VERSION "Version"

NS_ :

BS_:

BU_: Tester CCU INU ADC RRR RLR CCURT1 CCURT2 ZCUF ZCUL ZCUR ZCUT EMS IDM DCDC DCDCI IPS NIDU DCU2 OBC OPC LPC CPC EMCM GCU DCU IPU BMS EOP EVCC DCDC2 EDL SRS ECS EPS EPB RBM IBCS ICM IID IDC AMP WHUD ARHUD IMR FIMR CD IFC FAPA PAS PCS SCMF SCMR SCMRL SCMRR MFS DRM FCP RCP LBMSAD AVAS DLPFL FBLCM FLISD FLLCM FRLCM RLLCMA RLLCMB RRLCMA RRLCMB RLISD DLPML DLPMR TRM PSDL PSDR FLDCM FRDCM HVSPRL HVSPRR RFR SBM WCM ETC TBOX2 TBOX RLBMS EBU FLPDM RLPDM FRPDM RRPDM FLOAR FROAR RLOAR RROAR EOSL EOSR EOST PRBU RT1_C0 OTAWL RT2_C3 IDUR PHUDD RAS CBM PLGM TMC LPC2 SAS RCICP SCMRM SCMT SLMRL SLMRR IDU RRISD DSASBM LBMS RT1_C1

BO_ 825 CCU_5: 64 CCU
 SG_ WW_FwpFaultSt : 34|1@0+ (1,0) [0|1] ""  ICM,IDC,ADC,IFC,SCMF
 SG_ WW_RwpFaultSt : 33|1@0+ (1,0) [0|1] ""  ICM,IDC,ADC,IFC,SCMF
 SG_ WW_FwshFaultSt : 32|1@0+ (1,0) [0|1] ""  ICM,IDC,ADC,IFC,SCMF
 SG_ WW_RwshFaultSt : 47|1@0+ (1,0) [0|1] ""  ICM,IDC,ADC,IFC,SCMF
 SG_ WW_FwpAutoModeSt : 46|1@0+ (1,0) [0|1] ""  ICM,IDC,ADC,IFC,SCMF
 SG_ WW_RainFallLevel : 391|4@0+ (1,0) [0|15] ""  CCURT1,RT1_C0,RT1_C1,ZCUF,ZCUL,ZCUR,ZCUT,ICM,IDC,ADC,IFC,SCMF
 SG_ RLS_LightOnReq : 387|1@0+ (1,0) [0|1] ""  ZCUL,ZCUR,IDC,ADC,IFC,SCMF,FLISD,FLLCM,FRLCM,RLLCMA,RLLCMB,RRLCMA,RRLCMB
 SG_ RLS_LampOnReqValid : 386|1@0+ (1,0) [0|1] ""  IDC,ADC,IFC,SCMF
 SG_ RLS_WiperSpd : 385|4@0+ (1,0) [0|15] ""  IDC,ADC,IFC,SCMF
 SG_ RLS_AMBBrightness : 298|14@0+ (6,0) [0|98286] "Lux"  IDC,WHUD,ARHUD,ADC,IFC,SCMF
 SG_ RLS_FWBrightness : 413|14@0+ (6,0) [0|98286] ""  IDC,WHUD,ARHUD,ADC,IFC,SCMF
 SG_ RLS_RainfallLevel : 439|4@0+ (1,0) [0|15] ""  ICM,IDC,ADC,IFC,SCMF
 SG_ RLS_RSErr : 400|1@0+ (1,0) [0|1] ""  ICM,IDC,ADC,IFC,SCMF
 SG_ RLS_LSErr : 401|1@0+ (1,0) [0|1] ""  ZCUR,ICM,IDC,ADC,IFC,SCMF
 SG_ PM_AUTHPstState : 469|1@0+ (1,0) [0|1] ""  CCURT1,RT1_C0,ADC,IFC,SCMF
 SG_ CCU_FuncReq_SentryMod : 146|1@0+ (1,0) [0|1] ""  IDC,ADC,SCMF
 SG_ RLS_WindShieldHum : 119|8@0+ (0.5,-0.5) [0|100] "%"  ADC,SCMF
 SG_ RLS_WindShieldTem : 127|8@0+ (0.5,-40) [-40|86.5] "℃"  ADC,SCMF
 SG_ RLS_DewPoint : 135|8@0+ (0.5,-40) [-40|86.5] "℃"  ADC,SCMF
 SG_ CCU_ModeSuppressSts : 369|2@0+ (1,0) [0|2] ""  IDC,ADC,SCMF
 SG_ RLS_HUTErr : 426|1@0+ (1,0) [0|1] ""  ADC,SCMF
 SG_ SR_SunroofCurrentPst : 511|8@0+ (0.5,0) [0|255] "%"  ZCUT,IDC,IMR,FIMR,ADC,SCMF

BO_ 291 CCU_6: 64 CCU
 SG_ CCU_6_CRC : 7|16@0+ (1,0) [0|65535] ""  ZCUF,ZCUL,ADC,IFC,FAPA,PLGM
 SG_ CCU_6_Counter : 23|8@0+ (1,0) [0|255] ""  ZCUF,ZCUL,ADC,IFC,FAPA,PLGM
 SG_ ATWS_ATWSAlarmReq : 31|2@0+ (1,0) [0|3] ""  CCURT1,RT1_C0,ICM,IDC,ADC,IFC,FAPA
 SG_ ATWS_ATWSSt : 26|3@0+ (1,0) [0|7] ""  CCURT1,RT1_C0,RT1_C1,OTAWL,ZCUR,ICM,IDC,ADC,IFC,FAPA,RRR,RLR,PLGM
 SG_ WW_FrontWasherCmd : 39|2@0+ (1,0) [0|3] ""  CCURT1,ZCUF,ZCUL,ADC,IFC,FAPA
 SG_ WW_FrtWiperAutoAvl : 56|1@0+ (1,0) [0|1] ""  ADC,IFC,FAPA
 SG_ WW_FrontWiperCmd_Speed : 85|2@0+ (1,0) [0|3] ""  CCURT1,ZCUF,ZCUL,ADC,IFC,FAPA
 SG_ WW_RearWiperCtrlSt : 107|3@0+ (1,0) [0|7] ""  CCURT1,ZCUF,ZCUL,ZCUR,ZCUT,ICM,IDC,ADC,IFC,FAPA
 SG_ WW_FrontWiperCtrlSt : 111|3@0+ (1,0) [0|7] ""  CCURT1,ZCUF,ZCUL,ZCUR,ZCUT,EMS,ICM,IDC,ADC,IFC,FAPA
 SG_ WW_FrontWiperCtrlSrc : 115|3@0+ (1,0) [0|7] ""  CCURT1,ZCUF,ZCUL,ZCUR,ZCUT,ICM,IDC,ADC,FAPA
 SG_ WW_RearWiperCtrlSrc : 112|3@0+ (1,0) [0|7] ""  CCURT1,ZCUF,ZCUL,ZCUR,ZCUT,ICM,IDC,ADC,IFC,FAPA
 SG_ WW_RearCamWasherVKResp : 125|2@0+ (1,0) [0|3] ""  ICM,IDC,ADC,IFC,FAPA
 SG_ WW_RearCamWasherVRResp : 123|2@0+ (1,0) [0|3] ""  ICM,IDC,ADC,IFC,FAPA

BO_ 865 CCU_7: 64 CCU
 SG_ EL_ReverseLightCtrlCmd : 30|1@0+ (1,0) [0|1] ""  CCURT1,ZCUR,ZCUT,ADC,IFC,FAPA,TRM
 SG_ EL_SideBrkLightCtrlCmd : 29|1@0+ (1,0) [0|1] ""  CCURT1,RT1_C1,ZCUF,ZCUL,ZCUR,ZCUT,IDC,ADC,IFC,FAPA,PCS,RLLCMA,RLLCMB,RRLCMA,RRLCMB,TRM
 SG_ EL_LeftLowBeamCtrlCmd : 36|1@0+ (1,0) [0|1] ""  CCURT1,ZCUF,ZCUL,ADC,IFC,FAPA
 SG_ EL_RightLowBeamCtrlCmd : 35|1@0+ (1,0) [0|1] ""  CCURT1,ZCUF,ZCUL,ADC,IFC,FAPA
 SG_ EL_PositionLightCtrlSource : 34|3@0+ (1,0) [0|7] ""  CCURT1,ZCUF,ZCUL,ZCUR,ZCUT,ICM,IDC,RCICP,ADC,IFC,FAPA,MFS,FCP,TRM
 SG_ EL_LeftHighBeamCtrlCmd : 55|1@0+ (1,0) [0|1] ""  CCURT1,ZCUF,ZCUL,ADC,IFC,FAPA
 SG_ EL_RightHighBeamCtrlCmd : 54|1@0+ (1,0) [0|1] ""  CCURT1,ZCUF,ZCUL,ADC,IFC,FAPA
 SG_ EL_LowBeamCtrlSource : 53|3@0+ (1,0) [0|7] ""  CCURT1,ZCUF,ZCUL,ZCUR,ZCUT,ADC,IFC,FAPA
 SG_ EL_RearFogLightCtrlSource : 50|3@0+ (1,0) [0|7] ""  CCURT1,ZCUR,ZCUT,ADC,IFC,FAPA,TRM
 SG_ EL_HighBeamCtrlSource : 61|3@0+ (1,0) [0|7] ""  CCURT1,ZCUF,ZCUL,ADC,IFC,FAPA
 SG_ EL_FrontFogLightCtrlSource : 71|3@0+ (1,0) [0|7] ""  CCURT1,ZCUF,ZCUL,ZCUR,ZCUT,ADC,IFC,FAPA
 SG_ EL_LicencePlateLightCtrlSource : 84|3@0+ (1,0) [0|7] ""  CCURT1,ZCUR,ZCUT,ADC,IFC,FAPA
 SG_ EL_FlasherCtrlSource : 95|4@0+ (1,0) [0|15] ""  CCURT1,RT1_C0,ZCUF,ZCUL,ZCUR,ZCUT,SRS,ADC,IFC,FAPA,DLPML,DLPMR,TRM
 SG_ EL_FADASLightCtrlCmd : 130|1@0+ (1,0) [0|1] ""  ZCUF,ZCUL,ZCUR,ZCUT,ADC,FAPA
 SG_ EL_RADASLightCtrlCmd : 131|1@0+ (1,0) [0|1] ""  ZCUF,ZCUL,ZCUR,ZCUT,ADC,FAPA
 SG_ EL_IHBColourSt : 155|2@0+ (1,0) [0|3] ""  IID,IDC,PHUDD,ADC,IFC,FAPA
 SG_ EL_AutoHighBeamCtrlSt : 128|1@0+ (1,0) [0|1] ""  CCURT1,ADC,IFC,FAPA
 SG_ EL_ADBEnable : 252|1@0+ (1,0) [0|1] ""  IDC,ADC,IFC,FAPA
 SG_ EL_ADC_2_VERFailFlag : 175|1@0+ (1,0) [0|1] ""  ADC,IFC,FAPA
 SG_ EL_ADC_4_New_VERFailFlag : 174|1@0+ (1,0) [0|1] ""  ADC,IFC,FAPA
 SG_ EL_ADC_8_VERFailFlag : 173|1@0+ (1,0) [0|1] ""  ADC,IFC,FAPA
 SG_ EL_HeadLightLevelingSWSt : 467|4@0+ (1,0) [0|15] ""  CCURT1,ICM,IDC,ADC,IFC,FAPA
 SG_ EL_LeftTurnLightStForDisp : 478|1@0+ (1,0) [0|1] ""  CCURT1,IID,IDC,PHUDD,ADC,IFC,FAPA,RRR,RLR,PCS,DLPML,DLPMR
 SG_ EL_RightTurnLightStForDisp : 477|1@0+ (1,0) [0|1] ""  CCURT1,IID,IDC,PHUDD,ADC,IFC,FAPA,RRR,RLR,PCS,DLPML,DLPMR
 SG_ EL_PositionLightStForDisp : 476|1@0+ (1,0) [0|1] ""  CCURT1,RT1_C1,ZCUL,ZCUR,ZCUT,IID,IDC,PHUDD,WHUD,ARHUD,ADC,IFC,FAPA,PCS,MFS,FCP
 SG_ EL_FrontFogLightStForDisp : 475|1@0+ (1,0) [0|1] ""  CCURT1,IDC,ADC,IFC,FAPA,PCS
 SG_ EL_RearFogLightStForDisp : 474|1@0+ (1,0) [0|1] ""  CCURT1,ZCUR,IDC,ADC,IFC,FAPA,PCS,RCP
 SG_ EL_LowBeamStForDisp : 473|1@0+ (1,0) [0|1] ""  CCURT1,RT1_C1,IDC,ADC,IFC,FAPA,PCS,DLPML,DLPMR
 SG_ EL_HighBeamStForDisp : 472|1@0+ (1,0) [0|1] ""  CCURT1,RT1_C1,IID,IDC,PHUDD,ADC,IFC,FAPA,PCS
 SG_ EL_HeadLightSWSt : 510|2@0+ (1,0) [0|3] ""  ZCUR,IDC,ADC,FAPA

BO_ 293 CCU_8: 64 CCU
 SG_ TPMS_FrontLeftTireBlowout : 193|2@0+ (1,0) [0|3] ""  CCURT1,RT1_C0,RT1_C1,IDC,ADC,IFC,FAPA
 SG_ TPMS_FrontRightTireBlowout : 195|2@0+ (1,0) [0|3] ""  CCURT1,RT1_C0,RT1_C1,IDC,ADC,IFC,FAPA
 SG_ TPMS_RearRightTireBlowout : 197|2@0+ (1,0) [0|3] ""  CCURT1,RT1_C0,RT1_C1,IDC,ADC,IFC,FAPA
 SG_ TPMS_RearLeftTireBlowout : 199|2@0+ (1,0) [0|3] ""  CCURT1,RT1_C0,RT1_C1,IDC,ADC,IFC,FAPA
 SG_ TPMS_FrontLeftTirePressure : 207|8@0+ (1.373,0) [0|350.115] "kpa"  CCURT1,RT1_C0,RT1_C1,ICM,IDC,ADC,FAPA
 SG_ TPMS_FrontRightTirePressure : 215|8@0+ (1.373,0) [0|350.115] "kpa"  CCURT1,RT1_C0,RT1_C1,ICM,IDC,ADC,FAPA
 SG_ TPMS_RearRightTirePressure : 223|8@0+ (1.373,0) [0|350.115] "kpa"  CCURT1,RT1_C0,RT1_C1,ICM,IDC,ADC,FAPA
 SG_ TPMS_RearLeftTirePressure : 231|8@0+ (1.373,0) [0|350.115] "kpa"  CCURT1,RT1_C0,RT1_C1,ICM,IDC,ADC,FAPA
 SG_ TPMS_TireWarningLamp : 295|1@0+ (1,0) [0|1] ""  CCURT1,RT1_C0,RT1_C1,SRS,ICM,IID,IDC,PHUDD,ADC,IFC,FAPA
 SG_ TPMS_SystemWarningLamp : 310|1@0+ (1,0) [0|1] ""  CCURT1,RT1_C0,RT1_C1,SRS,ICM,IID,IDC,PHUDD,ADC,IFC,FAPA

BO_ 294 CCU_9: 64 CCU
 SG_ LCK_DriverDoorAjarSt : 31|1@0+ (1,0) [0|1] ""  CCURT1,RT1_C0,RT1_C1,OTAWL,ZCUF,ZCUL,ZCUR,ZCUT,ECS,IBCS,ICM,IDC,IMR,FIMR,ADC,IFC,FAPA,PCS
 SG_ LCK_PassengerDoorAjarSt : 30|1@0+ (1,0) [0|1] ""  CCURT1,RT1_C0,OTAWL,ZCUL,ZCUR,ECS,ICM,IDC,IMR,FIMR,ADC,IFC,FAPA,PCS
 SG_ LCK_DriverDoorLockSt : 29|1@0+ (1,0) [0|1] ""  CCURT1,RT1_C0,OTAWL,ZCUL,ZCUR,ZCUT,ECS,ICM,IDC,IMR,FIMR,ADC,IFC,FAPA
 SG_ LCK_PassengerDoorLockSt : 28|1@0+ (1,0) [0|1] ""  CCURT1,RT1_C0,OTAWL,ZCUL,ZCUR,ZCUT,ECS,ICM,IDC,IMR,FIMR,ADC,IFC,FAPA
 SG_ LCK_VehicleDoorAjarSt : 27|2@0+ (1,0) [0|3] ""  CCURT1,RT1_C1,OTAWL,ZCUL,ZCUR,ZCUT,IDC,ADC,IFC,FAPA
 SG_ LCK_VehicleDoorLockSt : 25|2@0+ (1,0) [0|3] ""  CCURT1,RT1_C0,RT1_C1,OTAWL,ZCUF,ZCUL,ZCUR,ZCUT,ICM,IDC,IMR,FIMR,ADC,IFC,FAPA,PRBU
 SG_ LCK_VehicleChildSaftyLockSt : 39|1@0+ (1,0) [0|1] ""  CCURT1,ZCUL,ICM,IDC,ADC,IFC,FAPA
 SG_ LCK_VehicleChildSaftyLockedIndicate : 38|1@0+ (1,0) [0|1] ""  CCURT1,ZCUL,ICM,IDC,ADC,IFC,FAPA
 SG_ CCU_9_FreshnessValue : 455|16@0+ (1,0) [0|255] ""  CCURT1,OTAWL,ZCUF,ZCUL,ZCUR,ZCUT,IDC,ADC,IFC,FAPA
 SG_ CCU_9_MAC_Check : 471|48@0+ (1,0) [0|255] ""  CCURT1,OTAWL,ZCUF,ZCUL,ZCUR,ZCUT,IDC,ADC,IFC,FAPA

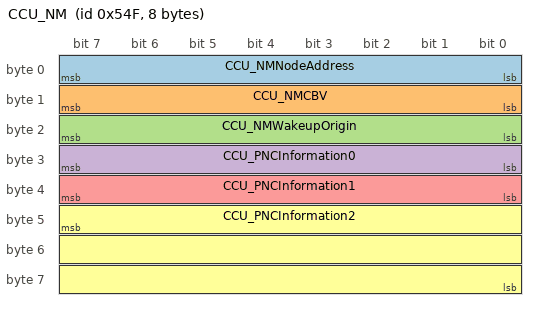
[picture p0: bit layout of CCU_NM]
BO_ 1359 CCU_NM: 8 CCU
 SG_ CCU_NMNodeAddress : 7|8@0+ (1,0) [0|255] ""  CCURT1,TMC,ZCUF,ZCUL,ZCUR,ZCUT,EMS,IPS,NIDU,BMS,EVCC,ECS,CBM,RBM,IBCS,ICM,IID,IDC,PHUDD,AMP,CD,ADC,FAPA,SCMR,SCMRL,SCMRR,SCMRM,SCMT,MFS,SLMRL,SLMRR,IDU,LBMSAD,PLGM,PSDL,PSDR,FLDCM,FRDCM,LBMS,TBOX,RLBMS,EBU,FLPDM,RLPDM,FRPDM,RRPDM
 SG_ CCU_NMCBV : 15|8@0+ (1,0) [0|0] ""  CCURT1,TMC,ZCUF,ZCUL,ZCUR,ZCUT,EMS,IPS,NIDU,BMS,EVCC,ECS,CBM,RBM,IBCS,ICM,IID,IDC,PHUDD,AMP,CD,ADC,FAPA,SCMR,SCMRL,SCMRR,SCMRM,SCMT,MFS,SLMRL,SLMRR,IDU,LBMSAD,PLGM,PSDL,PSDR,FLDCM,FRDCM,LBMS,TBOX,RLBMS,EBU,FLPDM,RLPDM,FRPDM,RRPDM
 SG_ CCU_NMWakeupOrigin : 23|8@0+ (1,0) [0|255] ""  CCURT1,TMC,ZCUF,ZCUL,ZCUR,ZCUT,EMS,IPS,NIDU,BMS,EVCC,ECS,CBM,RBM,IBCS,ICM,IID,IDC,PHUDD,AMP,CD,ADC,FAPA,SCMR,SCMRL,SCMRR,SCMRM,SCMT,MFS,SLMRL,SLMRR,IDU,LBMSAD,PLGM,PSDL,PSDR,FLDCM,FRDCM,LBMS,TBOX,RLBMS,EBU
 SG_ CCU_PNCInformation0 : 31|8@0+ (1,0) [0|255] ""  CCURT1,TMC,ZCUF,ZCUL,ZCUR,ZCUT,EMS,IPS,NIDU,BMS,EVCC,ECS,CBM,RBM,IBCS,ICM,IID,IDC,PHUDD,AMP,CD,ADC,FAPA,SCMR,SCMRL,SCMRR,SCMRM,SCMT,MFS,SLMRL,SLMRR,IDU,LBMSAD,PLGM,PSDL,PSDR,FLDCM,FRDCM,LBMS,TBOX,RLBMS,EBU,FLPDM,RLPDM,FRPDM,RRPDM
 SG_ CCU_PNCInformation1 : 39|8@0+ (1,0) [0|255] ""  CCURT1,TMC,ZCUF,ZCUL,ZCUR,ZCUT,EMS,IPS,NIDU,BMS,EVCC,ECS,CBM,RBM,IBCS,ICM,IID,IDC,PHUDD,AMP,CD,ADC,FAPA,SCMR,SCMRL,SCMRR,SCMRM,SCMT,MFS,SLMRL,SLMRR,IDU,LBMSAD,PLGM,PSDL,PSDR,FLDCM,FRDCM,LBMS,TBOX,RLBMS,EBU,FLPDM,RLPDM,FRPDM,RRPDM
 SG_ CCU_PNCInformation2 : 47|24@0+ (1,0) [0|0] ""  CCURT1,TMC,ZCUF,ZCUL,ZCUR,ZCUT,EMS,IPS,NIDU,BMS,EVCC,ECS,CBM,RBM,IBCS,ICM,IID,IDC,PHUDD,AMP,CD,ADC,FAPA,SCMR,SCMRL,SCMRR,SCMRM,SCMT,MFS,SLMRL,SLMRR,IDU,LBMSAD,PLGM,PSDL,PSDR,FLDCM,FRDCM,LBMS,TBOX,RLBMS,EBU,FLPDM,RLPDM,FRPDM,RRPDM

BO_ 615 CCU_BCS_1_C: 64 CCU
 SG_ BCS_1_CRC : 7|16@0+ (1,0) [0|65535] ""  ZCUF,ZCUL,ZCUR,ZCUT,ICM,IID,IDC,INU,ADC,IFC,FAPA,RRR,RLR
 SG_ BCS_1_Counter : 23|8@0+ (1,0) [0|255] ""  ZCUF,ZCUL,ZCUR,ZCUT,ICM,IID,IDC,INU,ADC,IFC,FAPA,RRR,RLR
 SG_ BCS_FLWheelSpd : 31|13@0+ (0.05625,0) [0|240] "km/h"  ZCUF,ZCUL,ZCUR,ZCUT,EMS,IDC,INU,ADC,IFC,FAPA,RRR,RLR,PCS,TBOX
 SG_ BCS_FLWheelSpdVD : 34|1@0+ (1,0) [0|1] ""  ZCUF,ZCUL,ZCUR,ZCUT,EMS,INU,ADC,IFC,FAPA,RRR,RLR,PCS,TBOX
 SG_ BCS_FLWheelRotatedDirection : 33|1@0+ (1,0) [0|1] ""  IDC,INU,ADC,IFC,FAPA,RRR,RLR,PCS
 SG_ BCS_FLWheelRotatedDirectionVD : 32|1@0+ (1,0) [0|1] ""  INU,ADC,IFC,FAPA,RRR,RLR,PCS
 SG_ BCS_FRWheelSpd : 47|13@0+ (0.05625,0) [0|240] "km/h"  ZCUF,ZCUL,ZCUR,ZCUT,EMS,IDC,INU,ADC,IFC,FAPA,RRR,RLR,PCS,TBOX
 SG_ BCS_FRWheelSpdVD : 50|1@0+ (1,0) [0|1] ""  ZCUF,ZCUL,ZCUR,ZCUT,EMS,INU,ADC,IFC,FAPA,RRR,RLR,PCS,TBOX
 SG_ BCS_FRWheelRotatedDirection : 49|1@0+ (1,0) [0|1] ""  IDC,INU,ADC,IFC,FAPA,RRR,RLR,PCS
 SG_ BCS_FRWheelRotatedDirectionVD : 48|1@0+ (1,0) [0|1] ""  INU,ADC,IFC,FAPA,RRR,RLR,PCS
 SG_ BCS_RLWheelSpd : 63|13@0+ (0.05625,0) [0|240] "km/h"  ZCUF,ZCUL,ZCUR,ZCUT,EMS,IDC,INU,ADC,IFC,FAPA,RRR,RLR,PCS,TBOX
 SG_ BCS_RLWheelSpdVD : 66|1@0+ (1,0) [0|1] ""  ZCUF,ZCUL,ZCUR,ZCUT,EMS,INU,ADC,IFC,FAPA,RRR,RLR,PCS,TBOX
 SG_ BCS_RLWheelRotatedDirection : 65|1@0+ (1,0) [0|1] ""  IDC,INU,ADC,IFC,FAPA,RRR,RLR,PCS
 SG_ BCS_RLWheelRotatedDirectionVD : 64|1@0+ (1,0) [0|1] ""  INU,ADC,IFC,FAPA,RRR,RLR,PCS
 SG_ BCS_RRWheelSpd : 79|13@0+ (0.05625,0) [0|240] "km/h"  ZCUF,ZCUL,ZCUR,ZCUT,EMS,IDC,INU,ADC,IFC,FAPA,RRR,RLR,PCS,TBOX
 SG_ BCS_RRWheelSpdVD : 82|1@0+ (1,0) [0|1] ""  ZCUF,ZCUL,ZCUR,ZCUT,EMS,INU,ADC,IFC,FAPA,RRR,RLR,PCS,TBOX
 SG_ BCS_RRWheelRotatedDirection : 81|1@0+ (1,0) [0|1] ""  IDC,INU,ADC,IFC,FAPA,RRR,RLR,PCS
 SG_ BCS_RRWheelRotatedDirectionVD : 80|1@0+ (1,0) [0|1] ""  INU,ADC,IFC,FAPA,RRR,RLR,PCS
 SG_ BCS_HHCCtrlSt : 95|1@0+ (1,0) [0|1] ""  EMS,ADC,IFC,FAPA
 SG_ BCS_HDCCtrlSt : 93|2@0+ (1,0) [0|3] ""  ICM,IDC,ADC,IFC,FAPA
 SG_ BCS_HDCErrSt : 91|1@0+ (1,0) [0|1] ""  ICM,IID,IDC,PHUDD,ADC,IFC,FAPA
 SG_ BCS_FLWheelSpdEdgesSum : 103|12@0+ (1,0) [0|4095] ""  ZCUF,ZCUL,ZCUR,ZCUT,ICM,IID,IDC,PHUDD,ADC,IFC,FAPA,RRR,RLR,PCS
 SG_ BCS_FRWheelSpdEdgesSum : 107|12@0+ (1,0) [0|4095] ""  ZCUF,ZCUL,ZCUR,ZCUT,IID,IDC,PHUDD,ADC,IFC,FAPA,RRR,RLR,PCS
 SG_ BCS_RLWheelSpdEdgesSum : 127|12@0+ (1,0) [0|4095] ""  ZCUF,ZCUL,ZCUR,ZCUT,ICM,IID,IDC,PHUDD,ADC,IFC,FAPA,RRR,RLR,PCS
 SG_ BCS_RRWheelSpdEdgesSum : 131|12@0+ (1,0) [0|4095] ""  ZCUF,ZCUL,ZCUR,ZCUT,IID,IDC,PHUDD,ADC,IFC,FAPA,RRR,RLR,PCS
 SG_ BCS_FLWheelSpdEdgesSumVD : 151|1@0+ (1,0) [0|1] ""  ZCUF,ZCUL,ZCUR,ZCUT,ICM,IID,IDC,PHUDD,ADC,IFC,FAPA,RRR,RLR,PCS
 SG_ BCS_FRWheelSpdEdgesSumVD : 150|1@0+ (1,0) [0|1] ""  ZCUF,ZCUL,ZCUR,ZCUT,ADC,IFC,FAPA,RRR,RLR,PCS
 SG_ BCS_RLWheelSpdEdgesSumVD : 149|1@0+ (1,0) [0|1] ""  ZCUF,ZCUL,ZCUR,ZCUT,ICM,IID,IDC,PHUDD,ADC,IFC,FAPA,RRR,RLR,PCS
 SG_ BCS_RRWheelSpdEdgesSumVD : 148|1@0+ (1,0) [0|1] ""  ZCUF,ZCUL,ZCUR,ZCUT,ADC,IFC,FAPA,RRR,RLR,PCS
 SG_ BCS_FLWheelRotatedDirectionAPA : 147|2@0+ (1,0) [0|3] ""  ADC,IFC,FAPA,PAS
 SG_ BCS_FRWheelRotatedDirectionAPA : 145|2@0+ (1,0) [0|3] ""  ADC,IFC,FAPA,PAS
 SG_ BCS_RLWheelRotatedDirectionAPA : 159|2@0+ (1,0) [0|3] ""  ADC,IFC,FAPA,PAS
 SG_ BCS_RRWheelRotatedDirectionAPA : 157|2@0+ (1,0) [0|3] ""  ADC,IFC,FAPA,PAS
 SG_ BCS_ParkingReqToEPB : 155|2@0+ (1,0) [0|3] ""  ZCUF,ZCUL,ZCUR,ZCUT,ADC,FAPA
 SG_ BCS_VDCOff : 153|1@0+ (1,0) [0|1] ""  ICM,IID,IDC,PHUDD,ADC,IFC,FAPA
 SG_ BCS_AVHSt : 152|1@0+ (1,0) [0|1] ""  ZCUF,ZCUL,ZCUR,ZCUT,ICM,IID,IDC,PHUDD,ADC,IFC,FAPA,FLISD,FLLCM,FRLCM,RLISD,RRISD
 SG_ BCS_AVHAvailable : 166|1@0+ (1,0) [0|1] ""  ZCUF,ZCUL,ZCUR,ZCUT,ICM,IDC,ADC,IFC,FAPA
 SG_ BCS_TCSOff : 165|1@0+ (1,0) [0|1] ""  ICM,IID,IDC,PHUDD,ADC,IFC,FAPA,RRR,RLR
 SG_ BCS_BrakeOverHeat : 160|1@0+ (1,0) [0|1] ""  ADC,IFC,FAPA
 SG_ BCS_ABAactive : 175|1@0+ (1,0) [0|1] ""  ADC,IFC,FAPA
 SG_ BCS_ABAavailable : 174|1@0+ (1,0) [0|1] ""  ADC,IFC,FAPA
 SG_ BCS_ABPActive : 173|1@0+ (1,0) [0|1] ""  ADC,IFC,FAPA
 SG_ BCS_ABPAvailable : 172|1@0+ (1,0) [0|1] ""  ADC,IFC,FAPA
 SG_ BCS_AEBActive : 171|1@0+ (1,0) [0|1] ""  ADC,IFC,FAPA,RRR,RLR
 SG_ BCS_AEBAvailable : 170|1@0+ (1,0) [0|1] ""  ADC,IFC,FAPA,RRR,RLR
 SG_ BCS_AWBActive : 169|1@0+ (1,0) [0|1] ""  ADC,IFC,FAPA
 SG_ BCS_AWBAvailable : 168|1@0+ (1,0) [0|1] ""  ADC,IFC,FAPA
 SG_ BCS_VehicleStandStillSt : 180|2@0+ (1,0) [0|3] ""  ADC,IFC,FAPA,RRR,RLR
 SG_ BCS_AEBBAActive : 178|1@0+ (1,0) [0|1] ""  ADC,IFC,FAPA
 SG_ IPB_InputRodStroke : 363|10@0+ (0.05,-5) [-5|46.15] "mm"  ICM,IDC,AMP,ADC,IFC,FAPA
 SG_ IPB_InputRodStrokeSt : 379|1@0+ (1,0) [0|1] ""  ICM,IDC,AMP,ADC,IFC,FAPA
 SG_ BCS_RAEBActive : 378|1@0+ (1,0) [0|1] ""  ADC,FAPA
 SG_ BCS_RAEBAvailable : 377|1@0+ (1,0) [0|1] ""  ADC,FAPA
 SG_ IPB_PlungerPressureSt : 376|1@0+ (1,0) [0|1] ""  ZCUF,ZCUL,ZCUR,ZCUT,EMS,ADC,IFC,FAPA,RRR,RLR
 SG_ IPB_PlungerPressure : 391|12@0+ (0.3,-5) [-5|301.9] "bar"  ZCUF,ZCUL,ZCUR,ZCUT,EMS,ADC,IFC,FAPA,RRR,RLR
 SG_ BCS_2ParkDrvBrkOverrideFlg : 201|2@0+ (1,0) [0|3] ""  ADC,IFC,FAPA
 SG_ BCS_BrkTqCtrlAvlDrivingRdn : 405|3@0+ (1,0) [0|7] ""  ADC
 SG_ BCS_BrkTqCtrlActvRdn : 407|2@0+ (1,0) [0|3] ""  ADC
 SG_ BCS_L3CommunicationVld : 392|1@0+ (1,0) [0|1] ""  ADC
 SG_ BCS_LFIActiveSt : 402|1@0+ (1,0) [0|1] ""  ADC,IFC

BO_ 352 CCU_BCS_2_C: 64 CCU
 SG_ BCS_2_CRC : 7|16@0+ (1,0) [0|65535] ""  ZCUF,ZCUL,ZCUR,ZCUT,IPS,NIDU,DCU2,IDUR,OBC,DCU,IPU,ICM,IDC,INU,ADC,IFC,FAPA,RRR,RLR,DRM,IDU,FLISD,RLLCMA,RLLCMB,RRLCMA,RRLCMB,PLGM,TRM,PSDL,PSDR,EBU,FLPDM,RLPDM,FRPDM,RRPDM
 SG_ BCS_2_Counter : 23|8@0+ (1,0) [0|255] ""  ZCUF,ZCUL,ZCUR,ZCUT,IPS,NIDU,DCU2,IDUR,OBC,DCU,IPU,ICM,IDC,INU,ADC,IFC,FAPA,RRR,RLR,DRM,IDU,FLISD,FLLCM,FRLCM,RLLCMA,RLLCMB,RRLCMA,RRLCMB,PLGM,TRM,EBU,FLPDM,RLPDM,FRPDM,RRPDM
 SG_ BCS_VehSpd : 31|13@0+ (0.05625,0) [0|240] "km/h"  TMC,ZCUF,ZCUL,ZCUR,ZCUT,EMS,DCDC,DCDCI,IPS,NIDU,DCU2,IDUR,OBC,OPC,LPC,LPC2,CPC,EMCM,GCU,DCU,IPU,BMS,EVCC,DCDC2,EDL,ICM,IID,IDC,PHUDD,AMP,IMR,FIMR,INU,ADC,IFC,FAPA,RRR,RLR,PAS,PCS,SCMR,SCMRL,SCMRR,SCMRM,SCMT,MFS,DRM,IDU,FCP,RCP,LBMSAD,AVAS,DLPFL,FBLCM,FLISD,FLLCM,FRLCM,RLLCMA,RLLCMB,RRLCMA,RRLCMB,RLISD,RRISD,DLPML,DSASBM,DLPMR,PLGM,TRM,PSDL,PSDR,HVSPRL,HVSPRR,LBMS,TBOX2,TBOX,FLPDM,RLPDM,FRPDM,RRPDM,FLOAR,FROAR,RLOAR,RROAR,PRBU
 SG_ BCS_VehSpdVD : 34|1@0+ (1,0) [0|1] ""  TMC,ZCUF,ZCUL,ZCUR,ZCUT,EMS,DCDC,DCDCI,IPS,NIDU,DCU2,IDUR,OBC,OPC,LPC,LPC2,CPC,GCU,DCU,IPU,BMS,EVCC,DCDC2,ICM,IID,IDC,PHUDD,AMP,IMR,FIMR,INU,ADC,IFC,FAPA,RRR,RLR,PAS,SCMR,SCMRL,SCMRR,SCMRM,SCMT,MFS,DRM,IDU,FCP,RCP,LBMSAD,AVAS,DLPFL,FBLCM,FLISD,FLLCM,FRLCM,RLLCMA,RLLCMB,RRLCMA,RRLCMB,RLISD,RRISD,DLPML,DSASBM,DLPMR,PLGM,TRM,PSDL,PSDR,HVSPRL,HVSPRR,LBMS,TBOX,FLPDM,RLPDM,FRPDM,RRPDM,FLOAR,FROAR,RLOAR,RROAR,PRBU
 SG_ BCS_EBDActiveSt : 32|1@0+ (1,0) [0|1] ""  ZCUF,ZCUL,NIDU,DCU2,ADC,IFC,FAPA,RRR,RLR
 SG_ BCS_EBDFaultSt : 47|1@0+ (1,0) [0|1] ""  ZCUF,ZCUL,NIDU,DCU2,ICM,IID,IDC,PHUDD,ADC,IFC,FAPA
 SG_ BCS_ABSActiveSt : 46|1@0+ (1,0) [0|1] ""  ZCUF,ZCUL,NIDU,DCU2,IDUR,ADC,IFC,FAPA,RRR,RLR
 SG_ BCS_ABSFaultSt : 45|1@0+ (1,0) [0|1] ""  ZCUF,ZCUL,NIDU,DCU2,IDUR,ICM,IID,IDC,PHUDD,ADC,IFC,FAPA,TBOX
 SG_ BCS_TCSActiveSt : 44|1@0+ (1,0) [0|1] ""  ZCUF,ZCUL,ZCUR,ZCUT,NIDU,DCU2,IDUR,ICM,IID,IDC,PHUDD,ADC,IFC,FAPA,RRR,RLR
 SG_ BCS_TCSFaultSt : 43|1@0+ (1,0) [0|1] ""  ZCUF,ZCUL,ZCUR,ZCUT,NIDU,DCU2,IDUR,ICM,IID,IDC,PHUDD,ADC,IFC,FAPA,RRR,RLR
 SG_ BCS_VDCActiveSt : 42|1@0+ (1,0) [0|1] ""  ZCUF,ZCUL,NIDU,DCU2,IDUR,ICM,IID,IDC,PHUDD,ADC,IFC,FAPA,RRR,RLR,PCS
 SG_ BCS_VDCFaultSt : 41|1@0+ (1,0) [0|1] ""  ZCUF,ZCUL,NIDU,DCU2,IDUR,ICM,IID,IDC,PHUDD,ADC,IFC,FAPA,RRR,RLR
 SG_ BCS_PreAndRealVDCActiveSt : 67|1@0+ (1,0) [0|1] ""  ZCUF,ZCUL,ADC,IFC,FAPA
 SG_ BCS_RegenModulationAvailable : 64|1@0+ (1,0) [0|1] ""  ZCUF,ZCUL,NIDU,DCU2,IDUR,ADC,IFC,FAPA
 SG_ BCS_RegenModuleActive : 79|1@0+ (1,0) [0|1] ""  ZCUF,ZCUL,NIDU,DCU2,IDUR,ADC,IFC,FAPA
 SG_ BCS_RealTCSActiveSt : 95|1@0+ (1,0) [0|1] ""  IDC,ADC,IFC,FAPA
 SG_ BCS_TargetRecpTorqRq : 93|14@0+ (1,-6000) [-6000|6000] "Nm"  ZCUF,ZCUL,ADC,IFC,FAPA
 SG_ BCS_TargetRecpTorqRqSt : 111|2@0+ (1,0) [0|3] ""  ZCUF,ZCUL,ADC,IFC,FAPA
 SG_ BCS_CrbsActive : 105|1@0+ (1,0) [0|1] ""  ZCUF,ZCUL,ADC,IFC,FAPA
 SG_ IPB_BrakePedalStsVld : 224|1@0+ (1,0) [0|1] ""  ADC,IFC,FAPA
 SG_ IPB_BrakePedalSt : 227|2@0+ (1,0) [0|3] ""  ZCUF,ZCUL,ZCUR,ZCUT,ICM,IDC,ADC,IFC,FAPA,TBOX
 SG_ BCS_EngTorqDecFastRANm : 55|16@0+ (1,-30000) [-30000|30000] "Nm"  ADC,IFC,FAPA
 SG_ BCS_EngTorqIncRANm : 77|14@0+ (1,-6000) [-6000|10380] "Nm"  ADC,IFC,FAPA
 SG_ BCS_ESP2Park_DrvBrkOverrideFlg : 234|1@0+ (1,0) [0|1] ""  ADC,FAPA
 SG_ BCS_TargetRecpTorqRqFA : 197|14@0+ (1,-6000) [-6000|6000] "Nm"  ADC,IFC,FAPA
 SG_ BCS_TargetRecpTorqRqFASt : 215|2@0+ (1,0) [0|3] ""  ADC,IFC,FAPA
 SG_ BCS_TargetRecpTorqRqRA : 213|14@0+ (1,-6000) [-6000|6000] "Nm"  ADC,IFC,FAPA
 SG_ BCS_TargetRecpTorqRqRASt : 231|2@0+ (1,0) [0|3] ""  ADC,IFC,FAPA
 SG_ BCS_EngTorqDecActiveStRA : 233|1@0+ (1,0) [0|1] ""  NIDU,DCU2,IDUR,ADC,IFC,FAPA
 SG_ BCS_PrimBrkCDAAvailableSt : 274|3@0+ (1,0) [0|7] ""  ADC,IFC,FAPA
 SG_ BCS_PrimBrkCommuniSt : 287|1@0+ (1,0) [0|1] ""  ADC,IFC,FAPA
 SG_ BCS_PrimBrkActiveSt : 286|2@0+ (1,0) [0|3] ""  ZCUF,ZCUL,ZCUR,ZCUT,ADC,IFC,FAPA
 SG_ BCS_2ParkCddApActiveVehHld : 280|1@0+ (1,0) [0|1] ""  ADC,IFC,FAPA
 SG_ BCS_2ParkAPCStatus : 311|3@0+ (1,0) [0|7] ""  ZCUF,ZCUL,ZCUR,ZCUT,ADC,IFC,FAPA
 SG_ BCS_2ParkAPAavailability : 308|3@0+ (1,0) [0|7] ""  ADC,FAPA
 SG_ BCS_2ParkRPAAVPavailability : 305|2@0+ (1,0) [0|3] ""  ZCUF,ZCUL,ZCUR,ZCUT,ADC,FAPA
 SG_ BCS_2ParkAPCFailureSts : 319|3@0+ (1,0) [0|7] ""  ADC,FAPA
 SG_ BCS_APCMain2BackupReq : 316|1@0+ (1,0) [0|1] ""  ADC,FAPA
 SG_ BCS_PrimBrkCtrlUsedChannel : 315|2@0+ (1,0) [0|3] ""  ADC,IFC,FAPA
 SG_ BCS_PrimBrkCDAActiveSt : 313|1@0+ (1,0) [0|1] ""  ZCUF,ZCUL,ZCUR,ZCUT,ADC,IFC,FAPA
 SG_ BCS_PrimBrkDecCtrlActiveSt : 312|1@0+ (1,0) [0|1] ""  ZCUF,ZCUL,ZCUR,ZCUT,ADC,IFC,FAPA
 SG_ BCS_PrimBrkCDDAvailableSt : 330|2@0+ (1,0) [0|3] ""  ADC,IFC,FAPA
 SG_ BCS_EngTorqDecActiveStFA : 375|1@0+ (1,0) [0|1] ""  ADC,IFC,FAPA
 SG_ BCS_EngTorqIncActiveStFA : 383|1@0+ (1,0) [0|1] ""  ADC,IFC,FAPA
 SG_ IBCS_ADCNetErrorFb : 156|3@0+ (1,0) [0|7] ""  ADC,IFC,FAPA
 SG_ IBCS_NetModeResp : 158|2@0+ (1,0) [0|3] ""  ADC,FAPA
 SG_ BCS_EngTorqDecFastFA : 399|16@0+ (1,-30000) [-30000|30000] "Nm"  ADC,IFC,FAPA
 SG_ BCS_EngTorqIncFA : 415|16@0+ (1,-30000) [-30000|30000] "Nm"  ADC,IFC,FAPA

CM_ SG_ 825 WW_FwpFaultSt "Front Wiper Fault state";
CM_ SG_ 825 WW_RwpFaultSt "Rear Wiper Fault state";
CM_ SG_ 825 WW_FwshFaultSt "Front Washer Fault state";
CM_ SG_ 825 WW_RwshFaultSt "Rear Washer Fault state";
CM_ SG_ 825 WW_FwpAutoModeSt "Front Wiper Auto Mode state";
CM_ SG_ 825 WW_RainFallLevel "Rain Fall Level";
CM_ SG_ 825 RLS_LightOnReq "Switch on/off low beam request";
CM_ SG_ 825 RLS_LampOnReqValid "Lamp On Request signal valid";
CM_ SG_ 825 RLS_WiperSpd "Wiper speed mode";
CM_ SG_ 825 RLS_AMBBrightness "Ambient Light Brightness";
CM_ SG_ 825 RLS_FWBrightness "Forward Light Brightness";
CM_ SG_ 825 RLS_RainfallLevel "Rain level";
CM_ SG_ 825 RLS_RSErr "Error status rain sensor";
CM_ SG_ 825 RLS_LSErr "Error status light sensor";
CM_ SG_ 825 PM_AUTHPstState "位置授权开关状态";
CM_ SG_ 825 CCU_FuncReq_SentryMod "Sentry Mode Wake SOC of MDC";
CM_ SG_ 825 RLS_WindShieldHum "Data windshield humidity";
CM_ SG_ 825 RLS_WindShieldTem "Temperature of the windscreen in ℃";
CM_ SG_ 825 RLS_DewPoint "Dew Temperature of the windscreen in ℃";
CM_ SG_ 825 CCU_ModeSuppressSts "Sentry Mode Suppress Status";
CM_ SG_ 825 RLS_HUTErr "HT sensor status";
CM_ SG_ 825 SR_SunroofCurrentPst "Sunroof current Position";
CM_ SG_ 291 CCU_6_CRC "E2E Profile 5 CRC";
CM_ SG_ 291 CCU_6_Counter "E2E Profile 5 Counter";
CM_ SG_ 291 ATWS_ATWSAlarmReq "ATWS Alarm Request";
CM_ SG_ 291 ATWS_ATWSSt "ATWS status";
CM_ SG_ 291 WW_FrontWasherCmd "Front Washer driver command";
CM_ SG_ 291 WW_FrtWiperAutoAvl "Front wiper auto control available";
CM_ SG_ 291 WW_FrontWiperCmd_Speed "front wiper speed command";
CM_ SG_ 291 WW_RearWiperCtrlSt "Rear wiper control status";
CM_ SG_ 291 WW_FrontWiperCtrlSt "Front wiper control status";
CM_ SG_ 291 WW_FrontWiperCtrlSrc "Front wiper control source";
CM_ SG_ 291 WW_RearWiperCtrlSrc "Rear wiper control source";
CM_ SG_ 291 WW_RearCamWasherVKResp "Rear Camera Washer Request";
CM_ SG_ 291 WW_RearCamWasherVRResp "Rear Camera Washer Request";
CM_ SG_ 865 EL_ReverseLightCtrlCmd "Reverse light control command";
CM_ SG_ 865 EL_SideBrkLightCtrlCmd "Side brake light control command";
CM_ SG_ 865 EL_LeftLowBeamCtrlCmd "Left low beam control command";
CM_ SG_ 865 EL_RightLowBeamCtrlCmd "Right low beam control command";
CM_ SG_ 865 EL_PositionLightCtrlSource "Position light control source";
CM_ SG_ 865 EL_LeftHighBeamCtrlCmd "Left high beam control command";
CM_ SG_ 865 EL_RightHighBeamCtrlCmd "Right high beam control command";
CM_ SG_ 865 EL_LowBeamCtrlSource "Low beam control source";
CM_ SG_ 865 EL_RearFogLightCtrlSource "Rear fog light control source";
CM_ SG_ 865 EL_HighBeamCtrlSource "High beam control source";
CM_ SG_ 865 EL_FrontFogLightCtrlSource "Front fog lgiht control source";
CM_ SG_ 865 EL_LicencePlateLightCtrlSource "Licence plate light control source";
CM_ SG_ 865 EL_FlasherCtrlSource "Flasher control source";
CM_ SG_ 865 EL_FADASLightCtrlCmd "Front ADAS light control command";
CM_ SG_ 865 EL_RADASLightCtrlCmd "Rear ADAS light control command";
CM_ SG_ 865 EL_IHBColourSt "Intelligent high beam colour status";
CM_ SG_ 865 EL_ADBEnable "ADB enable";
CM_ SG_ 865 EL_ADC_2_VERFailFlag "ADC_2 Message Verification Fail Flag";
CM_ SG_ 865 EL_ADC_4_New_VERFailFlag "ADC_4_X Message Verification Fail Flag";
CM_ SG_ 865 EL_ADC_8_VERFailFlag "ADC_8 Message Verification Fail Flag";
CM_ SG_ 865 EL_HeadLightLevelingSWSt "Head light leveling manul adjust switch status";
CM_ SG_ 865 EL_LeftTurnLightStForDisp "Left turn light status";
CM_ SG_ 865 EL_RightTurnLightStForDisp "Right turn light status";
CM_ SG_ 865 EL_PositionLightStForDisp "Position light status";
CM_ SG_ 865 EL_FrontFogLightStForDisp "Front fog light status";
CM_ SG_ 865 EL_RearFogLightStForDisp "Rear fog light status";
CM_ SG_ 865 EL_LowBeamStForDisp "Low beam status";
CM_ SG_ 865 EL_HighBeamStForDisp "High beam status";
CM_ SG_ 865 EL_HeadLightSWSt "Headlight switch status";
CM_ SG_ 293 TPMS_FrontLeftTireBlowout "Front Left Tire Blow Out State";
CM_ SG_ 293 TPMS_FrontRightTireBlowout "Front Right Tire Blow Out State";
CM_ SG_ 293 TPMS_RearRightTireBlowout "Rear Right Tire Blow Out State";
CM_ SG_ 293 TPMS_RearLeftTireBlowout "Rear Left Tire Blow Out State";
CM_ SG_ 293 TPMS_FrontLeftTirePressure "FrontLeftTirePresssure";
CM_ SG_ 293 TPMS_FrontRightTirePressure "FrontRightTirePresssure";
CM_ SG_ 293 TPMS_RearRightTirePressure "RearRightTirePresssure";
CM_ SG_ 293 TPMS_RearLeftTirePressure "RearLeftTirePresssure";
CM_ SG_ 293 TPMS_TireWarningLamp "TireWarningLamp";
CM_ SG_ 293 TPMS_SystemWarningLamp "SystemWarningLamp";
CM_ SG_ 294 LCK_DriverDoorAjarSt "DriverDoorAjarST ";
CM_ SG_ 294 LCK_PassengerDoorAjarSt "PassengerDoorAjarST";
CM_ SG_ 294 LCK_DriverDoorLockSt "DriverDoorLockSt";
CM_ SG_ 294 LCK_PassengerDoorLockSt "PassengerDoorLockSt";
CM_ SG_ 294 LCK_VehicleDoorAjarSt "VehicleDoorAjarSt";
CM_ SG_ 294 LCK_VehicleDoorLockSt "VehicleDoorLockSt";
CM_ SG_ 294 LCK_VehicleChildSaftyLockSt "VehicleChildSaftyLockSt";
CM_ SG_ 294 LCK_VehicleChildSaftyLockedIndicate "VehicleChildSaftyLockedIndicate";
CM_ SG_ 294 CCU_9_FreshnessValue "Freshness value in SecOC security message";
CM_ SG_ 294 CCU_9_MAC_Check "MAC value in SecOC security message";
CM_ SG_ 1359 CCU_NMNodeAddress "CCU node address";
CM_ SG_ 1359 CCU_NMCBV "CCU Network management control bit vector";
CM_ SG_ 1359 CCU_NMWakeupOrigin "Origin of the wake up";
CM_ SG_ 1359 CCU_PNCInformation0 "PNC Information";
CM_ SG_ 1359 CCU_PNCInformation1 "PNC Information";
CM_ SG_ 1359 CCU_PNCInformation2 "PNC Information";
CM_ SG_ 615 BCS_1_CRC "E2E Profile 5 CRC";
CM_ SG_ 615 BCS_1_Counter "E2E Profile 5 Counter";
CM_ SG_ 615 BCS_FLWheelSpd "Current wheel speed information of front left wheel";
CM_ SG_ 615 BCS_FLWheelSpdVD "Quality/fault information to current wheel speed of front left wheel";
CM_ SG_ 615 BCS_FLWheelRotatedDirection "FL wheel rotate direction";
CM_ SG_ 615 BCS_FLWheelRotatedDirectionVD "FL wheel rotate direction validity";
CM_ SG_ 615 BCS_FRWheelSpd "Current wheel speed information of front right wheel";
CM_ SG_ 615 BCS_FRWheelSpdVD "Quality/fault information to current wheel speed of front right  wheel";
CM_ SG_ 615 BCS_FRWheelRotatedDirection "FR wheel rotate direction";
CM_ SG_ 615 BCS_FRWheelRotatedDirectionVD "FR wheel rotate direction validity";
CM_ SG_ 615 BCS_RLWheelSpd "Current wheel speed information of rear left wheel";
CM_ SG_ 615 BCS_RLWheelSpdVD "Quality/fault information to current wheel speed of rear left wheel";
CM_ SG_ 615 BCS_RLWheelRotatedDirection "RL wheel rotate direction";
CM_ SG_ 615 BCS_RLWheelRotatedDirectionVD "RL wheel rotate direction validity";
CM_ SG_ 615 BCS_RRWheelSpd "Current wheel speed information of rear right wheel";
CM_ SG_ 615 BCS_RRWheelSpdVD "Quality/fault information to current wheel speed of rear right wheel";
CM_ SG_ 615 BCS_RRWheelRotatedDirection "RR wheel rotate direction";
CM_ SG_ 615 BCS_RRWheelRotatedDirectionVD "RR wheel rotate direction validity";
CM_ SG_ 615 BCS_HHCCtrlSt "HHC(Hill Hold Control) control status";
CM_ SG_ 615 BCS_HDCCtrlSt "HDC(Hill Descent Control) control status";
CM_ SG_ 615 BCS_HDCErrSt "HDC error status";
CM_ SG_ 615 BCS_FLWheelSpdEdgesSum "Accumulated sum of rising and falling edges of front left wheel speed sensor output·since IGN ON( the wheel plate have 48 teeth/cycle,the edge is 96)";
CM_ SG_ 615 BCS_FRWheelSpdEdgesSum "Accumulated sum of rising and falling edges of front right wheel speed sensor output·since IGN ON( the wheel plate have 48 teeth/cycle,the edge is 96)";
CM_ SG_ 615 BCS_RLWheelSpdEdgesSum "Accumulated sum of rising and falling edges of rear left wheel speed sensor output·since IGN ON( the wheel plate have 48 teeth/cycle,the edge is 96)";
CM_ SG_ 615 BCS_RRWheelSpdEdgesSum "Accumulated sum of rising and falling edges of  rear right wheel speed sensor output·since IGN ON( the wheel plate have 48 teeth/cycle,the edge is 96)";
CM_ SG_ 615 BCS_FLWheelSpdEdgesSumVD "Quality/fault information to current wheel speed edges sum of front left wheel";
CM_ SG_ 615 BCS_FRWheelSpdEdgesSumVD "Quality/fault information to current wheel speed edges sum of front right wheel";
CM_ SG_ 615 BCS_RLWheelSpdEdgesSumVD "Quality/fault information to current wheel speed edges sum of rear left wheel";
CM_ SG_ 615 BCS_RRWheelSpdEdgesSumVD "Quality/fault information to current wheel speed edges sum of rear right wheel";
CM_ SG_ 615 BCS_FLWheelRotatedDirectionAPA "FL wheel rotate direction for APA";
CM_ SG_ 615 BCS_FRWheelRotatedDirectionAPA "FR wheel rotate direction for APA";
CM_ SG_ 615 BCS_RLWheelRotatedDirectionAPA "RL wheel rotate direction for APA";
CM_ SG_ 615 BCS_RRWheelRotatedDirectionAPA "RR wheel rotate direction for APA";
CM_ SG_ 615 BCS_ParkingReqToEPB "Indicates the release/lock brake request to EPB";
CM_ SG_ 615 BCS_VDCOff "VDC is switched off ";
CM_ SG_ 615 BCS_AVHSt "Indicates AVH(Auto Vehicle Hold)in active or not ";
CM_ SG_ 615 BCS_AVHAvailable "HMI responsible, can get degrate AVH(Auto Vehicle Hold) statement from DSW and send out ";
CM_ SG_ 615 BCS_TCSOff "TCS is switched off ";
CM_ SG_ 615 BCS_BrakeOverHeat "Indicating brake temperature too high or not";
CM_ SG_ 615 BCS_ABAactive "ABA(Adaptive Brake Assistance) is active";
CM_ SG_ 615 BCS_ABAavailable "The ABA(Adaptive Brake Assistance)  function is available";
CM_ SG_ 615 BCS_ABPActive "ABP(Automatic brake Pre-fill) is active";
CM_ SG_ 615 BCS_ABPAvailable "ABP(Automatic brake Pre-fill) is available";
CM_ SG_ 615 BCS_AEBActive "AEB(Automatic EmergencyBraking) is active (in deceleration)";
CM_ SG_ 615 BCS_AEBAvailable "AEB(Automatic EmergencyBraking) is available";
CM_ SG_ 615 BCS_AWBActive "AWB(Automatic Warning Brake) is active";
CM_ SG_ 615 BCS_AWBAvailable "AWB(Automatic Warning Brake) is available";
CM_ SG_ 615 BCS_VehicleStandStillSt "Indicating whether the vehicle is standstill or not;must not be set until standstill is surely reached.";
CM_ SG_ 615 BCS_AEBBAActive "Indicates AEBBA active or not";
CM_ SG_ 615 IPB_InputRodStroke "Indicate inputRod stroke value";
CM_ SG_ 615 IPB_InputRodStrokeSt "Indicate inputRod stroke status";
CM_ SG_ 615 BCS_RAEBActive "RAEB is active ";
CM_ SG_ 615 BCS_RAEBAvailable "RAEB is available ";
CM_ SG_ 615 IPB_PlungerPressureSt "Indicate plunger pressure status";
CM_ SG_ 615 IPB_PlungerPressure "Indicate plunger pressure value";
CM_ SG_ 615 BCS_2ParkDrvBrkOverrideFlg "Indicate driver brakes more than the system. ";
CM_ SG_ 615 BCS_BrkTqCtrlAvlDrivingRdn "It indicates  whether  ESP/IPB is available for cruise function ，in redunant mode,including L3/L4/L5.";
CM_ SG_ 615 BCS_BrkTqCtrlActvRdn "It indicates  whether  ESP/IPB is  responsed for the brake request of ADAS, in redunant mode,including L3/L4/L5.";
CM_ SG_ 615 BCS_L3CommunicationVld "The validity of CAN bus communication .";
CM_ SG_ 615 BCS_LFIActiveSt "The activation status of the LFI function。";
CM_ SG_ 352 BCS_2_CRC "E2E Profile 5 CRC";
CM_ SG_ 352 BCS_2_Counter "E2E Profile 5 Counter";
CM_ SG_ 352 BCS_VehSpd "Vehicle speed";
CM_ SG_ 352 BCS_VehSpdVD "Quality/fault information to vehicle speed";
CM_ SG_ 352 BCS_EBDActiveSt "Indication that EBD system currently performs a brake/engine intervention";
CM_ SG_ 352 BCS_EBDFaultSt "ABS system has detected a heavy fault, which does not even allow a reliable electronic brake distribution and is therefore completely shut down";
CM_ SG_ 352 BCS_ABSActiveSt "Indication that ABS system currently performs a brake intervention";
CM_ SG_ 352 BCS_ABSFaultSt "ABS system has detected a failure which does no allow a reliable ABS regulation and is therefore switched off";
CM_ SG_ 352 BCS_TCSActiveSt "Indication that TCS system currently performs a brake/engine intervention";
CM_ SG_ 352 BCS_TCSFaultSt "TCS is switched off due to detected failure";
CM_ SG_ 352 BCS_VDCActiveSt "Indication that VDC system currently performs a brake/engine intervention when ESP adjust the posture of vehicle ";
CM_ SG_ 352 BCS_VDCFaultSt "VDC is switched off due to detected failure";
CM_ SG_ 352 BCS_PreAndRealVDCActiveSt "Indication that VDC system currently performs a brake/engine intervention when ESP increase pressure ";
CM_ SG_ 352 BCS_RegenModulationAvailable "Indicate whether ESP can follow ePedal request and modify the recuperation torque";
CM_ SG_ 352 BCS_RegenModuleActive "Reduce repcuperation torque requested by oppotize TCS control active status";
CM_ SG_ 352 BCS_RealTCSActiveSt "Indication that TCS system currently real performs a brake/engine intervention ";
CM_ SG_ 352 BCS_TargetRecpTorqRq "Target recuperation torque request by BCS to generator,applies to 4WD and front wheel drive";
CM_ SG_ 352 BCS_TargetRecpTorqRqSt "Status of target recuperation torque request by BCS to generator,applies to 4WD and front wheel drive";
CM_ SG_ 352 BCS_CrbsActive "Indicate whether ESP recuperation torque is controlled by CRBS ";
CM_ SG_ 352 IPB_BrakePedalStsVld "The validity  of brake pedal status";
CM_ SG_ 352 IPB_BrakePedalSt "IBCS Brake Pedal Status";
CM_ SG_ 352 BCS_EngTorqDecFastRANm "This torque  is engine combustion(indicated)decreased target torque (fast) for Rear Axle";
CM_ SG_ 352 BCS_EngTorqIncRANm "This torque  is  increased enginecombustion(indicated)target torque for Rear Axle";
CM_ SG_ 352 BCS_ESP2Park_DrvBrkOverrideFlg "Indicate driver brakes more than the system. ";
CM_ SG_ 352 BCS_TargetRecpTorqRqFA "Target recuperation torque request by BCS to generator,applies to 4WD and front wheel drive";
CM_ SG_ 352 BCS_TargetRecpTorqRqFASt "Status of target recuperation torque request by BCS to generator,applies to 4WD and front wheel drive";
CM_ SG_ 352 BCS_TargetRecpTorqRqRA "Target recuperation torque request by BCS to generator,applies to 4WD and rear wheel drive";
CM_ SG_ 352 BCS_TargetRecpTorqRqRASt "Status of target recuperation torque request by BCS to generator,applies to 4WD and rear wheel drive";
CM_ SG_ 352 BCS_EngTorqDecActiveStRA "Decrease enginetorque  active status (fast and low) for Rear Axle";
CM_ SG_ 352 BCS_PrimBrkCDAAvailableSt "Primary brake actuator L2++ Cruise funtion interface healthy status.CDA NotAvailable: not available forL2++ system due to not initialization or failure or BAT not Finish. .CDA NotAvailable By Situation: not available for L2++ system due to rules not fulfilled.CDA NotAvailable For RBU Failure: CDA not available due to redundant system failure.CDA NotAvailable By Situation: CDA  not available due to rules not fulfilled.CDA Available With Fault: L2++ system Available with failure in short time.CDA Available With Situation: L2++ system active with rules not fulfilled in short time.CDA Available:No failure detected, pre-condition for activing L2++ are fullfilled";
CM_ SG_ 352 BCS_PrimBrkCommuniSt "Primary brake actuator communication healthy status.ADC and Primary brake actuator relevant network communication can be received on at least one channel.Invalid meaning communication is impossible , ADC need to receive the brake actuator signals from RBU.";
CM_ SG_ 352 BCS_PrimBrkActiveSt "Primary brake actuator working status.CDD (Controlled Deceleration for Driver) for L2.CDA (Controlled Deceleration for Automated Driving) for L2++ or Advance Cruise .L2 Active: Brake actuator working in L2 Cruise;L2++ Active：Brake actuator  working in L2++ or Advance Cruise";
CM_ SG_ 352 BCS_2ParkCddApActiveVehHld "Flag indicate that vehicle is activly hold by longitudinal actuator controller";
CM_ SG_ 352 BCS_2ParkAPCStatus "Longitudinal controller status";
CM_ SG_ 352 BCS_2ParkAPAavailability "Flag indicate  APA availability for longitudinal control";
CM_ SG_ 352 BCS_2ParkRPAAVPavailability "Flag indicate  RPA AVP availability for longitudinal control";
CM_ SG_ 352 BCS_2ParkAPCFailureSts "detailed information why this APC maneuver failed";
CM_ SG_ 352 BCS_APCMain2BackupReq "APC_24 main activation request towards backup for RPA/AVP";
CM_ SG_ 352 BCS_PrimBrkCtrlUsedChannel "Primary brake actuator Feekback which communication channel is used for ADC Control";
CM_ SG_ 352 BCS_PrimBrkCDAActiveSt "Primary brake actuator CDA(Controlled Deceleration for Automated Driving) working status.L2++ Active:Brake actuator  working in L2++ or Advance Cruise.";
CM_ SG_ 352 BCS_PrimBrkDecCtrlActiveSt "Primary Brake actuator Deceleration Control Active Status for ADC Ax Request .(CDD or CDA)";
CM_ SG_ 352 BCS_PrimBrkCDDAvailableSt "Primary brake actuator L2 Cruise funtion interface healthy status.";
CM_ SG_ 352 BCS_EngTorqDecActiveStFA "Decrease enginetorque  active status (fast and low) for Front Axle";
CM_ SG_ 352 BCS_EngTorqIncActiveStFA "Increased engine torque  active status for Front Axle";
CM_ SG_ 352 IBCS_ADCNetErrorFb "ADC Net Error Feedback";
CM_ SG_ 352 IBCS_NetModeResp "IPB  Brake Torque Response Status in Main  Net";
CM_ SG_ 352 BCS_EngTorqDecFastFA "This torque  is engine combustion(indicated) decreased target torque (fast)";
CM_ SG_ 352 BCS_EngTorqIncFA "This torque  is  increased engine combustion(indicated)target torque ";

BA_DEF_ BO_  "GenMsgCycleTime" INT 0 0;
BA_DEF_ BO_  "GenMsgCycleTimeFast" INT 0 0;
BA_DEF_ BO_  "GenMsgSendType" ENUM  "Periodic","Event","IfActive","POE","PA","FixedPeriodic","Event","EnabledPeriodic","NotUsed","NotUsed","EventPeriodic","NotUsed","NotUsed","NoMsgSendType";
BA_DEF_ BO_  "VFrameFormat" ENUM  "StandardCAN","ExtendedCAN","reserved","reserved","reserved","reserved","reserved","reserved","reserved","reserved","reserved","reserved","reserved","reserved","StandardCAN_FD","ExtendedCAN_FD";
BA_DEF_ BO_  "CANFD_BRS" ENUM  "0","1";
BA_DEF_ SG_  "EventCommandSignal" ENUM  "No","Yes";
BA_DEF_ SG_  "GatewayedSignals" ENUM  "No","Yes";
BA_DEF_ SG_  "GenSigInactiveValue" HEX 0 0;
BA_DEF_ SG_  "GenSigInvalidValue" HEX 0 0;
BA_DEF_ SG_  "GenSigSendType" ENUM  "Trigger","Passive","Cyclic","OnWrite","OnWriteWithRepetition","OnChange","OnChangeWithRepetition","IfActive","IfActiveWithRepetition","NoSigSendType";
BA_DEF_ SG_  "GenSigStartValue" HEX 0 0;
BA_DEF_ SG_  "GenSigTimeoutValue" HEX 0 0;
BA_DEF_ SG_  "Remark" STRING ;
BA_ "GenMsgCycleTime" BO_ 825 100;
BA_ "GenMsgCycleTimeFast" BO_ 825 0;
BA_ "GenMsgSendType" BO_ 825 0;
BA_ "VFrameFormat" BO_ 825 14;
BA_ "CANFD_BRS" BO_ 825 1;
BA_ "GenMsgCycleTime" BO_ 825 100;
BA_ "GenMsgCycleTimeFast" BO_ 825 0;
BA_ "GenMsgSendType" BO_ 825 0;
BA_ "VFrameFormat" BO_ 825 14;
BA_ "CANFD_BRS" BO_ 825 1;
BA_ "GenMsgCycleTime" BO_ 825 100;
BA_ "GenMsgCycleTimeFast" BO_ 825 0;
BA_ "GenMsgSendType" BO_ 825 0;
BA_ "VFrameFormat" BO_ 825 14;
BA_ "CANFD_BRS" BO_ 825 1;
BA_ "GenMsgCycleTime" BO_ 825 100;
BA_ "GenMsgCycleTimeFast" BO_ 825 0;
BA_ "GenMsgSendType" BO_ 825 0;
BA_ "VFrameFormat" BO_ 825 14;
BA_ "CANFD_BRS" BO_ 825 1;
BA_ "GenMsgCycleTime" BO_ 825 100;
BA_ "GenMsgCycleTimeFast" BO_ 825 0;
BA_ "GenMsgSendType" BO_ 825 0;
BA_ "VFrameFormat" BO_ 825 14;
BA_ "CANFD_BRS" BO_ 825 1;
BA_ "GenMsgCycleTime" BO_ 825 100;
BA_ "GenMsgCycleTimeFast" BO_ 825 0;
BA_ "GenMsgSendType" BO_ 825 0;
BA_ "VFrameFormat" BO_ 825 14;
BA_ "CANFD_BRS" BO_ 825 1;
BA_ "GenMsgCycleTime" BO_ 825 100;
BA_ "GenMsgCycleTimeFast" BO_ 825 0;
BA_ "GenMsgSendType" BO_ 825 0;
BA_ "VFrameFormat" BO_ 825 14;
BA_ "CANFD_BRS" BO_ 825 1;
BA_ "GenMsgCycleTime" BO_ 825 100;
BA_ "GenMsgCycleTimeFast" BO_ 825 0;
BA_ "GenMsgSendType" BO_ 825 0;
BA_ "VFrameFormat" BO_ 825 14;
BA_ "CANFD_BRS" BO_ 825 1;
BA_ "GenMsgCycleTime" BO_ 825 100;
BA_ "GenMsgCycleTimeFast" BO_ 825 0;
BA_ "GenMsgSendType" BO_ 825 0;
BA_ "VFrameFormat" BO_ 825 14;
BA_ "CANFD_BRS" BO_ 825 1;
BA_ "GenMsgCycleTime" BO_ 825 100;
BA_ "GenMsgCycleTimeFast" BO_ 825 0;
BA_ "GenMsgSendType" BO_ 825 0;
BA_ "VFrameFormat" BO_ 825 14;
BA_ "CANFD_BRS" BO_ 825 1;
BA_ "GenMsgCycleTime" BO_ 825 100;
BA_ "GenMsgCycleTimeFast" BO_ 825 0;
BA_ "GenMsgSendType" BO_ 825 0;
BA_ "VFrameFormat" BO_ 825 14;
BA_ "CANFD_BRS" BO_ 825 1;
BA_ "GenMsgCycleTime" BO_ 825 100;
BA_ "GenMsgCycleTimeFast" BO_ 825 0;
BA_ "GenMsgSendType" BO_ 825 0;
BA_ "VFrameFormat" BO_ 825 14;
BA_ "CANFD_BRS" BO_ 825 1;
BA_ "GenMsgCycleTime" BO_ 825 100;
BA_ "GenMsgCycleTimeFast" BO_ 825 0;
BA_ "GenMsgSendType" BO_ 825 0;
BA_ "VFrameFormat" BO_ 825 14;
BA_ "CANFD_BRS" BO_ 825 1;
BA_ "GenMsgCycleTime" BO_ 825 100;
BA_ "GenMsgCycleTimeFast" BO_ 825 0;
BA_ "GenMsgSendType" BO_ 825 0;
BA_ "VFrameFormat" BO_ 825 14;
BA_ "CANFD_BRS" BO_ 825 1;
BA_ "GenMsgCycleTime" BO_ 825 100;
BA_ "GenMsgCycleTimeFast" BO_ 825 0;
BA_ "GenMsgSendType" BO_ 825 0;
BA_ "VFrameFormat" BO_ 825 14;
BA_ "CANFD_BRS" BO_ 825 1;
BA_ "GenMsgCycleTime" BO_ 825 100;
BA_ "GenMsgCycleTimeFast" BO_ 825 0;
BA_ "GenMsgSendType" BO_ 825 0;
BA_ "VFrameFormat" BO_ 825 14;
BA_ "CANFD_BRS" BO_ 825 1;
BA_ "GenMsgCycleTime" BO_ 825 100;
BA_ "GenMsgCycleTimeFast" BO_ 825 0;
BA_ "GenMsgSendType" BO_ 825 0;
BA_ "VFrameFormat" BO_ 825 14;
BA_ "CANFD_BRS" BO_ 825 1;
BA_ "GenMsgCycleTime" BO_ 825 100;
BA_ "GenMsgCycleTimeFast" BO_ 825 0;
BA_ "GenMsgSendType" BO_ 825 0;
BA_ "VFrameFormat" BO_ 825 14;
BA_ "CANFD_BRS" BO_ 825 1;
BA_ "GenMsgCycleTime" BO_ 825 100;
BA_ "GenMsgCycleTimeFast" BO_ 825 0;
BA_ "GenMsgSendType" BO_ 825 0;
BA_ "VFrameFormat" BO_ 825 14;
BA_ "CANFD_BRS" BO_ 825 1;
BA_ "GenMsgCycleTime" BO_ 825 100;
BA_ "GenMsgCycleTimeFast" BO_ 825 0;
BA_ "GenMsgSendType" BO_ 825 0;
BA_ "VFrameFormat" BO_ 825 14;
BA_ "CANFD_BRS" BO_ 825 1;
BA_ "GenMsgCycleTime" BO_ 825 100;
BA_ "GenMsgCycleTimeFast" BO_ 825 0;
BA_ "GenMsgSendType" BO_ 825 0;
BA_ "VFrameFormat" BO_ 825 14;
BA_ "CANFD_BRS" BO_ 825 1;
BA_ "GenMsgCycleTime" BO_ 825 100;
BA_ "GenMsgCycleTimeFast" BO_ 825 0;
BA_ "GenMsgSendType" BO_ 825 0;
BA_ "VFrameFormat" BO_ 825 14;
BA_ "CANFD_BRS" BO_ 825 1;
BA_ "GenMsgCycleTime" BO_ 291 40;
BA_ "GenMsgCycleTimeFast" BO_ 291 0;
BA_ "GenMsgSendType" BO_ 291 0;
BA_ "VFrameFormat" BO_ 291 14;
BA_ "CANFD_BRS" BO_ 291 1;
BA_ "GenMsgCycleTime" BO_ 291 40;
BA_ "GenMsgCycleTimeFast" BO_ 291 0;
BA_ "GenMsgSendType" BO_ 291 0;
BA_ "VFrameFormat" BO_ 291 14;
BA_ "CANFD_BRS" BO_ 291 1;
BA_ "GenMsgCycleTime" BO_ 291 40;
BA_ "GenMsgCycleTimeFast" BO_ 291 0;
BA_ "GenMsgSendType" BO_ 291 0;
BA_ "VFrameFormat" BO_ 291 14;
BA_ "CANFD_BRS" BO_ 291 1;
BA_ "GenMsgCycleTime" BO_ 291 40;
BA_ "GenMsgCycleTimeFast" BO_ 291 0;
BA_ "GenMsgSendType" BO_ 291 0;
BA_ "VFrameFormat" BO_ 291 14;
BA_ "CANFD_BRS" BO_ 291 1;
BA_ "GenMsgCycleTime" BO_ 291 40;
BA_ "GenMsgCycleTimeFast" BO_ 291 0;
BA_ "GenMsgSendType" BO_ 291 0;
BA_ "VFrameFormat" BO_ 291 14;
BA_ "CANFD_BRS" BO_ 291 1;
BA_ "GenMsgCycleTime" BO_ 291 40;
BA_ "GenMsgCycleTimeFast" BO_ 291 0;
BA_ "GenMsgSendType" BO_ 291 0;
BA_ "VFrameFormat" BO_ 291 14;
BA_ "CANFD_BRS" BO_ 291 1;
BA_ "GenMsgCycleTime" BO_ 291 40;
BA_ "GenMsgCycleTimeFast" BO_ 291 0;
BA_ "GenMsgSendType" BO_ 291 0;
BA_ "VFrameFormat" BO_ 291 14;
BA_ "CANFD_BRS" BO_ 291 1;
BA_ "GenMsgCycleTime" BO_ 291 40;
BA_ "GenMsgCycleTimeFast" BO_ 291 0;
BA_ "GenMsgSendType" BO_ 291 0;
BA_ "VFrameFormat" BO_ 291 14;
BA_ "CANFD_BRS" BO_ 291 1;
BA_ "GenMsgCycleTime" BO_ 291 40;
BA_ "GenMsgCycleTimeFast" BO_ 291 0;
BA_ "GenMsgSendType" BO_ 291 0;
BA_ "VFrameFormat" BO_ 291 14;
BA_ "CANFD_BRS" BO_ 291 1;
BA_ "GenMsgCycleTime" BO_ 291 40;
BA_ "GenMsgCycleTimeFast" BO_ 291 0;
BA_ "GenMsgSendType" BO_ 291 0;
BA_ "VFrameFormat" BO_ 291 14;
BA_ "CANFD_BRS" BO_ 291 1;
BA_ "GenMsgCycleTime" BO_ 291 40;
BA_ "GenMsgCycleTimeFast" BO_ 291 0;
BA_ "GenMsgSendType" BO_ 291 0;
BA_ "VFrameFormat" BO_ 291 14;
BA_ "CANFD_BRS" BO_ 291 1;
BA_ "GenMsgCycleTime" BO_ 291 40;
BA_ "GenMsgCycleTimeFast" BO_ 291 0;
BA_ "GenMsgSendType" BO_ 291 0;
BA_ "VFrameFormat" BO_ 291 14;
BA_ "CANFD_BRS" BO_ 291 1;
BA_ "GenMsgCycleTime" BO_ 291 40;
BA_ "GenMsgCycleTimeFast" BO_ 291 0;
BA_ "GenMsgSendType" BO_ 291 0;
BA_ "VFrameFormat" BO_ 291 14;
BA_ "CANFD_BRS" BO_ 291 1;
BA_ "GenMsgCycleTime" BO_ 865 40;
BA_ "GenMsgCycleTimeFast" BO_ 865 0;
BA_ "GenMsgSendType" BO_ 865 0;
BA_ "VFrameFormat" BO_ 865 14;
BA_ "CANFD_BRS" BO_ 865 1;
BA_ "GenMsgCycleTime" BO_ 865 40;
BA_ "GenMsgCycleTimeFast" BO_ 865 0;
BA_ "GenMsgSendType" BO_ 865 0;
BA_ "VFrameFormat" BO_ 865 14;
BA_ "CANFD_BRS" BO_ 865 1;
BA_ "GenMsgCycleTime" BO_ 865 40;
BA_ "GenMsgCycleTimeFast" BO_ 865 0;
BA_ "GenMsgSendType" BO_ 865 0;
BA_ "VFrameFormat" BO_ 865 14;
BA_ "CANFD_BRS" BO_ 865 1;
BA_ "GenMsgCycleTime" BO_ 865 40;
BA_ "GenMsgCycleTimeFast" BO_ 865 0;
BA_ "GenMsgSendType" BO_ 865 0;
BA_ "VFrameFormat" BO_ 865 14;
BA_ "CANFD_BRS" BO_ 865 1;
BA_ "GenMsgCycleTime" BO_ 865 40;
BA_ "GenMsgCycleTimeFast" BO_ 865 0;
BA_ "GenMsgSendType" BO_ 865 0;
BA_ "VFrameFormat" BO_ 865 14;
BA_ "CANFD_BRS" BO_ 865 1;
BA_ "GenMsgCycleTime" BO_ 865 40;
BA_ "GenMsgCycleTimeFast" BO_ 865 0;
BA_ "GenMsgSendType" BO_ 865 0;
BA_ "VFrameFormat" BO_ 865 14;
BA_ "CANFD_BRS" BO_ 865 1;
BA_ "GenMsgCycleTime" BO_ 865 40;
BA_ "GenMsgCycleTimeFast" BO_ 865 0;
BA_ "GenMsgSendType" BO_ 865 0;
BA_ "VFrameFormat" BO_ 865 14;
BA_ "CANFD_BRS" BO_ 865 1;
BA_ "GenMsgCycleTime" BO_ 865 40;
BA_ "GenMsgCycleTimeFast" BO_ 865 0;
BA_ "GenMsgSendType" BO_ 865 0;
BA_ "VFrameFormat" BO_ 865 14;
BA_ "CANFD_BRS" BO_ 865 1;
BA_ "GenMsgCycleTime" BO_ 865 40;
BA_ "GenMsgCycleTimeFast" BO_ 865 0;
BA_ "GenMsgSendType" BO_ 865 0;
BA_ "VFrameFormat" BO_ 865 14;
BA_ "CANFD_BRS" BO_ 865 1;
BA_ "GenMsgCycleTime" BO_ 865 40;
BA_ "GenMsgCycleTimeFast" BO_ 865 0;
BA_ "GenMsgSendType" BO_ 865 0;
BA_ "VFrameFormat" BO_ 865 14;
BA_ "CANFD_BRS" BO_ 865 1;
BA_ "GenMsgCycleTime" BO_ 865 40;
BA_ "GenMsgCycleTimeFast" BO_ 865 0;
BA_ "GenMsgSendType" BO_ 865 0;
BA_ "VFrameFormat" BO_ 865 14;
BA_ "CANFD_BRS" BO_ 865 1;
BA_ "GenMsgCycleTime" BO_ 865 40;
BA_ "GenMsgCycleTimeFast" BO_ 865 0;
BA_ "GenMsgSendType" BO_ 865 0;
BA_ "VFrameFormat" BO_ 865 14;
BA_ "CANFD_BRS" BO_ 865 1;
BA_ "GenMsgCycleTime" BO_ 865 40;
BA_ "GenMsgCycleTimeFast" BO_ 865 0;
BA_ "GenMsgSendType" BO_ 865 0;
BA_ "VFrameFormat" BO_ 865 14;
BA_ "CANFD_BRS" BO_ 865 1;
BA_ "GenMsgCycleTime" BO_ 865 40;
BA_ "GenMsgCycleTimeFast" BO_ 865 0;
BA_ "GenMsgSendType" BO_ 865 0;
BA_ "VFrameFormat" BO_ 865 14;
BA_ "CANFD_BRS" BO_ 865 1;
BA_ "GenMsgCycleTime" BO_ 865 40;
BA_ "GenMsgCycleTimeFast" BO_ 865 0;
BA_ "GenMsgSendType" BO_ 865 0;
BA_ "VFrameFormat" BO_ 865 14;
BA_ "CANFD_BRS" BO_ 865 1;
BA_ "GenMsgCycleTime" BO_ 865 40;
BA_ "GenMsgCycleTimeFast" BO_ 865 0;
BA_ "GenMsgSendType" BO_ 865 0;
BA_ "VFrameFormat" BO_ 865 14;
BA_ "CANFD_BRS" BO_ 865 1;
BA_ "GenMsgCycleTime" BO_ 865 40;
BA_ "GenMsgCycleTimeFast" BO_ 865 0;
BA_ "GenMsgSendType" BO_ 865 0;
BA_ "VFrameFormat" BO_ 865 14;
BA_ "CANFD_BRS" BO_ 865 1;
BA_ "GenMsgCycleTime" BO_ 865 40;
BA_ "GenMsgCycleTimeFast" BO_ 865 0;
BA_ "GenMsgSendType" BO_ 865 0;
BA_ "VFrameFormat" BO_ 865 14;
BA_ "CANFD_BRS" BO_ 865 1;
BA_ "GenMsgCycleTime" BO_ 865 40;
BA_ "GenMsgCycleTimeFast" BO_ 865 0;
BA_ "GenMsgSendType" BO_ 865 0;
BA_ "VFrameFormat" BO_ 865 14;
BA_ "CANFD_BRS" BO_ 865 1;
BA_ "GenMsgCycleTime" BO_ 865 40;
BA_ "GenMsgCycleTimeFast" BO_ 865 0;
BA_ "GenMsgSendType" BO_ 865 0;
BA_ "VFrameFormat" BO_ 865 14;
BA_ "CANFD_BRS" BO_ 865 1;
BA_ "GenMsgCycleTime" BO_ 865 40;
BA_ "GenMsgCycleTimeFast" BO_ 865 0;
BA_ "GenMsgSendType" BO_ 865 0;
BA_ "VFrameFormat" BO_ 865 14;
BA_ "CANFD_BRS" BO_ 865 1;
BA_ "GenMsgCycleTime" BO_ 865 40;
BA_ "GenMsgCycleTimeFast" BO_ 865 0;
BA_ "GenMsgSendType" BO_ 865 0;
BA_ "VFrameFormat" BO_ 865 14;
BA_ "CANFD_BRS" BO_ 865 1;
BA_ "GenMsgCycleTime" BO_ 865 40;
BA_ "GenMsgCycleTimeFast" BO_ 865 0;
BA_ "GenMsgSendType" BO_ 865 0;
BA_ "VFrameFormat" BO_ 865 14;
BA_ "CANFD_BRS" BO_ 865 1;
BA_ "GenMsgCycleTime" BO_ 865 40;
BA_ "GenMsgCycleTimeFast" BO_ 865 0;
BA_ "GenMsgSendType" BO_ 865 0;
BA_ "VFrameFormat" BO_ 865 14;
BA_ "CANFD_BRS" BO_ 865 1;
BA_ "GenMsgCycleTime" BO_ 865 40;
BA_ "GenMsgCycleTimeFast" BO_ 865 0;
BA_ "GenMsgSendType" BO_ 865 0;
BA_ "VFrameFormat" BO_ 865 14;
BA_ "CANFD_BRS" BO_ 865 1;
BA_ "GenMsgCycleTime" BO_ 865 40;
BA_ "GenMsgCycleTimeFast" BO_ 865 0;
BA_ "GenMsgSendType" BO_ 865 0;
BA_ "VFrameFormat" BO_ 865 14;
BA_ "CANFD_BRS" BO_ 865 1;
BA_ "GenMsgCycleTime" BO_ 865 40;
BA_ "GenMsgCycleTimeFast" BO_ 865 0;
BA_ "GenMsgSendType" BO_ 865 0;
BA_ "VFrameFormat" BO_ 865 14;
BA_ "CANFD_BRS" BO_ 865 1;
BA_ "GenMsgCycleTime" BO_ 865 40;
BA_ "GenMsgCycleTimeFast" BO_ 865 0;
BA_ "GenMsgSendType" BO_ 865 0;
BA_ "VFrameFormat" BO_ 865 14;
BA_ "CANFD_BRS" BO_ 865 1;
BA_ "GenMsgCycleTime" BO_ 865 40;
BA_ "GenMsgCycleTimeFast" BO_ 865 0;
BA_ "GenMsgSendType" BO_ 865 0;
BA_ "VFrameFormat" BO_ 865 14;
BA_ "CANFD_BRS" BO_ 865 1;
BA_ "GenMsgCycleTime" BO_ 865 40;
BA_ "GenMsgCycleTimeFast" BO_ 865 0;
BA_ "GenMsgSendType" BO_ 865 0;
BA_ "VFrameFormat" BO_ 865 14;
BA_ "CANFD_BRS" BO_ 865 1;
BA_ "GenMsgCycleTime" BO_ 293 500;
BA_ "GenMsgCycleTimeFast" BO_ 293 40;
BA_ "GenMsgSendType" BO_ 293 3;
BA_ "VFrameFormat" BO_ 293 14;
BA_ "CANFD_BRS" BO_ 293 1;
BA_ "GenMsgCycleTime" BO_ 293 500;
BA_ "GenMsgCycleTimeFast" BO_ 293 40;
BA_ "GenMsgSendType" BO_ 293 3;
BA_ "VFrameFormat" BO_ 293 14;
BA_ "CANFD_BRS" BO_ 293 1;
BA_ "GenMsgCycleTime" BO_ 293 500;
BA_ "GenMsgCycleTimeFast" BO_ 293 40;
BA_ "GenMsgSendType" BO_ 293 3;
BA_ "VFrameFormat" BO_ 293 14;
BA_ "CANFD_BRS" BO_ 293 1;
BA_ "GenMsgCycleTime" BO_ 293 500;
BA_ "GenMsgCycleTimeFast" BO_ 293 40;
BA_ "GenMsgSendType" BO_ 293 3;
BA_ "VFrameFormat" BO_ 293 14;
BA_ "CANFD_BRS" BO_ 293 1;
BA_ "GenMsgCycleTime" BO_ 293 500;
BA_ "GenMsgCycleTimeFast" BO_ 293 40;
BA_ "GenMsgSendType" BO_ 293 3;
BA_ "VFrameFormat" BO_ 293 14;
BA_ "CANFD_BRS" BO_ 293 1;
BA_ "GenMsgCycleTime" BO_ 293 500;
BA_ "GenMsgCycleTimeFast" BO_ 293 40;
BA_ "GenMsgSendType" BO_ 293 3;
BA_ "VFrameFormat" BO_ 293 14;
BA_ "CANFD_BRS" BO_ 293 1;
BA_ "GenMsgCycleTime" BO_ 293 500;
BA_ "GenMsgCycleTimeFast" BO_ 293 40;
BA_ "GenMsgSendType" BO_ 293 3;
BA_ "VFrameFormat" BO_ 293 14;
BA_ "CANFD_BRS" BO_ 293 1;
BA_ "GenMsgCycleTime" BO_ 293 500;
BA_ "GenMsgCycleTimeFast" BO_ 293 40;
BA_ "GenMsgSendType" BO_ 293 3;
BA_ "VFrameFormat" BO_ 293 14;
BA_ "CANFD_BRS" BO_ 293 1;
BA_ "GenMsgCycleTime" BO_ 293 500;
BA_ "GenMsgCycleTimeFast" BO_ 293 40;
BA_ "GenMsgSendType" BO_ 293 3;
BA_ "VFrameFormat" BO_ 293 14;
BA_ "CANFD_BRS" BO_ 293 1;
BA_ "GenMsgCycleTime" BO_ 293 500;
BA_ "GenMsgCycleTimeFast" BO_ 293 40;
BA_ "GenMsgSendType" BO_ 293 3;
BA_ "VFrameFormat" BO_ 293 14;
BA_ "CANFD_BRS" BO_ 293 1;
BA_ "GenMsgCycleTime" BO_ 294 500;
BA_ "GenMsgCycleTimeFast" BO_ 294 40;
BA_ "GenMsgSendType" BO_ 294 3;
BA_ "VFrameFormat" BO_ 294 14;
BA_ "CANFD_BRS" BO_ 294 1;
BA_ "GenMsgCycleTime" BO_ 294 500;
BA_ "GenMsgCycleTimeFast" BO_ 294 40;
BA_ "GenMsgSendType" BO_ 294 3;
BA_ "VFrameFormat" BO_ 294 14;
BA_ "CANFD_BRS" BO_ 294 1;
BA_ "GenMsgCycleTime" BO_ 294 500;
BA_ "GenMsgCycleTimeFast" BO_ 294 40;
BA_ "GenMsgSendType" BO_ 294 3;
BA_ "VFrameFormat" BO_ 294 14;
BA_ "CANFD_BRS" BO_ 294 1;
BA_ "GenMsgCycleTime" BO_ 294 500;
BA_ "GenMsgCycleTimeFast" BO_ 294 40;
BA_ "GenMsgSendType" BO_ 294 3;
BA_ "VFrameFormat" BO_ 294 14;
BA_ "CANFD_BRS" BO_ 294 1;
BA_ "GenMsgCycleTime" BO_ 294 500;
BA_ "GenMsgCycleTimeFast" BO_ 294 40;
BA_ "GenMsgSendType" BO_ 294 3;
BA_ "VFrameFormat" BO_ 294 14;
BA_ "CANFD_BRS" BO_ 294 1;
BA_ "GenMsgCycleTime" BO_ 294 500;
BA_ "GenMsgCycleTimeFast" BO_ 294 40;
BA_ "GenMsgSendType" BO_ 294 3;
BA_ "VFrameFormat" BO_ 294 14;
BA_ "CANFD_BRS" BO_ 294 1;
BA_ "GenMsgCycleTime" BO_ 294 500;
BA_ "GenMsgCycleTimeFast" BO_ 294 40;
BA_ "GenMsgSendType" BO_ 294 3;
BA_ "VFrameFormat" BO_ 294 14;
BA_ "CANFD_BRS" BO_ 294 1;
BA_ "GenMsgCycleTime" BO_ 294 500;
BA_ "GenMsgCycleTimeFast" BO_ 294 40;
BA_ "GenMsgSendType" BO_ 294 3;
BA_ "VFrameFormat" BO_ 294 14;
BA_ "CANFD_BRS" BO_ 294 1;
BA_ "GenMsgCycleTime" BO_ 294 500;
BA_ "GenMsgCycleTimeFast" BO_ 294 40;
BA_ "GenMsgSendType" BO_ 294 3;
BA_ "VFrameFormat" BO_ 294 14;
BA_ "CANFD_BRS" BO_ 294 1;
BA_ "GenMsgCycleTime" BO_ 294 500;
BA_ "GenMsgCycleTimeFast" BO_ 294 40;
BA_ "GenMsgSendType" BO_ 294 3;
BA_ "VFrameFormat" BO_ 294 14;
BA_ "CANFD_BRS" BO_ 294 1;
BA_ "GenMsgCycleTime" BO_ 1359 200;
BA_ "GenMsgCycleTimeFast" BO_ 1359 0;
BA_ "GenMsgSendType" BO_ 1359 0;
BA_ "VFrameFormat" BO_ 1359 0;
BA_ "CANFD_BRS" BO_ 1359 1;
BA_ "GenMsgCycleTime" BO_ 1359 200;
BA_ "GenMsgCycleTimeFast" BO_ 1359 0;
BA_ "GenMsgSendType" BO_ 1359 0;
BA_ "VFrameFormat" BO_ 1359 0;
BA_ "CANFD_BRS" BO_ 1359 1;
BA_ "GenMsgCycleTime" BO_ 1359 200;
BA_ "GenMsgCycleTimeFast" BO_ 1359 0;
BA_ "GenMsgSendType" BO_ 1359 0;
BA_ "VFrameFormat" BO_ 1359 0;
BA_ "CANFD_BRS" BO_ 1359 1;
BA_ "GenMsgCycleTime" BO_ 1359 200;
BA_ "GenMsgCycleTimeFast" BO_ 1359 0;
BA_ "GenMsgSendType" BO_ 1359 0;
BA_ "VFrameFormat" BO_ 1359 0;
BA_ "CANFD_BRS" BO_ 1359 1;
BA_ "GenMsgCycleTime" BO_ 1359 200;
BA_ "GenMsgCycleTimeFast" BO_ 1359 0;
BA_ "GenMsgSendType" BO_ 1359 0;
BA_ "VFrameFormat" BO_ 1359 0;
BA_ "CANFD_BRS" BO_ 1359 1;
BA_ "GenMsgCycleTime" BO_ 1359 200;
BA_ "GenMsgCycleTimeFast" BO_ 1359 0;
BA_ "GenMsgSendType" BO_ 1359 0;
BA_ "VFrameFormat" BO_ 1359 0;
BA_ "CANFD_BRS" BO_ 1359 1;
BA_ "GenMsgCycleTime" BO_ 615 20;
BA_ "GenMsgCycleTimeFast" BO_ 615 0;
BA_ "GenMsgSendType" BO_ 615 0;
BA_ "VFrameFormat" BO_ 615 14;
BA_ "CANFD_BRS" BO_ 615 1;
BA_ "GenMsgCycleTime" BO_ 615 20;
BA_ "GenMsgCycleTimeFast" BO_ 615 0;
BA_ "GenMsgSendType" BO_ 615 0;
BA_ "VFrameFormat" BO_ 615 14;
BA_ "CANFD_BRS" BO_ 615 1;
BA_ "GenMsgCycleTime" BO_ 615 20;
BA_ "GenMsgCycleTimeFast" BO_ 615 0;
BA_ "GenMsgSendType" BO_ 615 0;
BA_ "VFrameFormat" BO_ 615 14;
BA_ "CANFD_BRS" BO_ 615 1;
BA_ "GenMsgCycleTime" BO_ 615 20;
BA_ "GenMsgCycleTimeFast" BO_ 615 0;
BA_ "GenMsgSendType" BO_ 615 0;
BA_ "VFrameFormat" BO_ 615 14;
BA_ "CANFD_BRS" BO_ 615 1;
BA_ "GenMsgCycleTime" BO_ 615 20;
BA_ "GenMsgCycleTimeFast" BO_ 615 0;
BA_ "GenMsgSendType" BO_ 615 0;
BA_ "VFrameFormat" BO_ 615 14;
BA_ "CANFD_BRS" BO_ 615 1;
BA_ "GenMsgCycleTime" BO_ 615 20;
BA_ "GenMsgCycleTimeFast" BO_ 615 0;
BA_ "GenMsgSendType" BO_ 615 0;
BA_ "VFrameFormat" BO_ 615 14;
BA_ "CANFD_BRS" BO_ 615 1;
BA_ "GenMsgCycleTime" BO_ 615 20;
BA_ "GenMsgCycleTimeFast" BO_ 615 0;
BA_ "GenMsgSendType" BO_ 615 0;
BA_ "VFrameFormat" BO_ 615 14;
BA_ "CANFD_BRS" BO_ 615 1;
BA_ "GenMsgCycleTime" BO_ 615 20;
BA_ "GenMsgCycleTimeFast" BO_ 615 0;
BA_ "GenMsgSendType" BO_ 615 0;
BA_ "VFrameFormat" BO_ 615 14;
BA_ "CANFD_BRS" BO_ 615 1;
BA_ "GenMsgCycleTime" BO_ 615 20;
BA_ "GenMsgCycleTimeFast" BO_ 615 0;
BA_ "GenMsgSendType" BO_ 615 0;
BA_ "VFrameFormat" BO_ 615 14;
BA_ "CANFD_BRS" BO_ 615 1;
BA_ "GenMsgCycleTime" BO_ 615 20;
BA_ "GenMsgCycleTimeFast" BO_ 615 0;
BA_ "GenMsgSendType" BO_ 615 0;
BA_ "VFrameFormat" BO_ 615 14;
BA_ "CANFD_BRS" BO_ 615 1;
BA_ "GenMsgCycleTime" BO_ 615 20;
BA_ "GenMsgCycleTimeFast" BO_ 615 0;
BA_ "GenMsgSendType" BO_ 615 0;
BA_ "VFrameFormat" BO_ 615 14;
BA_ "CANFD_BRS" BO_ 615 1;
BA_ "GenMsgCycleTime" BO_ 615 20;
BA_ "GenMsgCycleTimeFast" BO_ 615 0;
BA_ "GenMsgSendType" BO_ 615 0;
BA_ "VFrameFormat" BO_ 615 14;
BA_ "CANFD_BRS" BO_ 615 1;
BA_ "GenMsgCycleTime" BO_ 615 20;
BA_ "GenMsgCycleTimeFast" BO_ 615 0;
BA_ "GenMsgSendType" BO_ 615 0;
BA_ "VFrameFormat" BO_ 615 14;
BA_ "CANFD_BRS" BO_ 615 1;
BA_ "GenMsgCycleTime" BO_ 615 20;
BA_ "GenMsgCycleTimeFast" BO_ 615 0;
BA_ "GenMsgSendType" BO_ 615 0;
BA_ "VFrameFormat" BO_ 615 14;
BA_ "CANFD_BRS" BO_ 615 1;
BA_ "GenMsgCycleTime" BO_ 615 20;
BA_ "GenMsgCycleTimeFast" BO_ 615 0;
BA_ "GenMsgSendType" BO_ 615 0;
BA_ "VFrameFormat" BO_ 615 14;
BA_ "CANFD_BRS" BO_ 615 1;
BA_ "GenMsgCycleTime" BO_ 615 20;
BA_ "GenMsgCycleTimeFast" BO_ 615 0;
BA_ "GenMsgSendType" BO_ 615 0;
BA_ "VFrameFormat" BO_ 615 14;
BA_ "CANFD_BRS" BO_ 615 1;
BA_ "GenMsgCycleTime" BO_ 615 20;
BA_ "GenMsgCycleTimeFast" BO_ 615 0;
BA_ "GenMsgSendType" BO_ 615 0;
BA_ "VFrameFormat" BO_ 615 14;
BA_ "CANFD_BRS" BO_ 615 1;
BA_ "GenMsgCycleTime" BO_ 615 20;
BA_ "GenMsgCycleTimeFast" BO_ 615 0;
BA_ "GenMsgSendType" BO_ 615 0;
BA_ "VFrameFormat" BO_ 615 14;
BA_ "CANFD_BRS" BO_ 615 1;
BA_ "GenMsgCycleTime" BO_ 615 20;
BA_ "GenMsgCycleTimeFast" BO_ 615 0;
BA_ "GenMsgSendType" BO_ 615 0;
BA_ "VFrameFormat" BO_ 615 14;
BA_ "CANFD_BRS" BO_ 615 1;
BA_ "GenMsgCycleTime" BO_ 615 20;
BA_ "GenMsgCycleTimeFast" BO_ 615 0;
BA_ "GenMsgSendType" BO_ 615 0;
BA_ "VFrameFormat" BO_ 615 14;
BA_ "CANFD_BRS" BO_ 615 1;
BA_ "GenMsgCycleTime" BO_ 615 20;
BA_ "GenMsgCycleTimeFast" BO_ 615 0;
BA_ "GenMsgSendType" BO_ 615 0;
BA_ "VFrameFormat" BO_ 615 14;
BA_ "CANFD_BRS" BO_ 615 1;
BA_ "GenMsgCycleTime" BO_ 615 20;
BA_ "GenMsgCycleTimeFast" BO_ 615 0;
BA_ "GenMsgSendType" BO_ 615 0;
BA_ "VFrameFormat" BO_ 615 14;
BA_ "CANFD_BRS" BO_ 615 1;
BA_ "GenMsgCycleTime" BO_ 615 20;
BA_ "GenMsgCycleTimeFast" BO_ 615 0;
BA_ "GenMsgSendType" BO_ 615 0;
BA_ "VFrameFormat" BO_ 615 14;
BA_ "CANFD_BRS" BO_ 615 1;
BA_ "GenMsgCycleTime" BO_ 615 20;
BA_ "GenMsgCycleTimeFast" BO_ 615 0;
BA_ "GenMsgSendType" BO_ 615 0;
BA_ "VFrameFormat" BO_ 615 14;
BA_ "CANFD_BRS" BO_ 615 1;
BA_ "GenMsgCycleTime" BO_ 615 20;
BA_ "GenMsgCycleTimeFast" BO_ 615 0;
BA_ "GenMsgSendType" BO_ 615 0;
BA_ "VFrameFormat" BO_ 615 14;
BA_ "CANFD_BRS" BO_ 615 1;
BA_ "GenMsgCycleTime" BO_ 615 20;
BA_ "GenMsgCycleTimeFast" BO_ 615 0;
BA_ "GenMsgSendType" BO_ 615 0;
BA_ "VFrameFormat" BO_ 615 14;
BA_ "CANFD_BRS" BO_ 615 1;
BA_ "GenMsgCycleTime" BO_ 615 20;
BA_ "GenMsgCycleTimeFast" BO_ 615 0;
BA_ "GenMsgSendType" BO_ 615 0;
BA_ "VFrameFormat" BO_ 615 14;
BA_ "CANFD_BRS" BO_ 615 1;
BA_ "GenMsgCycleTime" BO_ 615 20;
BA_ "GenMsgCycleTimeFast" BO_ 615 0;
BA_ "GenMsgSendType" BO_ 615 0;
BA_ "VFrameFormat" BO_ 615 14;
BA_ "CANFD_BRS" BO_ 615 1;
BA_ "GenMsgCycleTime" BO_ 615 20;
BA_ "GenMsgCycleTimeFast" BO_ 615 0;
BA_ "GenMsgSendType" BO_ 615 0;
BA_ "VFrameFormat" BO_ 615 14;
BA_ "CANFD_BRS" BO_ 615 1;
BA_ "GenMsgCycleTime" BO_ 615 20;
BA_ "GenMsgCycleTimeFast" BO_ 615 0;
BA_ "GenMsgSendType" BO_ 615 0;
BA_ "VFrameFormat" BO_ 615 14;
BA_ "CANFD_BRS" BO_ 615 1;
BA_ "GenMsgCycleTime" BO_ 615 20;
BA_ "GenMsgCycleTimeFast" BO_ 615 0;
BA_ "GenMsgSendType" BO_ 615 0;
BA_ "VFrameFormat" BO_ 615 14;
BA_ "CANFD_BRS" BO_ 615 1;
BA_ "GenMsgCycleTime" BO_ 615 20;
BA_ "GenMsgCycleTimeFast" BO_ 615 0;
BA_ "GenMsgSendType" BO_ 615 0;
BA_ "VFrameFormat" BO_ 615 14;
BA_ "CANFD_BRS" BO_ 615 1;
BA_ "GenMsgCycleTime" BO_ 615 20;
BA_ "GenMsgCycleTimeFast" BO_ 615 0;
BA_ "GenMsgSendType" BO_ 615 0;
BA_ "VFrameFormat" BO_ 615 14;
BA_ "CANFD_BRS" BO_ 615 1;
BA_ "GenMsgCycleTime" BO_ 615 20;
BA_ "GenMsgCycleTimeFast" BO_ 615 0;
BA_ "GenMsgSendType" BO_ 615 0;
BA_ "VFrameFormat" BO_ 615 14;
BA_ "CANFD_BRS" BO_ 615 1;
BA_ "GenMsgCycleTime" BO_ 615 20;
BA_ "GenMsgCycleTimeFast" BO_ 615 0;
BA_ "GenMsgSendType" BO_ 615 0;
BA_ "VFrameFormat" BO_ 615 14;
BA_ "CANFD_BRS" BO_ 615 1;
BA_ "GenMsgCycleTime" BO_ 615 20;
BA_ "GenMsgCycleTimeFast" BO_ 615 0;
BA_ "GenMsgSendType" BO_ 615 0;
BA_ "VFrameFormat" BO_ 615 14;
BA_ "CANFD_BRS" BO_ 615 1;
BA_ "GenMsgCycleTime" BO_ 615 20;
BA_ "GenMsgCycleTimeFast" BO_ 615 0;
BA_ "GenMsgSendType" BO_ 615 0;
BA_ "VFrameFormat" BO_ 615 14;
BA_ "CANFD_BRS" BO_ 615 1;
BA_ "GenMsgCycleTime" BO_ 615 20;
BA_ "GenMsgCycleTimeFast" BO_ 615 0;
BA_ "GenMsgSendType" BO_ 615 0;
BA_ "VFrameFormat" BO_ 615 14;
BA_ "CANFD_BRS" BO_ 615 1;
BA_ "GenMsgCycleTime" BO_ 615 20;
BA_ "GenMsgCycleTimeFast" BO_ 615 0;
BA_ "GenMsgSendType" BO_ 615 0;
BA_ "VFrameFormat" BO_ 615 14;
BA_ "CANFD_BRS" BO_ 615 1;
BA_ "GenMsgCycleTime" BO_ 615 20;
BA_ "GenMsgCycleTimeFast" BO_ 615 0;
BA_ "GenMsgSendType" BO_ 615 0;
BA_ "VFrameFormat" BO_ 615 14;
BA_ "CANFD_BRS" BO_ 615 1;
BA_ "GenMsgCycleTime" BO_ 615 20;
BA_ "GenMsgCycleTimeFast" BO_ 615 0;
BA_ "GenMsgSendType" BO_ 615 0;
BA_ "VFrameFormat" BO_ 615 14;
BA_ "CANFD_BRS" BO_ 615 1;
BA_ "GenMsgCycleTime" BO_ 615 20;
BA_ "GenMsgCycleTimeFast" BO_ 615 0;
BA_ "GenMsgSendType" BO_ 615 0;
BA_ "VFrameFormat" BO_ 615 14;
BA_ "CANFD_BRS" BO_ 615 1;
BA_ "GenMsgCycleTime" BO_ 615 20;
BA_ "GenMsgCycleTimeFast" BO_ 615 0;
BA_ "GenMsgSendType" BO_ 615 0;
BA_ "VFrameFormat" BO_ 615 14;
BA_ "CANFD_BRS" BO_ 615 1;
BA_ "GenMsgCycleTime" BO_ 615 20;
BA_ "GenMsgCycleTimeFast" BO_ 615 0;
BA_ "GenMsgSendType" BO_ 615 0;
BA_ "VFrameFormat" BO_ 615 14;
BA_ "CANFD_BRS" BO_ 615 1;
BA_ "GenMsgCycleTime" BO_ 615 20;
BA_ "GenMsgCycleTimeFast" BO_ 615 0;
BA_ "GenMsgSendType" BO_ 615 0;
BA_ "VFrameFormat" BO_ 615 14;
BA_ "CANFD_BRS" BO_ 615 1;
BA_ "GenMsgCycleTime" BO_ 615 20;
BA_ "GenMsgCycleTimeFast" BO_ 615 0;
BA_ "GenMsgSendType" BO_ 615 0;
BA_ "VFrameFormat" BO_ 615 14;
BA_ "CANFD_BRS" BO_ 615 1;
BA_ "GenMsgCycleTime" BO_ 615 20;
BA_ "GenMsgCycleTimeFast" BO_ 615 0;
BA_ "GenMsgSendType" BO_ 615 0;
BA_ "VFrameFormat" BO_ 615 14;
BA_ "CANFD_BRS" BO_ 615 1;
BA_ "GenMsgCycleTime" BO_ 615 20;
BA_ "GenMsgCycleTimeFast" BO_ 615 0;
BA_ "GenMsgSendType" BO_ 615 0;
BA_ "VFrameFormat" BO_ 615 14;
BA_ "CANFD_BRS" BO_ 615 1;
BA_ "GenMsgCycleTime" BO_ 615 20;
BA_ "GenMsgCycleTimeFast" BO_ 615 0;
BA_ "GenMsgSendType" BO_ 615 0;
BA_ "VFrameFormat" BO_ 615 14;
BA_ "CANFD_BRS" BO_ 615 1;
BA_ "GenMsgCycleTime" BO_ 615 20;
BA_ "GenMsgCycleTimeFast" BO_ 615 0;
BA_ "GenMsgSendType" BO_ 615 0;
BA_ "VFrameFormat" BO_ 615 14;
BA_ "CANFD_BRS" BO_ 615 1;
BA_ "GenMsgCycleTime" BO_ 615 20;
BA_ "GenMsgCycleTimeFast" BO_ 615 0;
BA_ "GenMsgSendType" BO_ 615 0;
BA_ "VFrameFormat" BO_ 615 14;
BA_ "CANFD_BRS" BO_ 615 1;
BA_ "GenMsgCycleTime" BO_ 615 20;
BA_ "GenMsgCycleTimeFast" BO_ 615 0;
BA_ "GenMsgSendType" BO_ 615 0;
BA_ "VFrameFormat" BO_ 615 14;
BA_ "CANFD_BRS" BO_ 615 1;
BA_ "GenMsgCycleTime" BO_ 615 20;
BA_ "GenMsgCycleTimeFast" BO_ 615 0;
BA_ "GenMsgSendType" BO_ 615 0;
BA_ "VFrameFormat" BO_ 615 14;
BA_ "CANFD_BRS" BO_ 615 1;
BA_ "GenMsgCycleTime" BO_ 615 20;
BA_ "GenMsgCycleTimeFast" BO_ 615 0;
BA_ "GenMsgSendType" BO_ 615 0;
BA_ "VFrameFormat" BO_ 615 14;
BA_ "CANFD_BRS" BO_ 615 1;
BA_ "GenMsgCycleTime" BO_ 615 20;
BA_ "GenMsgCycleTimeFast" BO_ 615 0;
BA_ "GenMsgSendType" BO_ 615 0;
BA_ "VFrameFormat" BO_ 615 14;
BA_ "CANFD_BRS" BO_ 615 1;
BA_ "GenMsgCycleTime" BO_ 615 20;
BA_ "GenMsgCycleTimeFast" BO_ 615 0;
BA_ "GenMsgSendType" BO_ 615 0;
BA_ "VFrameFormat" BO_ 615 14;
BA_ "CANFD_BRS" BO_ 615 1;
BA_ "GenMsgCycleTime" BO_ 615 20;
BA_ "GenMsgCycleTimeFast" BO_ 615 0;
BA_ "GenMsgSendType" BO_ 615 0;
BA_ "VFrameFormat" BO_ 615 14;
BA_ "CANFD_BRS" BO_ 615 1;
BA_ "GenMsgCycleTime" BO_ 615 20;
BA_ "GenMsgCycleTimeFast" BO_ 615 0;
BA_ "GenMsgSendType" BO_ 615 0;
BA_ "VFrameFormat" BO_ 615 14;
BA_ "CANFD_BRS" BO_ 615 1;
BA_ "GenMsgCycleTime" BO_ 615 20;
BA_ "GenMsgCycleTimeFast" BO_ 615 0;
BA_ "GenMsgSendType" BO_ 615 0;
BA_ "VFrameFormat" BO_ 615 14;
BA_ "CANFD_BRS" BO_ 615 1;
BA_ "GenMsgCycleTime" BO_ 615 20;
BA_ "GenMsgCycleTimeFast" BO_ 615 0;
BA_ "GenMsgSendType" BO_ 615 0;
BA_ "VFrameFormat" BO_ 615 14;
BA_ "CANFD_BRS" BO_ 615 1;
BA_ "GenMsgCycleTime" BO_ 352 10;
BA_ "GenMsgCycleTimeFast" BO_ 352 0;
BA_ "GenMsgSendType" BO_ 352 0;
BA_ "VFrameFormat" BO_ 352 14;
BA_ "CANFD_BRS" BO_ 352 1;
BA_ "GenMsgCycleTime" BO_ 352 10;
BA_ "GenMsgCycleTimeFast" BO_ 352 0;
BA_ "GenMsgSendType" BO_ 352 0;
BA_ "VFrameFormat" BO_ 352 14;
BA_ "CANFD_BRS" BO_ 352 1;
BA_ "GenMsgCycleTime" BO_ 352 10;
BA_ "GenMsgCycleTimeFast" BO_ 352 0;
BA_ "GenMsgSendType" BO_ 352 0;
BA_ "VFrameFormat" BO_ 352 14;
BA_ "CANFD_BRS" BO_ 352 1;
BA_ "GenMsgCycleTime" BO_ 352 10;
BA_ "GenMsgCycleTimeFast" BO_ 352 0;
BA_ "GenMsgSendType" BO_ 352 0;
BA_ "VFrameFormat" BO_ 352 14;
BA_ "CANFD_BRS" BO_ 352 1;
BA_ "GenMsgCycleTime" BO_ 352 10;
BA_ "GenMsgCycleTimeFast" BO_ 352 0;
BA_ "GenMsgSendType" BO_ 352 0;
BA_ "VFrameFormat" BO_ 352 14;
BA_ "CANFD_BRS" BO_ 352 1;
BA_ "GenMsgCycleTime" BO_ 352 10;
BA_ "GenMsgCycleTimeFast" BO_ 352 0;
BA_ "GenMsgSendType" BO_ 352 0;
BA_ "VFrameFormat" BO_ 352 14;
BA_ "CANFD_BRS" BO_ 352 1;
BA_ "GenMsgCycleTime" BO_ 352 10;
BA_ "GenMsgCycleTimeFast" BO_ 352 0;
BA_ "GenMsgSendType" BO_ 352 0;
BA_ "VFrameFormat" BO_ 352 14;
BA_ "CANFD_BRS" BO_ 352 1;
BA_ "GenMsgCycleTime" BO_ 352 10;
BA_ "GenMsgCycleTimeFast" BO_ 352 0;
BA_ "GenMsgSendType" BO_ 352 0;
BA_ "VFrameFormat" BO_ 352 14;
BA_ "CANFD_BRS" BO_ 352 1;
BA_ "GenMsgCycleTime" BO_ 352 10;
BA_ "GenMsgCycleTimeFast" BO_ 352 0;
BA_ "GenMsgSendType" BO_ 352 0;
BA_ "VFrameFormat" BO_ 352 14;
BA_ "CANFD_BRS" BO_ 352 1;
BA_ "GenMsgCycleTime" BO_ 352 10;
BA_ "GenMsgCycleTimeFast" BO_ 352 0;
BA_ "GenMsgSendType" BO_ 352 0;
BA_ "VFrameFormat" BO_ 352 14;
BA_ "CANFD_BRS" BO_ 352 1;
BA_ "GenMsgCycleTime" BO_ 352 10;
BA_ "GenMsgCycleTimeFast" BO_ 352 0;
BA_ "GenMsgSendType" BO_ 352 0;
BA_ "VFrameFormat" BO_ 352 14;
BA_ "CANFD_BRS" BO_ 352 1;
BA_ "GenMsgCycleTime" BO_ 352 10;
BA_ "GenMsgCycleTimeFast" BO_ 352 0;
BA_ "GenMsgSendType" BO_ 352 0;
BA_ "VFrameFormat" BO_ 352 14;
BA_ "CANFD_BRS" BO_ 352 1;
BA_ "GenMsgCycleTime" BO_ 352 10;
BA_ "GenMsgCycleTimeFast" BO_ 352 0;
BA_ "GenMsgSendType" BO_ 352 0;
BA_ "VFrameFormat" BO_ 352 14;
BA_ "CANFD_BRS" BO_ 352 1;
BA_ "GenMsgCycleTime" BO_ 352 10;
BA_ "GenMsgCycleTimeFast" BO_ 352 0;
BA_ "GenMsgSendType" BO_ 352 0;
BA_ "VFrameFormat" BO_ 352 14;
BA_ "CANFD_BRS" BO_ 352 1;
BA_ "GenMsgCycleTime" BO_ 352 10;
BA_ "GenMsgCycleTimeFast" BO_ 352 0;
BA_ "GenMsgSendType" BO_ 352 0;
BA_ "VFrameFormat" BO_ 352 14;
BA_ "CANFD_BRS" BO_ 352 1;
BA_ "GenMsgCycleTime" BO_ 352 10;
BA_ "GenMsgCycleTimeFast" BO_ 352 0;
BA_ "GenMsgSendType" BO_ 352 0;
BA_ "VFrameFormat" BO_ 352 14;
BA_ "CANFD_BRS" BO_ 352 1;
BA_ "GenMsgCycleTime" BO_ 352 10;
BA_ "GenMsgCycleTimeFast" BO_ 352 0;
BA_ "GenMsgSendType" BO_ 352 0;
BA_ "VFrameFormat" BO_ 352 14;
BA_ "CANFD_BRS" BO_ 352 1;
BA_ "GenMsgCycleTime" BO_ 352 10;
BA_ "GenMsgCycleTimeFast" BO_ 352 0;
BA_ "GenMsgSendType" BO_ 352 0;
BA_ "VFrameFormat" BO_ 352 14;
BA_ "CANFD_BRS" BO_ 352 1;
BA_ "GenMsgCycleTime" BO_ 352 10;
BA_ "GenMsgCycleTimeFast" BO_ 352 0;
BA_ "GenMsgSendType" BO_ 352 0;
BA_ "VFrameFormat" BO_ 352 14;
BA_ "CANFD_BRS" BO_ 352 1;
BA_ "GenMsgCycleTime" BO_ 352 10;
BA_ "GenMsgCycleTimeFast" BO_ 352 0;
BA_ "GenMsgSendType" BO_ 352 0;
BA_ "VFrameFormat" BO_ 352 14;
BA_ "CANFD_BRS" BO_ 352 1;
BA_ "GenMsgCycleTime" BO_ 352 10;
BA_ "GenMsgCycleTimeFast" BO_ 352 0;
BA_ "GenMsgSendType" BO_ 352 0;
BA_ "VFrameFormat" BO_ 352 14;
BA_ "CANFD_BRS" BO_ 352 1;
BA_ "GenMsgCycleTime" BO_ 352 10;
BA_ "GenMsgCycleTimeFast" BO_ 352 0;
BA_ "GenMsgSendType" BO_ 352 0;
BA_ "VFrameFormat" BO_ 352 14;
BA_ "CANFD_BRS" BO_ 352 1;
BA_ "GenMsgCycleTime" BO_ 352 10;
BA_ "GenMsgCycleTimeFast" BO_ 352 0;
BA_ "GenMsgSendType" BO_ 352 0;
BA_ "VFrameFormat" BO_ 352 14;
BA_ "CANFD_BRS" BO_ 352 1;
BA_ "GenMsgCycleTime" BO_ 352 10;
BA_ "GenMsgCycleTimeFast" BO_ 352 0;
BA_ "GenMsgSendType" BO_ 352 0;
BA_ "VFrameFormat" BO_ 352 14;
BA_ "CANFD_BRS" BO_ 352 1;
BA_ "GenMsgCycleTime" BO_ 352 10;
BA_ "GenMsgCycleTimeFast" BO_ 352 0;
BA_ "GenMsgSendType" BO_ 352 0;
BA_ "VFrameFormat" BO_ 352 14;
BA_ "CANFD_BRS" BO_ 352 1;
BA_ "GenMsgCycleTime" BO_ 352 10;
BA_ "GenMsgCycleTimeFast" BO_ 352 0;
BA_ "GenMsgSendType" BO_ 352 0;
BA_ "VFrameFormat" BO_ 352 14;
BA_ "CANFD_BRS" BO_ 352 1;
BA_ "GenMsgCycleTime" BO_ 352 10;
BA_ "GenMsgCycleTimeFast" BO_ 352 0;
BA_ "GenMsgSendType" BO_ 352 0;
BA_ "VFrameFormat" BO_ 352 14;
BA_ "CANFD_BRS" BO_ 352 1;
BA_ "GenMsgCycleTime" BO_ 352 10;
BA_ "GenMsgCycleTimeFast" BO_ 352 0;
BA_ "GenMsgSendType" BO_ 352 0;
BA_ "VFrameFormat" BO_ 352 14;
BA_ "CANFD_BRS" BO_ 352 1;
BA_ "GenMsgCycleTime" BO_ 352 10;
BA_ "GenMsgCycleTimeFast" BO_ 352 0;
BA_ "GenMsgSendType" BO_ 352 0;
BA_ "VFrameFormat" BO_ 352 14;
BA_ "CANFD_BRS" BO_ 352 1;
BA_ "GenMsgCycleTime" BO_ 352 10;
BA_ "GenMsgCycleTimeFast" BO_ 352 0;
BA_ "GenMsgSendType" BO_ 352 0;
BA_ "VFrameFormat" BO_ 352 14;
BA_ "CANFD_BRS" BO_ 352 1;
BA_ "GenMsgCycleTime" BO_ 352 10;
BA_ "GenMsgCycleTimeFast" BO_ 352 0;
BA_ "GenMsgSendType" BO_ 352 0;
BA_ "VFrameFormat" BO_ 352 14;
BA_ "CANFD_BRS" BO_ 352 1;
BA_ "GenMsgCycleTime" BO_ 352 10;
BA_ "GenMsgCycleTimeFast" BO_ 352 0;
BA_ "GenMsgSendType" BO_ 352 0;
BA_ "VFrameFormat" BO_ 352 14;
BA_ "CANFD_BRS" BO_ 352 1;
BA_ "GenMsgCycleTime" BO_ 352 10;
BA_ "GenMsgCycleTimeFast" BO_ 352 0;
BA_ "GenMsgSendType" BO_ 352 0;
BA_ "VFrameFormat" BO_ 352 14;
BA_ "CANFD_BRS" BO_ 352 1;
BA_ "GenMsgCycleTime" BO_ 352 10;
BA_ "GenMsgCycleTimeFast" BO_ 352 0;
BA_ "GenMsgSendType" BO_ 352 0;
BA_ "VFrameFormat" BO_ 352 14;
BA_ "CANFD_BRS" BO_ 352 1;
BA_ "GenMsgCycleTime" BO_ 352 10;
BA_ "GenMsgCycleTimeFast" BO_ 352 0;
BA_ "GenMsgSendType" BO_ 352 0;
BA_ "VFrameFormat" BO_ 352 14;
BA_ "CANFD_BRS" BO_ 352 1;
BA_ "GenMsgCycleTime" BO_ 352 10;
BA_ "GenMsgCycleTimeFast" BO_ 352 0;
BA_ "GenMsgSendType" BO_ 352 0;
BA_ "VFrameFormat" BO_ 352 14;
BA_ "CANFD_BRS" BO_ 352 1;
BA_ "GenMsgCycleTime" BO_ 352 10;
BA_ "GenMsgCycleTimeFast" BO_ 352 0;
BA_ "GenMsgSendType" BO_ 352 0;
BA_ "VFrameFormat" BO_ 352 14;
BA_ "CANFD_BRS" BO_ 352 1;
BA_ "GenMsgCycleTime" BO_ 352 10;
BA_ "GenMsgCycleTimeFast" BO_ 352 0;
BA_ "GenMsgSendType" BO_ 352 0;
BA_ "VFrameFormat" BO_ 352 14;
BA_ "CANFD_BRS" BO_ 352 1;
BA_ "GenMsgCycleTime" BO_ 352 10;
BA_ "GenMsgCycleTimeFast" BO_ 352 0;
BA_ "GenMsgSendType" BO_ 352 0;
BA_ "VFrameFormat" BO_ 352 14;
BA_ "CANFD_BRS" BO_ 352 1;
BA_ "GenMsgCycleTime" BO_ 352 10;
BA_ "GenMsgCycleTimeFast" BO_ 352 0;
BA_ "GenMsgSendType" BO_ 352 0;
BA_ "VFrameFormat" BO_ 352 14;
BA_ "CANFD_BRS" BO_ 352 1;
BA_ "GenMsgCycleTime" BO_ 352 10;
BA_ "GenMsgCycleTimeFast" BO_ 352 0;
BA_ "GenMsgSendType" BO_ 352 0;
BA_ "VFrameFormat" BO_ 352 14;
BA_ "CANFD_BRS" BO_ 352 1;
BA_ "GenMsgCycleTime" BO_ 352 10;
BA_ "GenMsgCycleTimeFast" BO_ 352 0;
BA_ "GenMsgSendType" BO_ 352 0;
BA_ "VFrameFormat" BO_ 352 14;
BA_ "CANFD_BRS" BO_ 352 1;
BA_ "GenMsgCycleTime" BO_ 352 10;
BA_ "GenMsgCycleTimeFast" BO_ 352 0;
BA_ "GenMsgSendType" BO_ 352 0;
BA_ "VFrameFormat" BO_ 352 14;
BA_ "CANFD_BRS" BO_ 352 1;
BA_ "GenMsgCycleTime" BO_ 352 10;
BA_ "GenMsgCycleTimeFast" BO_ 352 0;
BA_ "GenMsgSendType" BO_ 352 0;
BA_ "VFrameFormat" BO_ 352 14;
BA_ "CANFD_BRS" BO_ 352 1;
BA_ "GenMsgCycleTime" BO_ 352 10;
BA_ "GenMsgCycleTimeFast" BO_ 352 0;
BA_ "GenMsgSendType" BO_ 352 0;
BA_ "VFrameFormat" BO_ 352 14;
BA_ "CANFD_BRS" BO_ 352 1;
BA_ "GenMsgCycleTime" BO_ 352 10;
BA_ "GenMsgCycleTimeFast" BO_ 352 0;
BA_ "GenMsgSendType" BO_ 352 0;
BA_ "VFrameFormat" BO_ 352 14;
BA_ "CANFD_BRS" BO_ 352 1;
BA_ "GenMsgCycleTime" BO_ 352 10;
BA_ "GenMsgCycleTimeFast" BO_ 352 0;
BA_ "GenMsgSendType" BO_ 352 0;
BA_ "VFrameFormat" BO_ 352 14;
BA_ "CANFD_BRS" BO_ 352 1;
BA_ "GenMsgCycleTime" BO_ 352 10;
BA_ "GenMsgCycleTimeFast" BO_ 352 0;
BA_ "GenMsgSendType" BO_ 352 0;
BA_ "VFrameFormat" BO_ 352 14;
BA_ "CANFD_BRS" BO_ 352 1;
BA_ "EventCommandSignal" SG_ 825 WW_FwpFaultSt 0;
BA_ "GatewayedSignals" SG_ 825 WW_FwpFaultSt 0;
BA_ "GenSigInactiveValue" SG_ 825 WW_FwpFaultSt 0;
BA_ "GenSigInvalidValue" SG_ 825 WW_FwpFaultSt 0;
BA_ "GenSigSendType" SG_ 825 WW_FwpFaultSt 1;
BA_ "GenSigStartValue" SG_ 825 WW_FwpFaultSt 0;
BA_ "GenSigTimeoutValue" SG_ 825 WW_FwpFaultSt 0;
BA_ "Remark" SG_ 825 WW_FwpFaultSt "";
BA_ "EventCommandSignal" SG_ 825 WW_RwpFaultSt 0;
BA_ "GatewayedSignals" SG_ 825 WW_RwpFaultSt 0;
BA_ "GenSigInactiveValue" SG_ 825 WW_RwpFaultSt 0;
BA_ "GenSigInvalidValue" SG_ 825 WW_RwpFaultSt 0;
BA_ "GenSigSendType" SG_ 825 WW_RwpFaultSt 1;
BA_ "GenSigStartValue" SG_ 825 WW_RwpFaultSt 0;
BA_ "GenSigTimeoutValue" SG_ 825 WW_RwpFaultSt 0;
BA_ "Remark" SG_ 825 WW_RwpFaultSt "";
BA_ "EventCommandSignal" SG_ 825 WW_FwshFaultSt 0;
BA_ "GatewayedSignals" SG_ 825 WW_FwshFaultSt 0;
BA_ "GenSigInactiveValue" SG_ 825 WW_FwshFaultSt 0;
BA_ "GenSigInvalidValue" SG_ 825 WW_FwshFaultSt 0;
BA_ "GenSigSendType" SG_ 825 WW_FwshFaultSt 1;
BA_ "GenSigStartValue" SG_ 825 WW_FwshFaultSt 0;
BA_ "GenSigTimeoutValue" SG_ 825 WW_FwshFaultSt 0;
BA_ "Remark" SG_ 825 WW_FwshFaultSt "";
BA_ "EventCommandSignal" SG_ 825 WW_RwshFaultSt 0;
BA_ "GatewayedSignals" SG_ 825 WW_RwshFaultSt 0;
BA_ "GenSigInactiveValue" SG_ 825 WW_RwshFaultSt 0;
BA_ "GenSigInvalidValue" SG_ 825 WW_RwshFaultSt 0;
BA_ "GenSigSendType" SG_ 825 WW_RwshFaultSt 1;
BA_ "GenSigStartValue" SG_ 825 WW_RwshFaultSt 0;
BA_ "GenSigTimeoutValue" SG_ 825 WW_RwshFaultSt 0;
BA_ "Remark" SG_ 825 WW_RwshFaultSt "";
BA_ "EventCommandSignal" SG_ 825 WW_FwpAutoModeSt 0;
BA_ "GatewayedSignals" SG_ 825 WW_FwpAutoModeSt 0;
BA_ "GenSigInactiveValue" SG_ 825 WW_FwpAutoModeSt 0;
BA_ "GenSigInvalidValue" SG_ 825 WW_FwpAutoModeSt 0;
BA_ "GenSigSendType" SG_ 825 WW_FwpAutoModeSt 1;
BA_ "GenSigStartValue" SG_ 825 WW_FwpAutoModeSt 0;
BA_ "GenSigTimeoutValue" SG_ 825 WW_FwpAutoModeSt 0;
BA_ "Remark" SG_ 825 WW_FwpAutoModeSt "";
BA_ "EventCommandSignal" SG_ 825 WW_RainFallLevel 0;
BA_ "GatewayedSignals" SG_ 825 WW_RainFallLevel 0;
BA_ "GenSigInactiveValue" SG_ 825 WW_RainFallLevel 0;
BA_ "GenSigInvalidValue" SG_ 825 WW_RainFallLevel 0;
BA_ "GenSigSendType" SG_ 825 WW_RainFallLevel 1;
BA_ "GenSigStartValue" SG_ 825 WW_RainFallLevel 0;
BA_ "GenSigTimeoutValue" SG_ 825 WW_RainFallLevel 0;
BA_ "Remark" SG_ 825 WW_RainFallLevel "";
BA_ "EventCommandSignal" SG_ 825 RLS_LightOnReq 0;
BA_ "GatewayedSignals" SG_ 825 RLS_LightOnReq 0;
BA_ "GenSigInactiveValue" SG_ 825 RLS_LightOnReq 0;
BA_ "GenSigInvalidValue" SG_ 825 RLS_LightOnReq 0;
BA_ "GenSigSendType" SG_ 825 RLS_LightOnReq 1;
BA_ "GenSigStartValue" SG_ 825 RLS_LightOnReq 0;
BA_ "GenSigTimeoutValue" SG_ 825 RLS_LightOnReq 0;
BA_ "Remark" SG_ 825 RLS_LightOnReq "";
BA_ "EventCommandSignal" SG_ 825 RLS_LampOnReqValid 0;
BA_ "GatewayedSignals" SG_ 825 RLS_LampOnReqValid 0;
BA_ "GenSigInactiveValue" SG_ 825 RLS_LampOnReqValid 0;
BA_ "GenSigInvalidValue" SG_ 825 RLS_LampOnReqValid 0;
BA_ "GenSigSendType" SG_ 825 RLS_LampOnReqValid 1;
BA_ "GenSigStartValue" SG_ 825 RLS_LampOnReqValid 0;
BA_ "GenSigTimeoutValue" SG_ 825 RLS_LampOnReqValid 0;
BA_ "Remark" SG_ 825 RLS_LampOnReqValid "";
BA_ "EventCommandSignal" SG_ 825 RLS_WiperSpd 0;
BA_ "GatewayedSignals" SG_ 825 RLS_WiperSpd 0;
BA_ "GenSigInactiveValue" SG_ 825 RLS_WiperSpd 0;
BA_ "GenSigInvalidValue" SG_ 825 RLS_WiperSpd 0;
BA_ "GenSigSendType" SG_ 825 RLS_WiperSpd 1;
BA_ "GenSigStartValue" SG_ 825 RLS_WiperSpd 0;
BA_ "GenSigTimeoutValue" SG_ 825 RLS_WiperSpd 0;
BA_ "Remark" SG_ 825 RLS_WiperSpd "";
BA_ "EventCommandSignal" SG_ 825 RLS_AMBBrightness 0;
BA_ "GatewayedSignals" SG_ 825 RLS_AMBBrightness 0;
BA_ "GenSigInactiveValue" SG_ 825 RLS_AMBBrightness 0;
BA_ "GenSigInvalidValue" SG_ 825 RLS_AMBBrightness 0;
BA_ "GenSigSendType" SG_ 825 RLS_AMBBrightness 1;
BA_ "GenSigStartValue" SG_ 825 RLS_AMBBrightness 16382;
BA_ "GenSigTimeoutValue" SG_ 825 RLS_AMBBrightness 0;
BA_ "Remark" SG_ 825 RLS_AMBBrightness "";
BA_ "EventCommandSignal" SG_ 825 RLS_FWBrightness 0;
BA_ "GatewayedSignals" SG_ 825 RLS_FWBrightness 0;
BA_ "GenSigInactiveValue" SG_ 825 RLS_FWBrightness 0;
BA_ "GenSigInvalidValue" SG_ 825 RLS_FWBrightness 0;
BA_ "GenSigSendType" SG_ 825 RLS_FWBrightness 1;
BA_ "GenSigStartValue" SG_ 825 RLS_FWBrightness 16382;
BA_ "GenSigTimeoutValue" SG_ 825 RLS_FWBrightness 0;
BA_ "Remark" SG_ 825 RLS_FWBrightness "";
BA_ "EventCommandSignal" SG_ 825 RLS_RainfallLevel 0;
BA_ "GatewayedSignals" SG_ 825 RLS_RainfallLevel 0;
BA_ "GenSigInactiveValue" SG_ 825 RLS_RainfallLevel 0;
BA_ "GenSigInvalidValue" SG_ 825 RLS_RainfallLevel 0;
BA_ "GenSigSendType" SG_ 825 RLS_RainfallLevel 1;
BA_ "GenSigStartValue" SG_ 825 RLS_RainfallLevel 14;
BA_ "GenSigTimeoutValue" SG_ 825 RLS_RainfallLevel 0;
BA_ "Remark" SG_ 825 RLS_RainfallLevel "";
BA_ "EventCommandSignal" SG_ 825 RLS_RSErr 0;
BA_ "GatewayedSignals" SG_ 825 RLS_RSErr 0;
BA_ "GenSigInactiveValue" SG_ 825 RLS_RSErr 0;
BA_ "GenSigInvalidValue" SG_ 825 RLS_RSErr 0;
BA_ "GenSigSendType" SG_ 825 RLS_RSErr 1;
BA_ "GenSigStartValue" SG_ 825 RLS_RSErr 0;
BA_ "GenSigTimeoutValue" SG_ 825 RLS_RSErr 0;
BA_ "Remark" SG_ 825 RLS_RSErr "";
BA_ "EventCommandSignal" SG_ 825 RLS_LSErr 0;
BA_ "GatewayedSignals" SG_ 825 RLS_LSErr 0;
BA_ "GenSigInactiveValue" SG_ 825 RLS_LSErr 0;
BA_ "GenSigInvalidValue" SG_ 825 RLS_LSErr 0;
BA_ "GenSigSendType" SG_ 825 RLS_LSErr 1;
BA_ "GenSigStartValue" SG_ 825 RLS_LSErr 0;
BA_ "GenSigTimeoutValue" SG_ 825 RLS_LSErr 0;
BA_ "Remark" SG_ 825 RLS_LSErr "";
BA_ "EventCommandSignal" SG_ 825 PM_AUTHPstState 0;
BA_ "GatewayedSignals" SG_ 825 PM_AUTHPstState 0;
BA_ "GenSigInactiveValue" SG_ 825 PM_AUTHPstState 0;
BA_ "GenSigInvalidValue" SG_ 825 PM_AUTHPstState 0;
BA_ "GenSigSendType" SG_ 825 PM_AUTHPstState 1;
BA_ "GenSigStartValue" SG_ 825 PM_AUTHPstState 0;
BA_ "GenSigTimeoutValue" SG_ 825 PM_AUTHPstState 0;
BA_ "Remark" SG_ 825 PM_AUTHPstState "";
BA_ "EventCommandSignal" SG_ 825 CCU_FuncReq_SentryMod 0;
BA_ "GatewayedSignals" SG_ 825 CCU_FuncReq_SentryMod 0;
BA_ "GenSigInactiveValue" SG_ 825 CCU_FuncReq_SentryMod 0;
BA_ "GenSigInvalidValue" SG_ 825 CCU_FuncReq_SentryMod 0;
BA_ "GenSigSendType" SG_ 825 CCU_FuncReq_SentryMod 1;
BA_ "GenSigStartValue" SG_ 825 CCU_FuncReq_SentryMod 0;
BA_ "GenSigTimeoutValue" SG_ 825 CCU_FuncReq_SentryMod 0;
BA_ "Remark" SG_ 825 CCU_FuncReq_SentryMod "";
BA_ "EventCommandSignal" SG_ 825 RLS_WindShieldHum 0;
BA_ "GatewayedSignals" SG_ 825 RLS_WindShieldHum 0;
BA_ "GenSigInactiveValue" SG_ 825 RLS_WindShieldHum 0;
BA_ "GenSigInvalidValue" SG_ 825 RLS_WindShieldHum 0;
BA_ "GenSigSendType" SG_ 825 RLS_WindShieldHum 1;
BA_ "GenSigStartValue" SG_ 825 RLS_WindShieldHum 0;
BA_ "GenSigTimeoutValue" SG_ 825 RLS_WindShieldHum 0;
BA_ "Remark" SG_ 825 RLS_WindShieldHum "";
BA_ "EventCommandSignal" SG_ 825 RLS_WindShieldTem 0;
BA_ "GatewayedSignals" SG_ 825 RLS_WindShieldTem 0;
BA_ "GenSigInactiveValue" SG_ 825 RLS_WindShieldTem 0;
BA_ "GenSigInvalidValue" SG_ 825 RLS_WindShieldTem 0;
BA_ "GenSigSendType" SG_ 825 RLS_WindShieldTem 1;
BA_ "GenSigStartValue" SG_ 825 RLS_WindShieldTem 254;
BA_ "GenSigTimeoutValue" SG_ 825 RLS_WindShieldTem 0;
BA_ "Remark" SG_ 825 RLS_WindShieldTem "";
BA_ "EventCommandSignal" SG_ 825 RLS_DewPoint 0;
BA_ "GatewayedSignals" SG_ 825 RLS_DewPoint 0;
BA_ "GenSigInactiveValue" SG_ 825 RLS_DewPoint 0;
BA_ "GenSigInvalidValue" SG_ 825 RLS_DewPoint 0;
BA_ "GenSigSendType" SG_ 825 RLS_DewPoint 1;
BA_ "GenSigStartValue" SG_ 825 RLS_DewPoint 254;
BA_ "GenSigTimeoutValue" SG_ 825 RLS_DewPoint 0;
BA_ "Remark" SG_ 825 RLS_DewPoint "";
BA_ "EventCommandSignal" SG_ 825 CCU_ModeSuppressSts 0;
BA_ "GatewayedSignals" SG_ 825 CCU_ModeSuppressSts 0;
BA_ "GenSigInactiveValue" SG_ 825 CCU_ModeSuppressSts 0;
BA_ "GenSigInvalidValue" SG_ 825 CCU_ModeSuppressSts 0;
BA_ "GenSigSendType" SG_ 825 CCU_ModeSuppressSts 1;
BA_ "GenSigStartValue" SG_ 825 CCU_ModeSuppressSts 0;
BA_ "GenSigTimeoutValue" SG_ 825 CCU_ModeSuppressSts 0;
BA_ "Remark" SG_ 825 CCU_ModeSuppressSts "";
BA_ "EventCommandSignal" SG_ 825 RLS_HUTErr 0;
BA_ "GatewayedSignals" SG_ 825 RLS_HUTErr 0;
BA_ "GenSigInactiveValue" SG_ 825 RLS_HUTErr 0;
BA_ "GenSigInvalidValue" SG_ 825 RLS_HUTErr 0;
BA_ "GenSigSendType" SG_ 825 RLS_HUTErr 1;
BA_ "GenSigStartValue" SG_ 825 RLS_HUTErr 0;
BA_ "GenSigTimeoutValue" SG_ 825 RLS_HUTErr 0;
BA_ "Remark" SG_ 825 RLS_HUTErr "";
BA_ "EventCommandSignal" SG_ 825 SR_SunroofCurrentPst 0;
BA_ "GatewayedSignals" SG_ 825 SR_SunroofCurrentPst 0;
BA_ "GenSigInactiveValue" SG_ 825 SR_SunroofCurrentPst 0;
BA_ "GenSigInvalidValue" SG_ 825 SR_SunroofCurrentPst 0;
BA_ "GenSigSendType" SG_ 825 SR_SunroofCurrentPst 1;
BA_ "GenSigStartValue" SG_ 825 SR_SunroofCurrentPst 255;
BA_ "GenSigTimeoutValue" SG_ 825 SR_SunroofCurrentPst 0;
BA_ "Remark" SG_ 825 SR_SunroofCurrentPst "";
BA_ "EventCommandSignal" SG_ 291 CCU_6_CRC 0;
BA_ "GatewayedSignals" SG_ 291 CCU_6_CRC 0;
BA_ "GenSigInactiveValue" SG_ 291 CCU_6_CRC 0;
BA_ "GenSigInvalidValue" SG_ 291 CCU_6_CRC 0;
BA_ "GenSigSendType" SG_ 291 CCU_6_CRC 1;
BA_ "GenSigStartValue" SG_ 291 CCU_6_CRC 0;
BA_ "GenSigTimeoutValue" SG_ 291 CCU_6_CRC 0;
BA_ "Remark" SG_ 291 CCU_6_CRC "";
BA_ "EventCommandSignal" SG_ 291 CCU_6_Counter 0;
BA_ "GatewayedSignals" SG_ 291 CCU_6_Counter 0;
BA_ "GenSigInactiveValue" SG_ 291 CCU_6_Counter 0;
BA_ "GenSigInvalidValue" SG_ 291 CCU_6_Counter 0;
BA_ "GenSigSendType" SG_ 291 CCU_6_Counter 1;
BA_ "GenSigStartValue" SG_ 291 CCU_6_Counter 0;
BA_ "GenSigTimeoutValue" SG_ 291 CCU_6_Counter 0;
BA_ "Remark" SG_ 291 CCU_6_Counter "";
BA_ "EventCommandSignal" SG_ 291 ATWS_ATWSAlarmReq 0;
BA_ "GatewayedSignals" SG_ 291 ATWS_ATWSAlarmReq 0;
BA_ "GenSigInactiveValue" SG_ 291 ATWS_ATWSAlarmReq 0;
BA_ "GenSigInvalidValue" SG_ 291 ATWS_ATWSAlarmReq 0;
BA_ "GenSigSendType" SG_ 291 ATWS_ATWSAlarmReq 1;
BA_ "GenSigStartValue" SG_ 291 ATWS_ATWSAlarmReq 0;
BA_ "GenSigTimeoutValue" SG_ 291 ATWS_ATWSAlarmReq 0;
BA_ "Remark" SG_ 291 ATWS_ATWSAlarmReq "";
BA_ "EventCommandSignal" SG_ 291 ATWS_ATWSSt 0;
BA_ "GatewayedSignals" SG_ 291 ATWS_ATWSSt 0;
BA_ "GenSigInactiveValue" SG_ 291 ATWS_ATWSSt 0;
BA_ "GenSigInvalidValue" SG_ 291 ATWS_ATWSSt 0;
BA_ "GenSigSendType" SG_ 291 ATWS_ATWSSt 1;
BA_ "GenSigStartValue" SG_ 291 ATWS_ATWSSt 0;
BA_ "GenSigTimeoutValue" SG_ 291 ATWS_ATWSSt 0;
BA_ "Remark" SG_ 291 ATWS_ATWSSt "";
BA_ "EventCommandSignal" SG_ 291 WW_FrontWasherCmd 0;
BA_ "GatewayedSignals" SG_ 291 WW_FrontWasherCmd 0;
BA_ "GenSigInactiveValue" SG_ 291 WW_FrontWasherCmd 0;
BA_ "GenSigInvalidValue" SG_ 291 WW_FrontWasherCmd 0;
BA_ "GenSigSendType" SG_ 291 WW_FrontWasherCmd 1;
BA_ "GenSigStartValue" SG_ 291 WW_FrontWasherCmd 0;
BA_ "GenSigTimeoutValue" SG_ 291 WW_FrontWasherCmd 0;
BA_ "Remark" SG_ 291 WW_FrontWasherCmd "";
BA_ "EventCommandSignal" SG_ 291 WW_FrtWiperAutoAvl 0;
BA_ "GatewayedSignals" SG_ 291 WW_FrtWiperAutoAvl 0;
BA_ "GenSigInactiveValue" SG_ 291 WW_FrtWiperAutoAvl 0;
BA_ "GenSigInvalidValue" SG_ 291 WW_FrtWiperAutoAvl 0;
BA_ "GenSigSendType" SG_ 291 WW_FrtWiperAutoAvl 1;
BA_ "GenSigStartValue" SG_ 291 WW_FrtWiperAutoAvl 0;
BA_ "GenSigTimeoutValue" SG_ 291 WW_FrtWiperAutoAvl 0;
BA_ "Remark" SG_ 291 WW_FrtWiperAutoAvl "";
BA_ "EventCommandSignal" SG_ 291 WW_FrontWiperCmd_Speed 0;
BA_ "GatewayedSignals" SG_ 291 WW_FrontWiperCmd_Speed 0;
BA_ "GenSigInactiveValue" SG_ 291 WW_FrontWiperCmd_Speed 0;
BA_ "GenSigInvalidValue" SG_ 291 WW_FrontWiperCmd_Speed 0;
BA_ "GenSigSendType" SG_ 291 WW_FrontWiperCmd_Speed 1;
BA_ "GenSigStartValue" SG_ 291 WW_FrontWiperCmd_Speed 0;
BA_ "GenSigTimeoutValue" SG_ 291 WW_FrontWiperCmd_Speed 0;
BA_ "Remark" SG_ 291 WW_FrontWiperCmd_Speed "";
BA_ "EventCommandSignal" SG_ 291 WW_RearWiperCtrlSt 0;
BA_ "GatewayedSignals" SG_ 291 WW_RearWiperCtrlSt 0;
BA_ "GenSigInactiveValue" SG_ 291 WW_RearWiperCtrlSt 0;
BA_ "GenSigInvalidValue" SG_ 291 WW_RearWiperCtrlSt 0;
BA_ "GenSigSendType" SG_ 291 WW_RearWiperCtrlSt 1;
BA_ "GenSigStartValue" SG_ 291 WW_RearWiperCtrlSt 0;
BA_ "GenSigTimeoutValue" SG_ 291 WW_RearWiperCtrlSt 0;
BA_ "Remark" SG_ 291 WW_RearWiperCtrlSt "";
BA_ "EventCommandSignal" SG_ 291 WW_FrontWiperCtrlSt 0;
BA_ "GatewayedSignals" SG_ 291 WW_FrontWiperCtrlSt 0;
BA_ "GenSigInactiveValue" SG_ 291 WW_FrontWiperCtrlSt 0;
BA_ "GenSigInvalidValue" SG_ 291 WW_FrontWiperCtrlSt 0;
BA_ "GenSigSendType" SG_ 291 WW_FrontWiperCtrlSt 1;
BA_ "GenSigStartValue" SG_ 291 WW_FrontWiperCtrlSt 0;
BA_ "GenSigTimeoutValue" SG_ 291 WW_FrontWiperCtrlSt 0;
BA_ "Remark" SG_ 291 WW_FrontWiperCtrlSt "";
BA_ "EventCommandSignal" SG_ 291 WW_FrontWiperCtrlSrc 0;
BA_ "GatewayedSignals" SG_ 291 WW_FrontWiperCtrlSrc 0;
BA_ "GenSigInactiveValue" SG_ 291 WW_FrontWiperCtrlSrc 0;
BA_ "GenSigInvalidValue" SG_ 291 WW_FrontWiperCtrlSrc 0;
BA_ "GenSigSendType" SG_ 291 WW_FrontWiperCtrlSrc 1;
BA_ "GenSigStartValue" SG_ 291 WW_FrontWiperCtrlSrc 0;
BA_ "GenSigTimeoutValue" SG_ 291 WW_FrontWiperCtrlSrc 0;
BA_ "Remark" SG_ 291 WW_FrontWiperCtrlSrc "";
BA_ "EventCommandSignal" SG_ 291 WW_RearWiperCtrlSrc 0;
BA_ "GatewayedSignals" SG_ 291 WW_RearWiperCtrlSrc 0;
BA_ "GenSigInactiveValue" SG_ 291 WW_RearWiperCtrlSrc 0;
BA_ "GenSigInvalidValue" SG_ 291 WW_RearWiperCtrlSrc 0;
BA_ "GenSigSendType" SG_ 291 WW_RearWiperCtrlSrc 1;
BA_ "GenSigStartValue" SG_ 291 WW_RearWiperCtrlSrc 0;
BA_ "GenSigTimeoutValue" SG_ 291 WW_RearWiperCtrlSrc 0;
BA_ "Remark" SG_ 291 WW_RearWiperCtrlSrc "";
BA_ "EventCommandSignal" SG_ 291 WW_RearCamWasherVKResp 0;
BA_ "GatewayedSignals" SG_ 291 WW_RearCamWasherVKResp 0;
BA_ "GenSigInactiveValue" SG_ 291 WW_RearCamWasherVKResp 0;
BA_ "GenSigInvalidValue" SG_ 291 WW_RearCamWasherVKResp 3;
BA_ "GenSigSendType" SG_ 291 WW_RearCamWasherVKResp 1;
BA_ "GenSigStartValue" SG_ 291 WW_RearCamWasherVKResp 0;
BA_ "GenSigTimeoutValue" SG_ 291 WW_RearCamWasherVKResp 0;
BA_ "Remark" SG_ 291 WW_RearCamWasherVKResp "";
BA_ "EventCommandSignal" SG_ 291 WW_RearCamWasherVRResp 0;
BA_ "GatewayedSignals" SG_ 291 WW_RearCamWasherVRResp 0;
BA_ "GenSigInactiveValue" SG_ 291 WW_RearCamWasherVRResp 0;
BA_ "GenSigInvalidValue" SG_ 291 WW_RearCamWasherVRResp 3;
BA_ "GenSigSendType" SG_ 291 WW_RearCamWasherVRResp 1;
BA_ "GenSigStartValue" SG_ 291 WW_RearCamWasherVRResp 0;
BA_ "GenSigTimeoutValue" SG_ 291 WW_RearCamWasherVRResp 0;
BA_ "Remark" SG_ 291 WW_RearCamWasherVRResp "";
BA_ "EventCommandSignal" SG_ 865 EL_ReverseLightCtrlCmd 0;
BA_ "GatewayedSignals" SG_ 865 EL_ReverseLightCtrlCmd 0;
BA_ "GenSigInactiveValue" SG_ 865 EL_ReverseLightCtrlCmd 0;
BA_ "GenSigInvalidValue" SG_ 865 EL_ReverseLightCtrlCmd 0;
BA_ "GenSigSendType" SG_ 865 EL_ReverseLightCtrlCmd 1;
BA_ "GenSigStartValue" SG_ 865 EL_ReverseLightCtrlCmd 0;
BA_ "GenSigTimeoutValue" SG_ 865 EL_ReverseLightCtrlCmd 0;
BA_ "Remark" SG_ 865 EL_ReverseLightCtrlCmd "";
BA_ "EventCommandSignal" SG_ 865 EL_SideBrkLightCtrlCmd 0;
BA_ "GatewayedSignals" SG_ 865 EL_SideBrkLightCtrlCmd 0;
BA_ "GenSigInactiveValue" SG_ 865 EL_SideBrkLightCtrlCmd 0;
BA_ "GenSigInvalidValue" SG_ 865 EL_SideBrkLightCtrlCmd 0;
BA_ "GenSigSendType" SG_ 865 EL_SideBrkLightCtrlCmd 1;
BA_ "GenSigStartValue" SG_ 865 EL_SideBrkLightCtrlCmd 0;
BA_ "GenSigTimeoutValue" SG_ 865 EL_SideBrkLightCtrlCmd 0;
BA_ "Remark" SG_ 865 EL_SideBrkLightCtrlCmd "";
BA_ "EventCommandSignal" SG_ 865 EL_LeftLowBeamCtrlCmd 0;
BA_ "GatewayedSignals" SG_ 865 EL_LeftLowBeamCtrlCmd 0;
BA_ "GenSigInactiveValue" SG_ 865 EL_LeftLowBeamCtrlCmd 0;
BA_ "GenSigInvalidValue" SG_ 865 EL_LeftLowBeamCtrlCmd 0;
BA_ "GenSigSendType" SG_ 865 EL_LeftLowBeamCtrlCmd 1;
BA_ "GenSigStartValue" SG_ 865 EL_LeftLowBeamCtrlCmd 0;
BA_ "GenSigTimeoutValue" SG_ 865 EL_LeftLowBeamCtrlCmd 0;
BA_ "Remark" SG_ 865 EL_LeftLowBeamCtrlCmd "";
BA_ "EventCommandSignal" SG_ 865 EL_RightLowBeamCtrlCmd 0;
BA_ "GatewayedSignals" SG_ 865 EL_RightLowBeamCtrlCmd 0;
BA_ "GenSigInactiveValue" SG_ 865 EL_RightLowBeamCtrlCmd 0;
BA_ "GenSigInvalidValue" SG_ 865 EL_RightLowBeamCtrlCmd 0;
BA_ "GenSigSendType" SG_ 865 EL_RightLowBeamCtrlCmd 1;
BA_ "GenSigStartValue" SG_ 865 EL_RightLowBeamCtrlCmd 0;
BA_ "GenSigTimeoutValue" SG_ 865 EL_RightLowBeamCtrlCmd 0;
BA_ "Remark" SG_ 865 EL_RightLowBeamCtrlCmd "";
BA_ "EventCommandSignal" SG_ 865 EL_PositionLightCtrlSource 0;
BA_ "GatewayedSignals" SG_ 865 EL_PositionLightCtrlSource 0;
BA_ "GenSigInactiveValue" SG_ 865 EL_PositionLightCtrlSource 0;
BA_ "GenSigInvalidValue" SG_ 865 EL_PositionLightCtrlSource 0;
BA_ "GenSigSendType" SG_ 865 EL_PositionLightCtrlSource 1;
BA_ "GenSigStartValue" SG_ 865 EL_PositionLightCtrlSource 0;
BA_ "GenSigTimeoutValue" SG_ 865 EL_PositionLightCtrlSource 0;
BA_ "Remark" SG_ 865 EL_PositionLightCtrlSource "";
BA_ "EventCommandSignal" SG_ 865 EL_LeftHighBeamCtrlCmd 0;
BA_ "GatewayedSignals" SG_ 865 EL_LeftHighBeamCtrlCmd 0;
BA_ "GenSigInactiveValue" SG_ 865 EL_LeftHighBeamCtrlCmd 0;
BA_ "GenSigInvalidValue" SG_ 865 EL_LeftHighBeamCtrlCmd 0;
BA_ "GenSigSendType" SG_ 865 EL_LeftHighBeamCtrlCmd 1;
BA_ "GenSigStartValue" SG_ 865 EL_LeftHighBeamCtrlCmd 0;
BA_ "GenSigTimeoutValue" SG_ 865 EL_LeftHighBeamCtrlCmd 0;
BA_ "Remark" SG_ 865 EL_LeftHighBeamCtrlCmd "";
BA_ "EventCommandSignal" SG_ 865 EL_RightHighBeamCtrlCmd 0;
BA_ "GatewayedSignals" SG_ 865 EL_RightHighBeamCtrlCmd 0;
BA_ "GenSigInactiveValue" SG_ 865 EL_RightHighBeamCtrlCmd 0;
BA_ "GenSigInvalidValue" SG_ 865 EL_RightHighBeamCtrlCmd 0;
BA_ "GenSigSendType" SG_ 865 EL_RightHighBeamCtrlCmd 1;
BA_ "GenSigStartValue" SG_ 865 EL_RightHighBeamCtrlCmd 0;
BA_ "GenSigTimeoutValue" SG_ 865 EL_RightHighBeamCtrlCmd 0;
BA_ "Remark" SG_ 865 EL_RightHighBeamCtrlCmd "";
BA_ "EventCommandSignal" SG_ 865 EL_LowBeamCtrlSource 0;
BA_ "GatewayedSignals" SG_ 865 EL_LowBeamCtrlSource 0;
BA_ "GenSigInactiveValue" SG_ 865 EL_LowBeamCtrlSource 0;
BA_ "GenSigInvalidValue" SG_ 865 EL_LowBeamCtrlSource 0;
BA_ "GenSigSendType" SG_ 865 EL_LowBeamCtrlSource 1;
BA_ "GenSigStartValue" SG_ 865 EL_LowBeamCtrlSource 0;
BA_ "GenSigTimeoutValue" SG_ 865 EL_LowBeamCtrlSource 0;
BA_ "Remark" SG_ 865 EL_LowBeamCtrlSource "";
BA_ "EventCommandSignal" SG_ 865 EL_RearFogLightCtrlSource 0;
BA_ "GatewayedSignals" SG_ 865 EL_RearFogLightCtrlSource 0;
BA_ "GenSigInactiveValue" SG_ 865 EL_RearFogLightCtrlSource 0;
BA_ "GenSigInvalidValue" SG_ 865 EL_RearFogLightCtrlSource 0;
BA_ "GenSigSendType" SG_ 865 EL_RearFogLightCtrlSource 1;
BA_ "GenSigStartValue" SG_ 865 EL_RearFogLightCtrlSource 0;
BA_ "GenSigTimeoutValue" SG_ 865 EL_RearFogLightCtrlSource 0;
BA_ "Remark" SG_ 865 EL_RearFogLightCtrlSource "";
BA_ "EventCommandSignal" SG_ 865 EL_HighBeamCtrlSource 0;
BA_ "GatewayedSignals" SG_ 865 EL_HighBeamCtrlSource 0;
BA_ "GenSigInactiveValue" SG_ 865 EL_HighBeamCtrlSource 0;
BA_ "GenSigInvalidValue" SG_ 865 EL_HighBeamCtrlSource 0;
BA_ "GenSigSendType" SG_ 865 EL_HighBeamCtrlSource 1;
BA_ "GenSigStartValue" SG_ 865 EL_HighBeamCtrlSource 0;
BA_ "GenSigTimeoutValue" SG_ 865 EL_HighBeamCtrlSource 0;
BA_ "Remark" SG_ 865 EL_HighBeamCtrlSource "";
BA_ "EventCommandSignal" SG_ 865 EL_FrontFogLightCtrlSource 0;
BA_ "GatewayedSignals" SG_ 865 EL_FrontFogLightCtrlSource 0;
BA_ "GenSigInactiveValue" SG_ 865 EL_FrontFogLightCtrlSource 0;
BA_ "GenSigInvalidValue" SG_ 865 EL_FrontFogLightCtrlSource 0;
BA_ "GenSigSendType" SG_ 865 EL_FrontFogLightCtrlSource 1;
BA_ "GenSigStartValue" SG_ 865 EL_FrontFogLightCtrlSource 0;
BA_ "GenSigTimeoutValue" SG_ 865 EL_FrontFogLightCtrlSource 0;
BA_ "Remark" SG_ 865 EL_FrontFogLightCtrlSource "";
BA_ "EventCommandSignal" SG_ 865 EL_LicencePlateLightCtrlSource 0;
BA_ "GatewayedSignals" SG_ 865 EL_LicencePlateLightCtrlSource 0;
BA_ "GenSigInactiveValue" SG_ 865 EL_LicencePlateLightCtrlSource 0;
BA_ "GenSigInvalidValue" SG_ 865 EL_LicencePlateLightCtrlSource 0;
BA_ "GenSigSendType" SG_ 865 EL_LicencePlateLightCtrlSource 1;
BA_ "GenSigStartValue" SG_ 865 EL_LicencePlateLightCtrlSource 0;
BA_ "GenSigTimeoutValue" SG_ 865 EL_LicencePlateLightCtrlSource 0;
BA_ "Remark" SG_ 865 EL_LicencePlateLightCtrlSource "";
BA_ "EventCommandSignal" SG_ 865 EL_FlasherCtrlSource 0;
BA_ "GatewayedSignals" SG_ 865 EL_FlasherCtrlSource 0;
BA_ "GenSigInactiveValue" SG_ 865 EL_FlasherCtrlSource 0;
BA_ "GenSigInvalidValue" SG_ 865 EL_FlasherCtrlSource 0;
BA_ "GenSigSendType" SG_ 865 EL_FlasherCtrlSource 1;
BA_ "GenSigStartValue" SG_ 865 EL_FlasherCtrlSource 0;
BA_ "GenSigTimeoutValue" SG_ 865 EL_FlasherCtrlSource 0;
BA_ "Remark" SG_ 865 EL_FlasherCtrlSource "";
BA_ "EventCommandSignal" SG_ 865 EL_FADASLightCtrlCmd 0;
BA_ "GatewayedSignals" SG_ 865 EL_FADASLightCtrlCmd 0;
BA_ "GenSigInactiveValue" SG_ 865 EL_FADASLightCtrlCmd 0;
BA_ "GenSigInvalidValue" SG_ 865 EL_FADASLightCtrlCmd 0;
BA_ "GenSigSendType" SG_ 865 EL_FADASLightCtrlCmd 1;
BA_ "GenSigStartValue" SG_ 865 EL_FADASLightCtrlCmd 0;
BA_ "GenSigTimeoutValue" SG_ 865 EL_FADASLightCtrlCmd 0;
BA_ "Remark" SG_ 865 EL_FADASLightCtrlCmd "";
BA_ "EventCommandSignal" SG_ 865 EL_RADASLightCtrlCmd 0;
BA_ "GatewayedSignals" SG_ 865 EL_RADASLightCtrlCmd 0;
BA_ "GenSigInactiveValue" SG_ 865 EL_RADASLightCtrlCmd 0;
BA_ "GenSigInvalidValue" SG_ 865 EL_RADASLightCtrlCmd 0;
BA_ "GenSigSendType" SG_ 865 EL_RADASLightCtrlCmd 1;
BA_ "GenSigStartValue" SG_ 865 EL_RADASLightCtrlCmd 0;
BA_ "GenSigTimeoutValue" SG_ 865 EL_RADASLightCtrlCmd 0;
BA_ "Remark" SG_ 865 EL_RADASLightCtrlCmd "";
BA_ "EventCommandSignal" SG_ 865 EL_IHBColourSt 0;
BA_ "GatewayedSignals" SG_ 865 EL_IHBColourSt 0;
BA_ "GenSigInactiveValue" SG_ 865 EL_IHBColourSt 0;
BA_ "GenSigInvalidValue" SG_ 865 EL_IHBColourSt 0;
BA_ "GenSigSendType" SG_ 865 EL_IHBColourSt 1;
BA_ "GenSigStartValue" SG_ 865 EL_IHBColourSt 0;
BA_ "GenSigTimeoutValue" SG_ 865 EL_IHBColourSt 0;
BA_ "Remark" SG_ 865 EL_IHBColourSt "";
BA_ "EventCommandSignal" SG_ 865 EL_AutoHighBeamCtrlSt 0;
BA_ "GatewayedSignals" SG_ 865 EL_AutoHighBeamCtrlSt 0;
BA_ "GenSigInactiveValue" SG_ 865 EL_AutoHighBeamCtrlSt 0;
BA_ "GenSigInvalidValue" SG_ 865 EL_AutoHighBeamCtrlSt 0;
BA_ "GenSigSendType" SG_ 865 EL_AutoHighBeamCtrlSt 1;
BA_ "GenSigStartValue" SG_ 865 EL_AutoHighBeamCtrlSt 0;
BA_ "GenSigTimeoutValue" SG_ 865 EL_AutoHighBeamCtrlSt 0;
BA_ "Remark" SG_ 865 EL_AutoHighBeamCtrlSt "";
BA_ "EventCommandSignal" SG_ 865 EL_ADBEnable 0;
BA_ "GatewayedSignals" SG_ 865 EL_ADBEnable 0;
BA_ "GenSigInactiveValue" SG_ 865 EL_ADBEnable 0;
BA_ "GenSigInvalidValue" SG_ 865 EL_ADBEnable 0;
BA_ "GenSigSendType" SG_ 865 EL_ADBEnable 1;
BA_ "GenSigStartValue" SG_ 865 EL_ADBEnable 1;
BA_ "GenSigTimeoutValue" SG_ 865 EL_ADBEnable 0;
BA_ "Remark" SG_ 865 EL_ADBEnable "";
BA_ "EventCommandSignal" SG_ 865 EL_ADC_2_VERFailFlag 0;
BA_ "GatewayedSignals" SG_ 865 EL_ADC_2_VERFailFlag 0;
BA_ "GenSigInactiveValue" SG_ 865 EL_ADC_2_VERFailFlag 0;
BA_ "GenSigInvalidValue" SG_ 865 EL_ADC_2_VERFailFlag 0;
BA_ "GenSigSendType" SG_ 865 EL_ADC_2_VERFailFlag 1;
BA_ "GenSigStartValue" SG_ 865 EL_ADC_2_VERFailFlag 0;
BA_ "GenSigTimeoutValue" SG_ 865 EL_ADC_2_VERFailFlag 0;
BA_ "Remark" SG_ 865 EL_ADC_2_VERFailFlag "";
BA_ "EventCommandSignal" SG_ 865 EL_ADC_4_New_VERFailFlag 0;
BA_ "GatewayedSignals" SG_ 865 EL_ADC_4_New_VERFailFlag 0;
BA_ "GenSigInactiveValue" SG_ 865 EL_ADC_4_New_VERFailFlag 0;
BA_ "GenSigInvalidValue" SG_ 865 EL_ADC_4_New_VERFailFlag 0;
BA_ "GenSigSendType" SG_ 865 EL_ADC_4_New_VERFailFlag 1;
BA_ "GenSigStartValue" SG_ 865 EL_ADC_4_New_VERFailFlag 0;
BA_ "GenSigTimeoutValue" SG_ 865 EL_ADC_4_New_VERFailFlag 0;
BA_ "Remark" SG_ 865 EL_ADC_4_New_VERFailFlag "";
BA_ "EventCommandSignal" SG_ 865 EL_ADC_8_VERFailFlag 0;
BA_ "GatewayedSignals" SG_ 865 EL_ADC_8_VERFailFlag 0;
BA_ "GenSigInactiveValue" SG_ 865 EL_ADC_8_VERFailFlag 0;
BA_ "GenSigInvalidValue" SG_ 865 EL_ADC_8_VERFailFlag 0;
BA_ "GenSigSendType" SG_ 865 EL_ADC_8_VERFailFlag 1;
BA_ "GenSigStartValue" SG_ 865 EL_ADC_8_VERFailFlag 0;
BA_ "GenSigTimeoutValue" SG_ 865 EL_ADC_8_VERFailFlag 0;
BA_ "Remark" SG_ 865 EL_ADC_8_VERFailFlag "";
BA_ "EventCommandSignal" SG_ 865 EL_HeadLightLevelingSWSt 0;
BA_ "GatewayedSignals" SG_ 865 EL_HeadLightLevelingSWSt 0;
BA_ "GenSigInactiveValue" SG_ 865 EL_HeadLightLevelingSWSt 0;
BA_ "GenSigInvalidValue" SG_ 865 EL_HeadLightLevelingSWSt 0;
BA_ "GenSigSendType" SG_ 865 EL_HeadLightLevelingSWSt 1;
BA_ "GenSigStartValue" SG_ 865 EL_HeadLightLevelingSWSt 0;
BA_ "GenSigTimeoutValue" SG_ 865 EL_HeadLightLevelingSWSt 0;
BA_ "Remark" SG_ 865 EL_HeadLightLevelingSWSt "";
BA_ "EventCommandSignal" SG_ 865 EL_LeftTurnLightStForDisp 0;
BA_ "GatewayedSignals" SG_ 865 EL_LeftTurnLightStForDisp 0;
BA_ "GenSigInactiveValue" SG_ 865 EL_LeftTurnLightStForDisp 0;
BA_ "GenSigInvalidValue" SG_ 865 EL_LeftTurnLightStForDisp 0;
BA_ "GenSigSendType" SG_ 865 EL_LeftTurnLightStForDisp 1;
BA_ "GenSigStartValue" SG_ 865 EL_LeftTurnLightStForDisp 0;
BA_ "GenSigTimeoutValue" SG_ 865 EL_LeftTurnLightStForDisp 0;
BA_ "Remark" SG_ 865 EL_LeftTurnLightStForDisp "";
BA_ "EventCommandSignal" SG_ 865 EL_RightTurnLightStForDisp 0;
BA_ "GatewayedSignals" SG_ 865 EL_RightTurnLightStForDisp 0;
BA_ "GenSigInactiveValue" SG_ 865 EL_RightTurnLightStForDisp 0;
BA_ "GenSigInvalidValue" SG_ 865 EL_RightTurnLightStForDisp 0;
BA_ "GenSigSendType" SG_ 865 EL_RightTurnLightStForDisp 1;
BA_ "GenSigStartValue" SG_ 865 EL_RightTurnLightStForDisp 0;
BA_ "GenSigTimeoutValue" SG_ 865 EL_RightTurnLightStForDisp 0;
BA_ "Remark" SG_ 865 EL_RightTurnLightStForDisp "";
BA_ "EventCommandSignal" SG_ 865 EL_PositionLightStForDisp 0;
BA_ "GatewayedSignals" SG_ 865 EL_PositionLightStForDisp 0;
BA_ "GenSigInactiveValue" SG_ 865 EL_PositionLightStForDisp 0;
BA_ "GenSigInvalidValue" SG_ 865 EL_PositionLightStForDisp 0;
BA_ "GenSigSendType" SG_ 865 EL_PositionLightStForDisp 1;
BA_ "GenSigStartValue" SG_ 865 EL_PositionLightStForDisp 0;
BA_ "GenSigTimeoutValue" SG_ 865 EL_PositionLightStForDisp 0;
BA_ "Remark" SG_ 865 EL_PositionLightStForDisp "";
BA_ "EventCommandSignal" SG_ 865 EL_FrontFogLightStForDisp 0;
BA_ "GatewayedSignals" SG_ 865 EL_FrontFogLightStForDisp 0;
BA_ "GenSigInactiveValue" SG_ 865 EL_FrontFogLightStForDisp 0;
BA_ "GenSigInvalidValue" SG_ 865 EL_FrontFogLightStForDisp 0;
BA_ "GenSigSendType" SG_ 865 EL_FrontFogLightStForDisp 1;
BA_ "GenSigStartValue" SG_ 865 EL_FrontFogLightStForDisp 0;
BA_ "GenSigTimeoutValue" SG_ 865 EL_FrontFogLightStForDisp 0;
BA_ "Remark" SG_ 865 EL_FrontFogLightStForDisp "";
BA_ "EventCommandSignal" SG_ 865 EL_RearFogLightStForDisp 0;
BA_ "GatewayedSignals" SG_ 865 EL_RearFogLightStForDisp 0;
BA_ "GenSigInactiveValue" SG_ 865 EL_RearFogLightStForDisp 0;
BA_ "GenSigInvalidValue" SG_ 865 EL_RearFogLightStForDisp 0;
BA_ "GenSigSendType" SG_ 865 EL_RearFogLightStForDisp 1;
BA_ "GenSigStartValue" SG_ 865 EL_RearFogLightStForDisp 0;
BA_ "GenSigTimeoutValue" SG_ 865 EL_RearFogLightStForDisp 0;
BA_ "Remark" SG_ 865 EL_RearFogLightStForDisp "";
BA_ "EventCommandSignal" SG_ 865 EL_LowBeamStForDisp 0;
BA_ "GatewayedSignals" SG_ 865 EL_LowBeamStForDisp 0;
BA_ "GenSigInactiveValue" SG_ 865 EL_LowBeamStForDisp 0;
BA_ "GenSigInvalidValue" SG_ 865 EL_LowBeamStForDisp 0;
BA_ "GenSigSendType" SG_ 865 EL_LowBeamStForDisp 1;
BA_ "GenSigStartValue" SG_ 865 EL_LowBeamStForDisp 0;
BA_ "GenSigTimeoutValue" SG_ 865 EL_LowBeamStForDisp 0;
BA_ "Remark" SG_ 865 EL_LowBeamStForDisp "";
BA_ "EventCommandSignal" SG_ 865 EL_HighBeamStForDisp 0;
BA_ "GatewayedSignals" SG_ 865 EL_HighBeamStForDisp 0;
BA_ "GenSigInactiveValue" SG_ 865 EL_HighBeamStForDisp 0;
BA_ "GenSigInvalidValue" SG_ 865 EL_HighBeamStForDisp 0;
BA_ "GenSigSendType" SG_ 865 EL_HighBeamStForDisp 1;
BA_ "GenSigStartValue" SG_ 865 EL_HighBeamStForDisp 0;
BA_ "GenSigTimeoutValue" SG_ 865 EL_HighBeamStForDisp 0;
BA_ "Remark" SG_ 865 EL_HighBeamStForDisp "";
BA_ "EventCommandSignal" SG_ 865 EL_HeadLightSWSt 0;
BA_ "GatewayedSignals" SG_ 865 EL_HeadLightSWSt 0;
BA_ "GenSigInactiveValue" SG_ 865 EL_HeadLightSWSt 0;
BA_ "GenSigInvalidValue" SG_ 865 EL_HeadLightSWSt 0;
BA_ "GenSigSendType" SG_ 865 EL_HeadLightSWSt 1;
BA_ "GenSigStartValue" SG_ 865 EL_HeadLightSWSt 0;
BA_ "GenSigTimeoutValue" SG_ 865 EL_HeadLightSWSt 0;
BA_ "Remark" SG_ 865 EL_HeadLightSWSt "";
BA_ "EventCommandSignal" SG_ 293 TPMS_FrontLeftTireBlowout 1;
BA_ "GatewayedSignals" SG_ 293 TPMS_FrontLeftTireBlowout 0;
BA_ "GenSigInactiveValue" SG_ 293 TPMS_FrontLeftTireBlowout 0;
BA_ "GenSigInvalidValue" SG_ 293 TPMS_FrontLeftTireBlowout 0;
BA_ "GenSigSendType" SG_ 293 TPMS_FrontLeftTireBlowout 0;
BA_ "GenSigStartValue" SG_ 293 TPMS_FrontLeftTireBlowout 0;
BA_ "GenSigTimeoutValue" SG_ 293 TPMS_FrontLeftTireBlowout 0;
BA_ "Remark" SG_ 293 TPMS_FrontLeftTireBlowout "";
BA_ "EventCommandSignal" SG_ 293 TPMS_FrontRightTireBlowout 1;
BA_ "GatewayedSignals" SG_ 293 TPMS_FrontRightTireBlowout 0;
BA_ "GenSigInactiveValue" SG_ 293 TPMS_FrontRightTireBlowout 0;
BA_ "GenSigInvalidValue" SG_ 293 TPMS_FrontRightTireBlowout 0;
BA_ "GenSigSendType" SG_ 293 TPMS_FrontRightTireBlowout 0;
BA_ "GenSigStartValue" SG_ 293 TPMS_FrontRightTireBlowout 0;
BA_ "GenSigTimeoutValue" SG_ 293 TPMS_FrontRightTireBlowout 0;
BA_ "Remark" SG_ 293 TPMS_FrontRightTireBlowout "";
BA_ "EventCommandSignal" SG_ 293 TPMS_RearRightTireBlowout 1;
BA_ "GatewayedSignals" SG_ 293 TPMS_RearRightTireBlowout 0;
BA_ "GenSigInactiveValue" SG_ 293 TPMS_RearRightTireBlowout 0;
BA_ "GenSigInvalidValue" SG_ 293 TPMS_RearRightTireBlowout 0;
BA_ "GenSigSendType" SG_ 293 TPMS_RearRightTireBlowout 0;
BA_ "GenSigStartValue" SG_ 293 TPMS_RearRightTireBlowout 0;
BA_ "GenSigTimeoutValue" SG_ 293 TPMS_RearRightTireBlowout 0;
BA_ "Remark" SG_ 293 TPMS_RearRightTireBlowout "";
BA_ "EventCommandSignal" SG_ 293 TPMS_RearLeftTireBlowout 1;
BA_ "GatewayedSignals" SG_ 293 TPMS_RearLeftTireBlowout 0;
BA_ "GenSigInactiveValue" SG_ 293 TPMS_RearLeftTireBlowout 0;
BA_ "GenSigInvalidValue" SG_ 293 TPMS_RearLeftTireBlowout 0;
BA_ "GenSigSendType" SG_ 293 TPMS_RearLeftTireBlowout 0;
BA_ "GenSigStartValue" SG_ 293 TPMS_RearLeftTireBlowout 0;
BA_ "GenSigTimeoutValue" SG_ 293 TPMS_RearLeftTireBlowout 0;
BA_ "Remark" SG_ 293 TPMS_RearLeftTireBlowout "";
BA_ "EventCommandSignal" SG_ 293 TPMS_FrontLeftTirePressure 0;
BA_ "GatewayedSignals" SG_ 293 TPMS_FrontLeftTirePressure 0;
BA_ "GenSigInactiveValue" SG_ 293 TPMS_FrontLeftTirePressure 0;
BA_ "GenSigInvalidValue" SG_ 293 TPMS_FrontLeftTirePressure 0;
BA_ "GenSigSendType" SG_ 293 TPMS_FrontLeftTirePressure 1;
BA_ "GenSigStartValue" SG_ 293 TPMS_FrontLeftTirePressure 255;
BA_ "GenSigTimeoutValue" SG_ 293 TPMS_FrontLeftTirePressure 255;
BA_ "Remark" SG_ 293 TPMS_FrontLeftTirePressure "";
BA_ "EventCommandSignal" SG_ 293 TPMS_FrontRightTirePressure 0;
BA_ "GatewayedSignals" SG_ 293 TPMS_FrontRightTirePressure 0;
BA_ "GenSigInactiveValue" SG_ 293 TPMS_FrontRightTirePressure 0;
BA_ "GenSigInvalidValue" SG_ 293 TPMS_FrontRightTirePressure 0;
BA_ "GenSigSendType" SG_ 293 TPMS_FrontRightTirePressure 1;
BA_ "GenSigStartValue" SG_ 293 TPMS_FrontRightTirePressure 255;
BA_ "GenSigTimeoutValue" SG_ 293 TPMS_FrontRightTirePressure 255;
BA_ "Remark" SG_ 293 TPMS_FrontRightTirePressure "";
BA_ "EventCommandSignal" SG_ 293 TPMS_RearRightTirePressure 0;
BA_ "GatewayedSignals" SG_ 293 TPMS_RearRightTirePressure 0;
BA_ "GenSigInactiveValue" SG_ 293 TPMS_RearRightTirePressure 0;
BA_ "GenSigInvalidValue" SG_ 293 TPMS_RearRightTirePressure 0;
BA_ "GenSigSendType" SG_ 293 TPMS_RearRightTirePressure 1;
BA_ "GenSigStartValue" SG_ 293 TPMS_RearRightTirePressure 255;
BA_ "GenSigTimeoutValue" SG_ 293 TPMS_RearRightTirePressure 255;
BA_ "Remark" SG_ 293 TPMS_RearRightTirePressure "";
BA_ "EventCommandSignal" SG_ 293 TPMS_RearLeftTirePressure 0;
BA_ "GatewayedSignals" SG_ 293 TPMS_RearLeftTirePressure 0;
BA_ "GenSigInactiveValue" SG_ 293 TPMS_RearLeftTirePressure 0;
BA_ "GenSigInvalidValue" SG_ 293 TPMS_RearLeftTirePressure 0;
BA_ "GenSigSendType" SG_ 293 TPMS_RearLeftTirePressure 1;
BA_ "GenSigStartValue" SG_ 293 TPMS_RearLeftTirePressure 255;
BA_ "GenSigTimeoutValue" SG_ 293 TPMS_RearLeftTirePressure 255;
BA_ "Remark" SG_ 293 TPMS_RearLeftTirePressure "";
BA_ "EventCommandSignal" SG_ 293 TPMS_TireWarningLamp 1;
BA_ "GatewayedSignals" SG_ 293 TPMS_TireWarningLamp 0;
BA_ "GenSigInactiveValue" SG_ 293 TPMS_TireWarningLamp 0;
BA_ "GenSigInvalidValue" SG_ 293 TPMS_TireWarningLamp 0;
BA_ "GenSigSendType" SG_ 293 TPMS_TireWarningLamp 0;
BA_ "GenSigStartValue" SG_ 293 TPMS_TireWarningLamp 0;
BA_ "GenSigTimeoutValue" SG_ 293 TPMS_TireWarningLamp 0;
BA_ "Remark" SG_ 293 TPMS_TireWarningLamp "";
BA_ "EventCommandSignal" SG_ 293 TPMS_SystemWarningLamp 1;
BA_ "GatewayedSignals" SG_ 293 TPMS_SystemWarningLamp 0;
BA_ "GenSigInactiveValue" SG_ 293 TPMS_SystemWarningLamp 0;
BA_ "GenSigInvalidValue" SG_ 293 TPMS_SystemWarningLamp 0;
BA_ "GenSigSendType" SG_ 293 TPMS_SystemWarningLamp 0;
BA_ "GenSigStartValue" SG_ 293 TPMS_SystemWarningLamp 0;
BA_ "GenSigTimeoutValue" SG_ 293 TPMS_SystemWarningLamp 0;
BA_ "Remark" SG_ 293 TPMS_SystemWarningLamp "";
BA_ "EventCommandSignal" SG_ 294 LCK_DriverDoorAjarSt 1;
BA_ "GatewayedSignals" SG_ 294 LCK_DriverDoorAjarSt 0;
BA_ "GenSigInactiveValue" SG_ 294 LCK_DriverDoorAjarSt 0;
BA_ "GenSigInvalidValue" SG_ 294 LCK_DriverDoorAjarSt 0;
BA_ "GenSigSendType" SG_ 294 LCK_DriverDoorAjarSt 0;
BA_ "GenSigStartValue" SG_ 294 LCK_DriverDoorAjarSt 0;
BA_ "GenSigTimeoutValue" SG_ 294 LCK_DriverDoorAjarSt 0;
BA_ "Remark" SG_ 294 LCK_DriverDoorAjarSt "";
BA_ "EventCommandSignal" SG_ 294 LCK_PassengerDoorAjarSt 1;
BA_ "GatewayedSignals" SG_ 294 LCK_PassengerDoorAjarSt 0;
BA_ "GenSigInactiveValue" SG_ 294 LCK_PassengerDoorAjarSt 0;
BA_ "GenSigInvalidValue" SG_ 294 LCK_PassengerDoorAjarSt 0;
BA_ "GenSigSendType" SG_ 294 LCK_PassengerDoorAjarSt 0;
BA_ "GenSigStartValue" SG_ 294 LCK_PassengerDoorAjarSt 0;
BA_ "GenSigTimeoutValue" SG_ 294 LCK_PassengerDoorAjarSt 0;
BA_ "Remark" SG_ 294 LCK_PassengerDoorAjarSt "";
BA_ "EventCommandSignal" SG_ 294 LCK_DriverDoorLockSt 1;
BA_ "GatewayedSignals" SG_ 294 LCK_DriverDoorLockSt 0;
BA_ "GenSigInactiveValue" SG_ 294 LCK_DriverDoorLockSt 0;
BA_ "GenSigInvalidValue" SG_ 294 LCK_DriverDoorLockSt 0;
BA_ "GenSigSendType" SG_ 294 LCK_DriverDoorLockSt 0;
BA_ "GenSigStartValue" SG_ 294 LCK_DriverDoorLockSt 0;
BA_ "GenSigTimeoutValue" SG_ 294 LCK_DriverDoorLockSt 0;
BA_ "Remark" SG_ 294 LCK_DriverDoorLockSt "";
BA_ "EventCommandSignal" SG_ 294 LCK_PassengerDoorLockSt 1;
BA_ "GatewayedSignals" SG_ 294 LCK_PassengerDoorLockSt 0;
BA_ "GenSigInactiveValue" SG_ 294 LCK_PassengerDoorLockSt 0;
BA_ "GenSigInvalidValue" SG_ 294 LCK_PassengerDoorLockSt 0;
BA_ "GenSigSendType" SG_ 294 LCK_PassengerDoorLockSt 0;
BA_ "GenSigStartValue" SG_ 294 LCK_PassengerDoorLockSt 0;
BA_ "GenSigTimeoutValue" SG_ 294 LCK_PassengerDoorLockSt 0;
BA_ "Remark" SG_ 294 LCK_PassengerDoorLockSt "";
BA_ "EventCommandSignal" SG_ 294 LCK_VehicleDoorAjarSt 1;
BA_ "GatewayedSignals" SG_ 294 LCK_VehicleDoorAjarSt 0;
BA_ "GenSigInactiveValue" SG_ 294 LCK_VehicleDoorAjarSt 0;
BA_ "GenSigInvalidValue" SG_ 294 LCK_VehicleDoorAjarSt 0;
BA_ "GenSigSendType" SG_ 294 LCK_VehicleDoorAjarSt 0;
BA_ "GenSigStartValue" SG_ 294 LCK_VehicleDoorAjarSt 0;
BA_ "GenSigTimeoutValue" SG_ 294 LCK_VehicleDoorAjarSt 0;
BA_ "Remark" SG_ 294 LCK_VehicleDoorAjarSt "";
BA_ "EventCommandSignal" SG_ 294 LCK_VehicleDoorLockSt 1;
BA_ "GatewayedSignals" SG_ 294 LCK_VehicleDoorLockSt 0;
BA_ "GenSigInactiveValue" SG_ 294 LCK_VehicleDoorLockSt 0;
BA_ "GenSigInvalidValue" SG_ 294 LCK_VehicleDoorLockSt 0;
BA_ "GenSigSendType" SG_ 294 LCK_VehicleDoorLockSt 0;
BA_ "GenSigStartValue" SG_ 294 LCK_VehicleDoorLockSt 0;
BA_ "GenSigTimeoutValue" SG_ 294 LCK_VehicleDoorLockSt 0;
BA_ "Remark" SG_ 294 LCK_VehicleDoorLockSt "";
BA_ "EventCommandSignal" SG_ 294 LCK_VehicleChildSaftyLockSt 1;
BA_ "GatewayedSignals" SG_ 294 LCK_VehicleChildSaftyLockSt 0;
BA_ "GenSigInactiveValue" SG_ 294 LCK_VehicleChildSaftyLockSt 0;
BA_ "GenSigInvalidValue" SG_ 294 LCK_VehicleChildSaftyLockSt 0;
BA_ "GenSigSendType" SG_ 294 LCK_VehicleChildSaftyLockSt 0;
BA_ "GenSigStartValue" SG_ 294 LCK_VehicleChildSaftyLockSt 0;
BA_ "GenSigTimeoutValue" SG_ 294 LCK_VehicleChildSaftyLockSt 0;
BA_ "Remark" SG_ 294 LCK_VehicleChildSaftyLockSt "";
BA_ "EventCommandSignal" SG_ 294 LCK_VehicleChildSaftyLockedIndicate 1;
BA_ "GatewayedSignals" SG_ 294 LCK_VehicleChildSaftyLockedIndicate 0;
BA_ "GenSigInactiveValue" SG_ 294 LCK_VehicleChildSaftyLockedIndicate 0;
BA_ "GenSigInvalidValue" SG_ 294 LCK_VehicleChildSaftyLockedIndicate 0;
BA_ "GenSigSendType" SG_ 294 LCK_VehicleChildSaftyLockedIndicate 0;
BA_ "GenSigStartValue" SG_ 294 LCK_VehicleChildSaftyLockedIndicate 0;
BA_ "GenSigTimeoutValue" SG_ 294 LCK_VehicleChildSaftyLockedIndicate 0;
BA_ "Remark" SG_ 294 LCK_VehicleChildSaftyLockedIndicate "";
BA_ "EventCommandSignal" SG_ 294 CCU_9_FreshnessValue 0;
BA_ "GatewayedSignals" SG_ 294 CCU_9_FreshnessValue 0;
BA_ "GenSigInactiveValue" SG_ 294 CCU_9_FreshnessValue 0;
BA_ "GenSigInvalidValue" SG_ 294 CCU_9_FreshnessValue 0;
BA_ "GenSigSendType" SG_ 294 CCU_9_FreshnessValue 1;
BA_ "GenSigStartValue" SG_ 294 CCU_9_FreshnessValue 0;
BA_ "GenSigTimeoutValue" SG_ 294 CCU_9_FreshnessValue 0;
BA_ "Remark" SG_ 294 CCU_9_FreshnessValue "";
BA_ "EventCommandSignal" SG_ 294 CCU_9_MAC_Check 0;
BA_ "GatewayedSignals" SG_ 294 CCU_9_MAC_Check 0;
BA_ "GenSigInactiveValue" SG_ 294 CCU_9_MAC_Check 0;
BA_ "GenSigInvalidValue" SG_ 294 CCU_9_MAC_Check 0;
BA_ "GenSigSendType" SG_ 294 CCU_9_MAC_Check 1;
BA_ "GenSigStartValue" SG_ 294 CCU_9_MAC_Check 0;
BA_ "GenSigTimeoutValue" SG_ 294 CCU_9_MAC_Check 0;
BA_ "Remark" SG_ 294 CCU_9_MAC_Check "";
BA_ "EventCommandSignal" SG_ 1359 CCU_NMNodeAddress 0;
BA_ "GatewayedSignals" SG_ 1359 CCU_NMNodeAddress 0;
BA_ "GenSigInactiveValue" SG_ 1359 CCU_NMNodeAddress 0;
BA_ "GenSigInvalidValue" SG_ 1359 CCU_NMNodeAddress 0;
BA_ "GenSigSendType" SG_ 1359 CCU_NMNodeAddress 1;
BA_ "GenSigStartValue" SG_ 1359 CCU_NMNodeAddress 79;
BA_ "GenSigTimeoutValue" SG_ 1359 CCU_NMNodeAddress 0;
BA_ "Remark" SG_ 1359 CCU_NMNodeAddress "";
BA_ "EventCommandSignal" SG_ 1359 CCU_NMCBV 0;
BA_ "GatewayedSignals" SG_ 1359 CCU_NMCBV 0;
BA_ "GenSigInactiveValue" SG_ 1359 CCU_NMCBV 0;
BA_ "GenSigInvalidValue" SG_ 1359 CCU_NMCBV 0;
BA_ "GenSigSendType" SG_ 1359 CCU_NMCBV 1;
BA_ "GenSigStartValue" SG_ 1359 CCU_NMCBV 0;
BA_ "GenSigTimeoutValue" SG_ 1359 CCU_NMCBV 0;
BA_ "Remark" SG_ 1359 CCU_NMCBV "";
BA_ "EventCommandSignal" SG_ 1359 CCU_NMWakeupOrigin 0;
BA_ "GatewayedSignals" SG_ 1359 CCU_NMWakeupOrigin 0;
BA_ "GenSigInactiveValue" SG_ 1359 CCU_NMWakeupOrigin 0;
BA_ "GenSigInvalidValue" SG_ 1359 CCU_NMWakeupOrigin 0;
BA_ "GenSigSendType" SG_ 1359 CCU_NMWakeupOrigin 1;
BA_ "GenSigStartValue" SG_ 1359 CCU_NMWakeupOrigin 0;
BA_ "GenSigTimeoutValue" SG_ 1359 CCU_NMWakeupOrigin 0;
BA_ "Remark" SG_ 1359 CCU_NMWakeupOrigin "";
BA_ "EventCommandSignal" SG_ 1359 CCU_PNCInformation0 0;
BA_ "GatewayedSignals" SG_ 1359 CCU_PNCInformation0 0;
BA_ "GenSigInactiveValue" SG_ 1359 CCU_PNCInformation0 0;
BA_ "GenSigInvalidValue" SG_ 1359 CCU_PNCInformation0 0;
BA_ "GenSigSendType" SG_ 1359 CCU_PNCInformation0 1;
BA_ "GenSigStartValue" SG_ 1359 CCU_PNCInformation0 0;
BA_ "GenSigTimeoutValue" SG_ 1359 CCU_PNCInformation0 0;
BA_ "Remark" SG_ 1359 CCU_PNCInformation0 "";
BA_ "EventCommandSignal" SG_ 1359 CCU_PNCInformation1 0;
BA_ "GatewayedSignals" SG_ 1359 CCU_PNCInformation1 0;
BA_ "GenSigInactiveValue" SG_ 1359 CCU_PNCInformation1 0;
BA_ "GenSigInvalidValue" SG_ 1359 CCU_PNCInformation1 0;
BA_ "GenSigSendType" SG_ 1359 CCU_PNCInformation1 1;
BA_ "GenSigStartValue" SG_ 1359 CCU_PNCInformation1 0;
BA_ "GenSigTimeoutValue" SG_ 1359 CCU_PNCInformation1 0;
BA_ "Remark" SG_ 1359 CCU_PNCInformation1 "";
BA_ "EventCommandSignal" SG_ 1359 CCU_PNCInformation2 0;
BA_ "GatewayedSignals" SG_ 1359 CCU_PNCInformation2 0;
BA_ "GenSigInactiveValue" SG_ 1359 CCU_PNCInformation2 0;
BA_ "GenSigInvalidValue" SG_ 1359 CCU_PNCInformation2 0;
BA_ "GenSigSendType" SG_ 1359 CCU_PNCInformation2 1;
BA_ "GenSigStartValue" SG_ 1359 CCU_PNCInformation2 0;
BA_ "GenSigTimeoutValue" SG_ 1359 CCU_PNCInformation2 0;
BA_ "Remark" SG_ 1359 CCU_PNCInformation2 "";
BA_ "EventCommandSignal" SG_ 615 BCS_1_CRC 0;
BA_ "GatewayedSignals" SG_ 615 BCS_1_CRC 0;
BA_ "GenSigInactiveValue" SG_ 615 BCS_1_CRC 0;
BA_ "GenSigInvalidValue" SG_ 615 BCS_1_CRC 0;
BA_ "GenSigSendType" SG_ 615 BCS_1_CRC 1;
BA_ "GenSigStartValue" SG_ 615 BCS_1_CRC 0;
BA_ "GenSigTimeoutValue" SG_ 615 BCS_1_CRC 0;
BA_ "Remark" SG_ 615 BCS_1_CRC "";
BA_ "EventCommandSignal" SG_ 615 BCS_1_Counter 0;
BA_ "GatewayedSignals" SG_ 615 BCS_1_Counter 0;
BA_ "GenSigInactiveValue" SG_ 615 BCS_1_Counter 0;
BA_ "GenSigInvalidValue" SG_ 615 BCS_1_Counter 0;
BA_ "GenSigSendType" SG_ 615 BCS_1_Counter 1;
BA_ "GenSigStartValue" SG_ 615 BCS_1_Counter 0;
BA_ "GenSigTimeoutValue" SG_ 615 BCS_1_Counter 0;
BA_ "Remark" SG_ 615 BCS_1_Counter "";
BA_ "EventCommandSignal" SG_ 615 BCS_FLWheelSpd 0;
BA_ "GatewayedSignals" SG_ 615 BCS_FLWheelSpd 0;
BA_ "GenSigInactiveValue" SG_ 615 BCS_FLWheelSpd 0;
BA_ "GenSigInvalidValue" SG_ 615 BCS_FLWheelSpd 0;
BA_ "GenSigSendType" SG_ 615 BCS_FLWheelSpd 1;
BA_ "GenSigStartValue" SG_ 615 BCS_FLWheelSpd 0;
BA_ "GenSigTimeoutValue" SG_ 615 BCS_FLWheelSpd 0;
BA_ "Remark" SG_ 615 BCS_FLWheelSpd "";
BA_ "EventCommandSignal" SG_ 615 BCS_FLWheelSpdVD 0;
BA_ "GatewayedSignals" SG_ 615 BCS_FLWheelSpdVD 0;
BA_ "GenSigInactiveValue" SG_ 615 BCS_FLWheelSpdVD 0;
BA_ "GenSigInvalidValue" SG_ 615 BCS_FLWheelSpdVD 0;
BA_ "GenSigSendType" SG_ 615 BCS_FLWheelSpdVD 1;
BA_ "GenSigStartValue" SG_ 615 BCS_FLWheelSpdVD 0;
BA_ "GenSigTimeoutValue" SG_ 615 BCS_FLWheelSpdVD 0;
BA_ "Remark" SG_ 615 BCS_FLWheelSpdVD "";
BA_ "EventCommandSignal" SG_ 615 BCS_FLWheelRotatedDirection 0;
BA_ "GatewayedSignals" SG_ 615 BCS_FLWheelRotatedDirection 0;
BA_ "GenSigInactiveValue" SG_ 615 BCS_FLWheelRotatedDirection 0;
BA_ "GenSigInvalidValue" SG_ 615 BCS_FLWheelRotatedDirection 0;
BA_ "GenSigSendType" SG_ 615 BCS_FLWheelRotatedDirection 1;
BA_ "GenSigStartValue" SG_ 615 BCS_FLWheelRotatedDirection 0;
BA_ "GenSigTimeoutValue" SG_ 615 BCS_FLWheelRotatedDirection 0;
BA_ "Remark" SG_ 615 BCS_FLWheelRotatedDirection "";
BA_ "EventCommandSignal" SG_ 615 BCS_FLWheelRotatedDirectionVD 0;
BA_ "GatewayedSignals" SG_ 615 BCS_FLWheelRotatedDirectionVD 0;
BA_ "GenSigInactiveValue" SG_ 615 BCS_FLWheelRotatedDirectionVD 0;
BA_ "GenSigInvalidValue" SG_ 615 BCS_FLWheelRotatedDirectionVD 0;
BA_ "GenSigSendType" SG_ 615 BCS_FLWheelRotatedDirectionVD 1;
BA_ "GenSigStartValue" SG_ 615 BCS_FLWheelRotatedDirectionVD 0;
BA_ "GenSigTimeoutValue" SG_ 615 BCS_FLWheelRotatedDirectionVD 0;
BA_ "Remark" SG_ 615 BCS_FLWheelRotatedDirectionVD "";
BA_ "EventCommandSignal" SG_ 615 BCS_FRWheelSpd 0;
BA_ "GatewayedSignals" SG_ 615 BCS_FRWheelSpd 0;
BA_ "GenSigInactiveValue" SG_ 615 BCS_FRWheelSpd 0;
BA_ "GenSigInvalidValue" SG_ 615 BCS_FRWheelSpd 0;
BA_ "GenSigSendType" SG_ 615 BCS_FRWheelSpd 1;
BA_ "GenSigStartValue" SG_ 615 BCS_FRWheelSpd 0;
BA_ "GenSigTimeoutValue" SG_ 615 BCS_FRWheelSpd 0;
BA_ "Remark" SG_ 615 BCS_FRWheelSpd "";
BA_ "EventCommandSignal" SG_ 615 BCS_FRWheelSpdVD 0;
BA_ "GatewayedSignals" SG_ 615 BCS_FRWheelSpdVD 0;
BA_ "GenSigInactiveValue" SG_ 615 BCS_FRWheelSpdVD 0;
BA_ "GenSigInvalidValue" SG_ 615 BCS_FRWheelSpdVD 0;
BA_ "GenSigSendType" SG_ 615 BCS_FRWheelSpdVD 1;
BA_ "GenSigStartValue" SG_ 615 BCS_FRWheelSpdVD 0;
BA_ "GenSigTimeoutValue" SG_ 615 BCS_FRWheelSpdVD 0;
BA_ "Remark" SG_ 615 BCS_FRWheelSpdVD "";
BA_ "EventCommandSignal" SG_ 615 BCS_FRWheelRotatedDirection 0;
BA_ "GatewayedSignals" SG_ 615 BCS_FRWheelRotatedDirection 0;
BA_ "GenSigInactiveValue" SG_ 615 BCS_FRWheelRotatedDirection 0;
BA_ "GenSigInvalidValue" SG_ 615 BCS_FRWheelRotatedDirection 0;
BA_ "GenSigSendType" SG_ 615 BCS_FRWheelRotatedDirection 1;
BA_ "GenSigStartValue" SG_ 615 BCS_FRWheelRotatedDirection 0;
BA_ "GenSigTimeoutValue" SG_ 615 BCS_FRWheelRotatedDirection 0;
BA_ "Remark" SG_ 615 BCS_FRWheelRotatedDirection "";
BA_ "EventCommandSignal" SG_ 615 BCS_FRWheelRotatedDirectionVD 0;
BA_ "GatewayedSignals" SG_ 615 BCS_FRWheelRotatedDirectionVD 0;
BA_ "GenSigInactiveValue" SG_ 615 BCS_FRWheelRotatedDirectionVD 0;
BA_ "GenSigInvalidValue" SG_ 615 BCS_FRWheelRotatedDirectionVD 0;
BA_ "GenSigSendType" SG_ 615 BCS_FRWheelRotatedDirectionVD 1;
BA_ "GenSigStartValue" SG_ 615 BCS_FRWheelRotatedDirectionVD 0;
BA_ "GenSigTimeoutValue" SG_ 615 BCS_FRWheelRotatedDirectionVD 0;
BA_ "Remark" SG_ 615 BCS_FRWheelRotatedDirectionVD "";
BA_ "EventCommandSignal" SG_ 615 BCS_RLWheelSpd 0;
BA_ "GatewayedSignals" SG_ 615 BCS_RLWheelSpd 0;
BA_ "GenSigInactiveValue" SG_ 615 BCS_RLWheelSpd 0;
BA_ "GenSigInvalidValue" SG_ 615 BCS_RLWheelSpd 0;
BA_ "GenSigSendType" SG_ 615 BCS_RLWheelSpd 1;
BA_ "GenSigStartValue" SG_ 615 BCS_RLWheelSpd 0;
BA_ "GenSigTimeoutValue" SG_ 615 BCS_RLWheelSpd 0;
BA_ "Remark" SG_ 615 BCS_RLWheelSpd "";
BA_ "EventCommandSignal" SG_ 615 BCS_RLWheelSpdVD 0;
BA_ "GatewayedSignals" SG_ 615 BCS_RLWheelSpdVD 0;
BA_ "GenSigInactiveValue" SG_ 615 BCS_RLWheelSpdVD 0;
BA_ "GenSigInvalidValue" SG_ 615 BCS_RLWheelSpdVD 0;
BA_ "GenSigSendType" SG_ 615 BCS_RLWheelSpdVD 1;
BA_ "GenSigStartValue" SG_ 615 BCS_RLWheelSpdVD 0;
BA_ "GenSigTimeoutValue" SG_ 615 BCS_RLWheelSpdVD 0;
BA_ "Remark" SG_ 615 BCS_RLWheelSpdVD "";
BA_ "EventCommandSignal" SG_ 615 BCS_RLWheelRotatedDirection 0;
BA_ "GatewayedSignals" SG_ 615 BCS_RLWheelRotatedDirection 0;
BA_ "GenSigInactiveValue" SG_ 615 BCS_RLWheelRotatedDirection 0;
BA_ "GenSigInvalidValue" SG_ 615 BCS_RLWheelRotatedDirection 0;
BA_ "GenSigSendType" SG_ 615 BCS_RLWheelRotatedDirection 1;
BA_ "GenSigStartValue" SG_ 615 BCS_RLWheelRotatedDirection 0;
BA_ "GenSigTimeoutValue" SG_ 615 BCS_RLWheelRotatedDirection 0;
BA_ "Remark" SG_ 615 BCS_RLWheelRotatedDirection "";
BA_ "EventCommandSignal" SG_ 615 BCS_RLWheelRotatedDirectionVD 0;
BA_ "GatewayedSignals" SG_ 615 BCS_RLWheelRotatedDirectionVD 0;
BA_ "GenSigInactiveValue" SG_ 615 BCS_RLWheelRotatedDirectionVD 0;
BA_ "GenSigInvalidValue" SG_ 615 BCS_RLWheelRotatedDirectionVD 0;
BA_ "GenSigSendType" SG_ 615 BCS_RLWheelRotatedDirectionVD 1;
BA_ "GenSigStartValue" SG_ 615 BCS_RLWheelRotatedDirectionVD 0;
BA_ "GenSigTimeoutValue" SG_ 615 BCS_RLWheelRotatedDirectionVD 0;
BA_ "Remark" SG_ 615 BCS_RLWheelRotatedDirectionVD "";
BA_ "EventCommandSignal" SG_ 615 BCS_RRWheelSpd 0;
BA_ "GatewayedSignals" SG_ 615 BCS_RRWheelSpd 0;
BA_ "GenSigInactiveValue" SG_ 615 BCS_RRWheelSpd 0;
BA_ "GenSigInvalidValue" SG_ 615 BCS_RRWheelSpd 0;
BA_ "GenSigSendType" SG_ 615 BCS_RRWheelSpd 1;
BA_ "GenSigStartValue" SG_ 615 BCS_RRWheelSpd 0;
BA_ "GenSigTimeoutValue" SG_ 615 BCS_RRWheelSpd 0;
BA_ "Remark" SG_ 615 BCS_RRWheelSpd "";
BA_ "EventCommandSignal" SG_ 615 BCS_RRWheelSpdVD 0;
BA_ "GatewayedSignals" SG_ 615 BCS_RRWheelSpdVD 0;
BA_ "GenSigInactiveValue" SG_ 615 BCS_RRWheelSpdVD 0;
BA_ "GenSigInvalidValue" SG_ 615 BCS_RRWheelSpdVD 0;
BA_ "GenSigSendType" SG_ 615 BCS_RRWheelSpdVD 1;
BA_ "GenSigStartValue" SG_ 615 BCS_RRWheelSpdVD 0;
BA_ "GenSigTimeoutValue" SG_ 615 BCS_RRWheelSpdVD 0;
BA_ "Remark" SG_ 615 BCS_RRWheelSpdVD "";
BA_ "EventCommandSignal" SG_ 615 BCS_RRWheelRotatedDirection 0;
BA_ "GatewayedSignals" SG_ 615 BCS_RRWheelRotatedDirection 0;
BA_ "GenSigInactiveValue" SG_ 615 BCS_RRWheelRotatedDirection 0;
BA_ "GenSigInvalidValue" SG_ 615 BCS_RRWheelRotatedDirection 0;
BA_ "GenSigSendType" SG_ 615 BCS_RRWheelRotatedDirection 1;
BA_ "GenSigStartValue" SG_ 615 BCS_RRWheelRotatedDirection 0;
BA_ "GenSigTimeoutValue" SG_ 615 BCS_RRWheelRotatedDirection 0;
BA_ "Remark" SG_ 615 BCS_RRWheelRotatedDirection "";
BA_ "EventCommandSignal" SG_ 615 BCS_RRWheelRotatedDirectionVD 0;
BA_ "GatewayedSignals" SG_ 615 BCS_RRWheelRotatedDirectionVD 0;
BA_ "GenSigInactiveValue" SG_ 615 BCS_RRWheelRotatedDirectionVD 0;
BA_ "GenSigInvalidValue" SG_ 615 BCS_RRWheelRotatedDirectionVD 0;
BA_ "GenSigSendType" SG_ 615 BCS_RRWheelRotatedDirectionVD 1;
BA_ "GenSigStartValue" SG_ 615 BCS_RRWheelRotatedDirectionVD 0;
BA_ "GenSigTimeoutValue" SG_ 615 BCS_RRWheelRotatedDirectionVD 0;
BA_ "Remark" SG_ 615 BCS_RRWheelRotatedDirectionVD "";
BA_ "EventCommandSignal" SG_ 615 BCS_HHCCtrlSt 0;
BA_ "GatewayedSignals" SG_ 615 BCS_HHCCtrlSt 0;
BA_ "GenSigInactiveValue" SG_ 615 BCS_HHCCtrlSt 0;
BA_ "GenSigInvalidValue" SG_ 615 BCS_HHCCtrlSt 0;
BA_ "GenSigSendType" SG_ 615 BCS_HHCCtrlSt 1;
BA_ "GenSigStartValue" SG_ 615 BCS_HHCCtrlSt 0;
BA_ "GenSigTimeoutValue" SG_ 615 BCS_HHCCtrlSt 0;
BA_ "Remark" SG_ 615 BCS_HHCCtrlSt "";
BA_ "EventCommandSignal" SG_ 615 BCS_HDCCtrlSt 0;
BA_ "GatewayedSignals" SG_ 615 BCS_HDCCtrlSt 0;
BA_ "GenSigInactiveValue" SG_ 615 BCS_HDCCtrlSt 0;
BA_ "GenSigInvalidValue" SG_ 615 BCS_HDCCtrlSt 0;
BA_ "GenSigSendType" SG_ 615 BCS_HDCCtrlSt 1;
BA_ "GenSigStartValue" SG_ 615 BCS_HDCCtrlSt 0;
BA_ "GenSigTimeoutValue" SG_ 615 BCS_HDCCtrlSt 0;
BA_ "Remark" SG_ 615 BCS_HDCCtrlSt "";
BA_ "EventCommandSignal" SG_ 615 BCS_HDCErrSt 0;
BA_ "GatewayedSignals" SG_ 615 BCS_HDCErrSt 0;
BA_ "GenSigInactiveValue" SG_ 615 BCS_HDCErrSt 0;
BA_ "GenSigInvalidValue" SG_ 615 BCS_HDCErrSt 0;
BA_ "GenSigSendType" SG_ 615 BCS_HDCErrSt 1;
BA_ "GenSigStartValue" SG_ 615 BCS_HDCErrSt 0;
BA_ "GenSigTimeoutValue" SG_ 615 BCS_HDCErrSt 1;
BA_ "Remark" SG_ 615 BCS_HDCErrSt "";
BA_ "EventCommandSignal" SG_ 615 BCS_FLWheelSpdEdgesSum 0;
BA_ "GatewayedSignals" SG_ 615 BCS_FLWheelSpdEdgesSum 0;
BA_ "GenSigInactiveValue" SG_ 615 BCS_FLWheelSpdEdgesSum 0;
BA_ "GenSigInvalidValue" SG_ 615 BCS_FLWheelSpdEdgesSum 0;
BA_ "GenSigSendType" SG_ 615 BCS_FLWheelSpdEdgesSum 1;
BA_ "GenSigStartValue" SG_ 615 BCS_FLWheelSpdEdgesSum 0;
BA_ "GenSigTimeoutValue" SG_ 615 BCS_FLWheelSpdEdgesSum 0;
BA_ "Remark" SG_ 615 BCS_FLWheelSpdEdgesSum "";
BA_ "EventCommandSignal" SG_ 615 BCS_FRWheelSpdEdgesSum 0;
BA_ "GatewayedSignals" SG_ 615 BCS_FRWheelSpdEdgesSum 0;
BA_ "GenSigInactiveValue" SG_ 615 BCS_FRWheelSpdEdgesSum 0;
BA_ "GenSigInvalidValue" SG_ 615 BCS_FRWheelSpdEdgesSum 0;
BA_ "GenSigSendType" SG_ 615 BCS_FRWheelSpdEdgesSum 1;
BA_ "GenSigStartValue" SG_ 615 BCS_FRWheelSpdEdgesSum 0;
BA_ "GenSigTimeoutValue" SG_ 615 BCS_FRWheelSpdEdgesSum 0;
BA_ "Remark" SG_ 615 BCS_FRWheelSpdEdgesSum "";
BA_ "EventCommandSignal" SG_ 615 BCS_RLWheelSpdEdgesSum 0;
BA_ "GatewayedSignals" SG_ 615 BCS_RLWheelSpdEdgesSum 0;
BA_ "GenSigInactiveValue" SG_ 615 BCS_RLWheelSpdEdgesSum 0;
BA_ "GenSigInvalidValue" SG_ 615 BCS_RLWheelSpdEdgesSum 0;
BA_ "GenSigSendType" SG_ 615 BCS_RLWheelSpdEdgesSum 1;
BA_ "GenSigStartValue" SG_ 615 BCS_RLWheelSpdEdgesSum 0;
BA_ "GenSigTimeoutValue" SG_ 615 BCS_RLWheelSpdEdgesSum 0;
BA_ "Remark" SG_ 615 BCS_RLWheelSpdEdgesSum "";
BA_ "EventCommandSignal" SG_ 615 BCS_RRWheelSpdEdgesSum 0;
BA_ "GatewayedSignals" SG_ 615 BCS_RRWheelSpdEdgesSum 0;
BA_ "GenSigInactiveValue" SG_ 615 BCS_RRWheelSpdEdgesSum 0;
BA_ "GenSigInvalidValue" SG_ 615 BCS_RRWheelSpdEdgesSum 0;
BA_ "GenSigSendType" SG_ 615 BCS_RRWheelSpdEdgesSum 1;
BA_ "GenSigStartValue" SG_ 615 BCS_RRWheelSpdEdgesSum 0;
BA_ "GenSigTimeoutValue" SG_ 615 BCS_RRWheelSpdEdgesSum 0;
BA_ "Remark" SG_ 615 BCS_RRWheelSpdEdgesSum "";
BA_ "EventCommandSignal" SG_ 615 BCS_FLWheelSpdEdgesSumVD 0;
BA_ "GatewayedSignals" SG_ 615 BCS_FLWheelSpdEdgesSumVD 0;
BA_ "GenSigInactiveValue" SG_ 615 BCS_FLWheelSpdEdgesSumVD 0;
BA_ "GenSigInvalidValue" SG_ 615 BCS_FLWheelSpdEdgesSumVD 0;
BA_ "GenSigSendType" SG_ 615 BCS_FLWheelSpdEdgesSumVD 1;
BA_ "GenSigStartValue" SG_ 615 BCS_FLWheelSpdEdgesSumVD 0;
BA_ "GenSigTimeoutValue" SG_ 615 BCS_FLWheelSpdEdgesSumVD 0;
BA_ "Remark" SG_ 615 BCS_FLWheelSpdEdgesSumVD "";
BA_ "EventCommandSignal" SG_ 615 BCS_FRWheelSpdEdgesSumVD 0;
BA_ "GatewayedSignals" SG_ 615 BCS_FRWheelSpdEdgesSumVD 0;
BA_ "GenSigInactiveValue" SG_ 615 BCS_FRWheelSpdEdgesSumVD 0;
BA_ "GenSigInvalidValue" SG_ 615 BCS_FRWheelSpdEdgesSumVD 0;
BA_ "GenSigSendType" SG_ 615 BCS_FRWheelSpdEdgesSumVD 1;
BA_ "GenSigStartValue" SG_ 615 BCS_FRWheelSpdEdgesSumVD 0;
BA_ "GenSigTimeoutValue" SG_ 615 BCS_FRWheelSpdEdgesSumVD 0;
BA_ "Remark" SG_ 615 BCS_FRWheelSpdEdgesSumVD "";
BA_ "EventCommandSignal" SG_ 615 BCS_RLWheelSpdEdgesSumVD 0;
BA_ "GatewayedSignals" SG_ 615 BCS_RLWheelSpdEdgesSumVD 0;
BA_ "GenSigInactiveValue" SG_ 615 BCS_RLWheelSpdEdgesSumVD 0;
BA_ "GenSigInvalidValue" SG_ 615 BCS_RLWheelSpdEdgesSumVD 0;
BA_ "GenSigSendType" SG_ 615 BCS_RLWheelSpdEdgesSumVD 1;
BA_ "GenSigStartValue" SG_ 615 BCS_RLWheelSpdEdgesSumVD 0;
BA_ "GenSigTimeoutValue" SG_ 615 BCS_RLWheelSpdEdgesSumVD 0;
BA_ "Remark" SG_ 615 BCS_RLWheelSpdEdgesSumVD "";
BA_ "EventCommandSignal" SG_ 615 BCS_RRWheelSpdEdgesSumVD 0;
BA_ "GatewayedSignals" SG_ 615 BCS_RRWheelSpdEdgesSumVD 0;
BA_ "GenSigInactiveValue" SG_ 615 BCS_RRWheelSpdEdgesSumVD 0;
BA_ "GenSigInvalidValue" SG_ 615 BCS_RRWheelSpdEdgesSumVD 0;
BA_ "GenSigSendType" SG_ 615 BCS_RRWheelSpdEdgesSumVD 1;
BA_ "GenSigStartValue" SG_ 615 BCS_RRWheelSpdEdgesSumVD 0;
BA_ "GenSigTimeoutValue" SG_ 615 BCS_RRWheelSpdEdgesSumVD 0;
BA_ "Remark" SG_ 615 BCS_RRWheelSpdEdgesSumVD "";
BA_ "EventCommandSignal" SG_ 615 BCS_FLWheelRotatedDirectionAPA 0;
BA_ "GatewayedSignals" SG_ 615 BCS_FLWheelRotatedDirectionAPA 0;
BA_ "GenSigInactiveValue" SG_ 615 BCS_FLWheelRotatedDirectionAPA 0;
BA_ "GenSigInvalidValue" SG_ 615 BCS_FLWheelRotatedDirectionAPA 0;
BA_ "GenSigSendType" SG_ 615 BCS_FLWheelRotatedDirectionAPA 1;
BA_ "GenSigStartValue" SG_ 615 BCS_FLWheelRotatedDirectionAPA 0;
BA_ "GenSigTimeoutValue" SG_ 615 BCS_FLWheelRotatedDirectionAPA 0;
BA_ "Remark" SG_ 615 BCS_FLWheelRotatedDirectionAPA "";
BA_ "EventCommandSignal" SG_ 615 BCS_FRWheelRotatedDirectionAPA 0;
BA_ "GatewayedSignals" SG_ 615 BCS_FRWheelRotatedDirectionAPA 0;
BA_ "GenSigInactiveValue" SG_ 615 BCS_FRWheelRotatedDirectionAPA 0;
BA_ "GenSigInvalidValue" SG_ 615 BCS_FRWheelRotatedDirectionAPA 0;
BA_ "GenSigSendType" SG_ 615 BCS_FRWheelRotatedDirectionAPA 1;
BA_ "GenSigStartValue" SG_ 615 BCS_FRWheelRotatedDirectionAPA 0;
BA_ "GenSigTimeoutValue" SG_ 615 BCS_FRWheelRotatedDirectionAPA 0;
BA_ "Remark" SG_ 615 BCS_FRWheelRotatedDirectionAPA "";
BA_ "EventCommandSignal" SG_ 615 BCS_RLWheelRotatedDirectionAPA 0;
BA_ "GatewayedSignals" SG_ 615 BCS_RLWheelRotatedDirectionAPA 0;
BA_ "GenSigInactiveValue" SG_ 615 BCS_RLWheelRotatedDirectionAPA 0;
BA_ "GenSigInvalidValue" SG_ 615 BCS_RLWheelRotatedDirectionAPA 0;
BA_ "GenSigSendType" SG_ 615 BCS_RLWheelRotatedDirectionAPA 1;
BA_ "GenSigStartValue" SG_ 615 BCS_RLWheelRotatedDirectionAPA 0;
BA_ "GenSigTimeoutValue" SG_ 615 BCS_RLWheelRotatedDirectionAPA 0;
BA_ "Remark" SG_ 615 BCS_RLWheelRotatedDirectionAPA "";
BA_ "EventCommandSignal" SG_ 615 BCS_RRWheelRotatedDirectionAPA 0;
BA_ "GatewayedSignals" SG_ 615 BCS_RRWheelRotatedDirectionAPA 0;
BA_ "GenSigInactiveValue" SG_ 615 BCS_RRWheelRotatedDirectionAPA 0;
BA_ "GenSigInvalidValue" SG_ 615 BCS_RRWheelRotatedDirectionAPA 0;
BA_ "GenSigSendType" SG_ 615 BCS_RRWheelRotatedDirectionAPA 1;
BA_ "GenSigStartValue" SG_ 615 BCS_RRWheelRotatedDirectionAPA 0;
BA_ "GenSigTimeoutValue" SG_ 615 BCS_RRWheelRotatedDirectionAPA 0;
BA_ "Remark" SG_ 615 BCS_RRWheelRotatedDirectionAPA "";
BA_ "EventCommandSignal" SG_ 615 BCS_ParkingReqToEPB 0;
BA_ "GatewayedSignals" SG_ 615 BCS_ParkingReqToEPB 0;
BA_ "GenSigInactiveValue" SG_ 615 BCS_ParkingReqToEPB 0;
BA_ "GenSigInvalidValue" SG_ 615 BCS_ParkingReqToEPB 0;
BA_ "GenSigSendType" SG_ 615 BCS_ParkingReqToEPB 1;
BA_ "GenSigStartValue" SG_ 615 BCS_ParkingReqToEPB 0;
BA_ "GenSigTimeoutValue" SG_ 615 BCS_ParkingReqToEPB 0;
BA_ "Remark" SG_ 615 BCS_ParkingReqToEPB "";
BA_ "EventCommandSignal" SG_ 615 BCS_VDCOff 0;
BA_ "GatewayedSignals" SG_ 615 BCS_VDCOff 0;
BA_ "GenSigInactiveValue" SG_ 615 BCS_VDCOff 0;
BA_ "GenSigInvalidValue" SG_ 615 BCS_VDCOff 0;
BA_ "GenSigSendType" SG_ 615 BCS_VDCOff 1;
BA_ "GenSigStartValue" SG_ 615 BCS_VDCOff 0;
BA_ "GenSigTimeoutValue" SG_ 615 BCS_VDCOff 0;
BA_ "Remark" SG_ 615 BCS_VDCOff "";
BA_ "EventCommandSignal" SG_ 615 BCS_AVHSt 0;
BA_ "GatewayedSignals" SG_ 615 BCS_AVHSt 0;
BA_ "GenSigInactiveValue" SG_ 615 BCS_AVHSt 0;
BA_ "GenSigInvalidValue" SG_ 615 BCS_AVHSt 0;
BA_ "GenSigSendType" SG_ 615 BCS_AVHSt 1;
BA_ "GenSigStartValue" SG_ 615 BCS_AVHSt 0;
BA_ "GenSigTimeoutValue" SG_ 615 BCS_AVHSt 0;
BA_ "Remark" SG_ 615 BCS_AVHSt "";
BA_ "EventCommandSignal" SG_ 615 BCS_AVHAvailable 0;
BA_ "GatewayedSignals" SG_ 615 BCS_AVHAvailable 0;
BA_ "GenSigInactiveValue" SG_ 615 BCS_AVHAvailable 0;
BA_ "GenSigInvalidValue" SG_ 615 BCS_AVHAvailable 0;
BA_ "GenSigSendType" SG_ 615 BCS_AVHAvailable 1;
BA_ "GenSigStartValue" SG_ 615 BCS_AVHAvailable 0;
BA_ "GenSigTimeoutValue" SG_ 615 BCS_AVHAvailable 0;
BA_ "Remark" SG_ 615 BCS_AVHAvailable "";
BA_ "EventCommandSignal" SG_ 615 BCS_TCSOff 0;
BA_ "GatewayedSignals" SG_ 615 BCS_TCSOff 0;
BA_ "GenSigInactiveValue" SG_ 615 BCS_TCSOff 0;
BA_ "GenSigInvalidValue" SG_ 615 BCS_TCSOff 0;
BA_ "GenSigSendType" SG_ 615 BCS_TCSOff 1;
BA_ "GenSigStartValue" SG_ 615 BCS_TCSOff 0;
BA_ "GenSigTimeoutValue" SG_ 615 BCS_TCSOff 0;
BA_ "Remark" SG_ 615 BCS_TCSOff "";
BA_ "EventCommandSignal" SG_ 615 BCS_BrakeOverHeat 0;
BA_ "GatewayedSignals" SG_ 615 BCS_BrakeOverHeat 0;
BA_ "GenSigInactiveValue" SG_ 615 BCS_BrakeOverHeat 0;
BA_ "GenSigInvalidValue" SG_ 615 BCS_BrakeOverHeat 0;
BA_ "GenSigSendType" SG_ 615 BCS_BrakeOverHeat 1;
BA_ "GenSigStartValue" SG_ 615 BCS_BrakeOverHeat 0;
BA_ "GenSigTimeoutValue" SG_ 615 BCS_BrakeOverHeat 0;
BA_ "Remark" SG_ 615 BCS_BrakeOverHeat "";
BA_ "EventCommandSignal" SG_ 615 BCS_ABAactive 0;
BA_ "GatewayedSignals" SG_ 615 BCS_ABAactive 0;
BA_ "GenSigInactiveValue" SG_ 615 BCS_ABAactive 0;
BA_ "GenSigInvalidValue" SG_ 615 BCS_ABAactive 0;
BA_ "GenSigSendType" SG_ 615 BCS_ABAactive 1;
BA_ "GenSigStartValue" SG_ 615 BCS_ABAactive 0;
BA_ "GenSigTimeoutValue" SG_ 615 BCS_ABAactive 0;
BA_ "Remark" SG_ 615 BCS_ABAactive "";
BA_ "EventCommandSignal" SG_ 615 BCS_ABAavailable 0;
BA_ "GatewayedSignals" SG_ 615 BCS_ABAavailable 0;
BA_ "GenSigInactiveValue" SG_ 615 BCS_ABAavailable 0;
BA_ "GenSigInvalidValue" SG_ 615 BCS_ABAavailable 0;
BA_ "GenSigSendType" SG_ 615 BCS_ABAavailable 1;
BA_ "GenSigStartValue" SG_ 615 BCS_ABAavailable 0;
BA_ "GenSigTimeoutValue" SG_ 615 BCS_ABAavailable 0;
BA_ "Remark" SG_ 615 BCS_ABAavailable "";
BA_ "EventCommandSignal" SG_ 615 BCS_ABPActive 0;
BA_ "GatewayedSignals" SG_ 615 BCS_ABPActive 0;
BA_ "GenSigInactiveValue" SG_ 615 BCS_ABPActive 0;
BA_ "GenSigInvalidValue" SG_ 615 BCS_ABPActive 0;
BA_ "GenSigSendType" SG_ 615 BCS_ABPActive 1;
BA_ "GenSigStartValue" SG_ 615 BCS_ABPActive 0;
BA_ "GenSigTimeoutValue" SG_ 615 BCS_ABPActive 0;
BA_ "Remark" SG_ 615 BCS_ABPActive "";
BA_ "EventCommandSignal" SG_ 615 BCS_ABPAvailable 0;
BA_ "GatewayedSignals" SG_ 615 BCS_ABPAvailable 0;
BA_ "GenSigInactiveValue" SG_ 615 BCS_ABPAvailable 0;
BA_ "GenSigInvalidValue" SG_ 615 BCS_ABPAvailable 0;
BA_ "GenSigSendType" SG_ 615 BCS_ABPAvailable 1;
BA_ "GenSigStartValue" SG_ 615 BCS_ABPAvailable 0;
BA_ "GenSigTimeoutValue" SG_ 615 BCS_ABPAvailable 0;
BA_ "Remark" SG_ 615 BCS_ABPAvailable "";
BA_ "EventCommandSignal" SG_ 615 BCS_AEBActive 0;
BA_ "GatewayedSignals" SG_ 615 BCS_AEBActive 0;
BA_ "GenSigInactiveValue" SG_ 615 BCS_AEBActive 0;
BA_ "GenSigInvalidValue" SG_ 615 BCS_AEBActive 0;
BA_ "GenSigSendType" SG_ 615 BCS_AEBActive 1;
BA_ "GenSigStartValue" SG_ 615 BCS_AEBActive 0;
BA_ "GenSigTimeoutValue" SG_ 615 BCS_AEBActive 0;
BA_ "Remark" SG_ 615 BCS_AEBActive "";
BA_ "EventCommandSignal" SG_ 615 BCS_AEBAvailable 0;
BA_ "GatewayedSignals" SG_ 615 BCS_AEBAvailable 0;
BA_ "GenSigInactiveValue" SG_ 615 BCS_AEBAvailable 0;
BA_ "GenSigInvalidValue" SG_ 615 BCS_AEBAvailable 0;
BA_ "GenSigSendType" SG_ 615 BCS_AEBAvailable 1;
BA_ "GenSigStartValue" SG_ 615 BCS_AEBAvailable 0;
BA_ "GenSigTimeoutValue" SG_ 615 BCS_AEBAvailable 0;
BA_ "Remark" SG_ 615 BCS_AEBAvailable "";
BA_ "EventCommandSignal" SG_ 615 BCS_AWBActive 0;
BA_ "GatewayedSignals" SG_ 615 BCS_AWBActive 0;
BA_ "GenSigInactiveValue" SG_ 615 BCS_AWBActive 0;
BA_ "GenSigInvalidValue" SG_ 615 BCS_AWBActive 0;
BA_ "GenSigSendType" SG_ 615 BCS_AWBActive 1;
BA_ "GenSigStartValue" SG_ 615 BCS_AWBActive 0;
BA_ "GenSigTimeoutValue" SG_ 615 BCS_AWBActive 0;
BA_ "Remark" SG_ 615 BCS_AWBActive "";
BA_ "EventCommandSignal" SG_ 615 BCS_AWBAvailable 0;
BA_ "GatewayedSignals" SG_ 615 BCS_AWBAvailable 0;
BA_ "GenSigInactiveValue" SG_ 615 BCS_AWBAvailable 0;
BA_ "GenSigInvalidValue" SG_ 615 BCS_AWBAvailable 0;
BA_ "GenSigSendType" SG_ 615 BCS_AWBAvailable 1;
BA_ "GenSigStartValue" SG_ 615 BCS_AWBAvailable 0;
BA_ "GenSigTimeoutValue" SG_ 615 BCS_AWBAvailable 0;
BA_ "Remark" SG_ 615 BCS_AWBAvailable "";
BA_ "EventCommandSignal" SG_ 615 BCS_VehicleStandStillSt 0;
BA_ "GatewayedSignals" SG_ 615 BCS_VehicleStandStillSt 0;
BA_ "GenSigInactiveValue" SG_ 615 BCS_VehicleStandStillSt 0;
BA_ "GenSigInvalidValue" SG_ 615 BCS_VehicleStandStillSt 0;
BA_ "GenSigSendType" SG_ 615 BCS_VehicleStandStillSt 1;
BA_ "GenSigStartValue" SG_ 615 BCS_VehicleStandStillSt 0;
BA_ "GenSigTimeoutValue" SG_ 615 BCS_VehicleStandStillSt 0;
BA_ "Remark" SG_ 615 BCS_VehicleStandStillSt "";
BA_ "EventCommandSignal" SG_ 615 BCS_AEBBAActive 0;
BA_ "GatewayedSignals" SG_ 615 BCS_AEBBAActive 0;
BA_ "GenSigInactiveValue" SG_ 615 BCS_AEBBAActive 0;
BA_ "GenSigInvalidValue" SG_ 615 BCS_AEBBAActive 0;
BA_ "GenSigSendType" SG_ 615 BCS_AEBBAActive 1;
BA_ "GenSigStartValue" SG_ 615 BCS_AEBBAActive 0;
BA_ "GenSigTimeoutValue" SG_ 615 BCS_AEBBAActive 0;
BA_ "Remark" SG_ 615 BCS_AEBBAActive "";
BA_ "EventCommandSignal" SG_ 615 IPB_InputRodStroke 0;
BA_ "GatewayedSignals" SG_ 615 IPB_InputRodStroke 0;
BA_ "GenSigInactiveValue" SG_ 615 IPB_InputRodStroke 0;
BA_ "GenSigInvalidValue" SG_ 615 IPB_InputRodStroke 0;
BA_ "GenSigSendType" SG_ 615 IPB_InputRodStroke 1;
BA_ "GenSigStartValue" SG_ 615 IPB_InputRodStroke 100;
BA_ "GenSigTimeoutValue" SG_ 615 IPB_InputRodStroke 0;
BA_ "Remark" SG_ 615 IPB_InputRodStroke "";
BA_ "EventCommandSignal" SG_ 615 IPB_InputRodStrokeSt 0;
BA_ "GatewayedSignals" SG_ 615 IPB_InputRodStrokeSt 0;
BA_ "GenSigInactiveValue" SG_ 615 IPB_InputRodStrokeSt 0;
BA_ "GenSigInvalidValue" SG_ 615 IPB_InputRodStrokeSt 0;
BA_ "GenSigSendType" SG_ 615 IPB_InputRodStrokeSt 1;
BA_ "GenSigStartValue" SG_ 615 IPB_InputRodStrokeSt 0;
BA_ "GenSigTimeoutValue" SG_ 615 IPB_InputRodStrokeSt 0;
BA_ "Remark" SG_ 615 IPB_InputRodStrokeSt "";
BA_ "EventCommandSignal" SG_ 615 BCS_RAEBActive 0;
BA_ "GatewayedSignals" SG_ 615 BCS_RAEBActive 0;
BA_ "GenSigInactiveValue" SG_ 615 BCS_RAEBActive 0;
BA_ "GenSigInvalidValue" SG_ 615 BCS_RAEBActive 0;
BA_ "GenSigSendType" SG_ 615 BCS_RAEBActive 1;
BA_ "GenSigStartValue" SG_ 615 BCS_RAEBActive 0;
BA_ "GenSigTimeoutValue" SG_ 615 BCS_RAEBActive 0;
BA_ "Remark" SG_ 615 BCS_RAEBActive "";
BA_ "EventCommandSignal" SG_ 615 BCS_RAEBAvailable 0;
BA_ "GatewayedSignals" SG_ 615 BCS_RAEBAvailable 0;
BA_ "GenSigInactiveValue" SG_ 615 BCS_RAEBAvailable 0;
BA_ "GenSigInvalidValue" SG_ 615 BCS_RAEBAvailable 0;
BA_ "GenSigSendType" SG_ 615 BCS_RAEBAvailable 1;
BA_ "GenSigStartValue" SG_ 615 BCS_RAEBAvailable 0;
BA_ "GenSigTimeoutValue" SG_ 615 BCS_RAEBAvailable 0;
BA_ "Remark" SG_ 615 BCS_RAEBAvailable "";
BA_ "EventCommandSignal" SG_ 615 IPB_PlungerPressureSt 0;
BA_ "GatewayedSignals" SG_ 615 IPB_PlungerPressureSt 0;
BA_ "GenSigInactiveValue" SG_ 615 IPB_PlungerPressureSt 0;
BA_ "GenSigInvalidValue" SG_ 615 IPB_PlungerPressureSt 0;
BA_ "GenSigSendType" SG_ 615 IPB_PlungerPressureSt 1;
BA_ "GenSigStartValue" SG_ 615 IPB_PlungerPressureSt 0;
BA_ "GenSigTimeoutValue" SG_ 615 IPB_PlungerPressureSt 0;
BA_ "Remark" SG_ 615 IPB_PlungerPressureSt "";
BA_ "EventCommandSignal" SG_ 615 IPB_PlungerPressure 0;
BA_ "GatewayedSignals" SG_ 615 IPB_PlungerPressure 0;
BA_ "GenSigInactiveValue" SG_ 615 IPB_PlungerPressure 0;
BA_ "GenSigInvalidValue" SG_ 615 IPB_PlungerPressure 0;
BA_ "GenSigSendType" SG_ 615 IPB_PlungerPressure 1;
BA_ "GenSigStartValue" SG_ 615 IPB_PlungerPressure 17;
BA_ "GenSigTimeoutValue" SG_ 615 IPB_PlungerPressure 0;
BA_ "Remark" SG_ 615 IPB_PlungerPressure "";
BA_ "EventCommandSignal" SG_ 615 BCS_2ParkDrvBrkOverrideFlg 0;
BA_ "GatewayedSignals" SG_ 615 BCS_2ParkDrvBrkOverrideFlg 0;
BA_ "GenSigInactiveValue" SG_ 615 BCS_2ParkDrvBrkOverrideFlg 0;
BA_ "GenSigInvalidValue" SG_ 615 BCS_2ParkDrvBrkOverrideFlg 0;
BA_ "GenSigSendType" SG_ 615 BCS_2ParkDrvBrkOverrideFlg 1;
BA_ "GenSigStartValue" SG_ 615 BCS_2ParkDrvBrkOverrideFlg 0;
BA_ "GenSigTimeoutValue" SG_ 615 BCS_2ParkDrvBrkOverrideFlg 0;
BA_ "Remark" SG_ 615 BCS_2ParkDrvBrkOverrideFlg "";
BA_ "EventCommandSignal" SG_ 615 BCS_BrkTqCtrlAvlDrivingRdn 0;
BA_ "GatewayedSignals" SG_ 615 BCS_BrkTqCtrlAvlDrivingRdn 0;
BA_ "GenSigInactiveValue" SG_ 615 BCS_BrkTqCtrlAvlDrivingRdn 0;
BA_ "GenSigInvalidValue" SG_ 615 BCS_BrkTqCtrlAvlDrivingRdn 0;
BA_ "GenSigSendType" SG_ 615 BCS_BrkTqCtrlAvlDrivingRdn 1;
BA_ "GenSigStartValue" SG_ 615 BCS_BrkTqCtrlAvlDrivingRdn 0;
BA_ "GenSigTimeoutValue" SG_ 615 BCS_BrkTqCtrlAvlDrivingRdn 0;
BA_ "Remark" SG_ 615 BCS_BrkTqCtrlAvlDrivingRdn "";
BA_ "EventCommandSignal" SG_ 615 BCS_BrkTqCtrlActvRdn 0;
BA_ "GatewayedSignals" SG_ 615 BCS_BrkTqCtrlActvRdn 0;
BA_ "GenSigInactiveValue" SG_ 615 BCS_BrkTqCtrlActvRdn 0;
BA_ "GenSigInvalidValue" SG_ 615 BCS_BrkTqCtrlActvRdn 0;
BA_ "GenSigSendType" SG_ 615 BCS_BrkTqCtrlActvRdn 1;
BA_ "GenSigStartValue" SG_ 615 BCS_BrkTqCtrlActvRdn 0;
BA_ "GenSigTimeoutValue" SG_ 615 BCS_BrkTqCtrlActvRdn 0;
BA_ "Remark" SG_ 615 BCS_BrkTqCtrlActvRdn "";
BA_ "EventCommandSignal" SG_ 615 BCS_L3CommunicationVld 0;
BA_ "GatewayedSignals" SG_ 615 BCS_L3CommunicationVld 0;
BA_ "GenSigInactiveValue" SG_ 615 BCS_L3CommunicationVld 0;
BA_ "GenSigInvalidValue" SG_ 615 BCS_L3CommunicationVld 0;
BA_ "GenSigSendType" SG_ 615 BCS_L3CommunicationVld 1;
BA_ "GenSigStartValue" SG_ 615 BCS_L3CommunicationVld 0;
BA_ "GenSigTimeoutValue" SG_ 615 BCS_L3CommunicationVld 0;
BA_ "Remark" SG_ 615 BCS_L3CommunicationVld "";
BA_ "EventCommandSignal" SG_ 615 BCS_LFIActiveSt 0;
BA_ "GatewayedSignals" SG_ 615 BCS_LFIActiveSt 0;
BA_ "GenSigInactiveValue" SG_ 615 BCS_LFIActiveSt 0;
BA_ "GenSigInvalidValue" SG_ 615 BCS_LFIActiveSt 0;
BA_ "GenSigSendType" SG_ 615 BCS_LFIActiveSt 1;
BA_ "GenSigStartValue" SG_ 615 BCS_LFIActiveSt 0;
BA_ "GenSigTimeoutValue" SG_ 615 BCS_LFIActiveSt 0;
BA_ "Remark" SG_ 615 BCS_LFIActiveSt "";
BA_ "EventCommandSignal" SG_ 352 BCS_2_CRC 0;
BA_ "GatewayedSignals" SG_ 352 BCS_2_CRC 0;
BA_ "GenSigInactiveValue" SG_ 352 BCS_2_CRC 0;
BA_ "GenSigInvalidValue" SG_ 352 BCS_2_CRC 0;
BA_ "GenSigSendType" SG_ 352 BCS_2_CRC 1;
BA_ "GenSigStartValue" SG_ 352 BCS_2_CRC 0;
BA_ "GenSigTimeoutValue" SG_ 352 BCS_2_CRC 0;
BA_ "Remark" SG_ 352 BCS_2_CRC "";
BA_ "EventCommandSignal" SG_ 352 BCS_2_Counter 0;
BA_ "GatewayedSignals" SG_ 352 BCS_2_Counter 0;
BA_ "GenSigInactiveValue" SG_ 352 BCS_2_Counter 0;
BA_ "GenSigInvalidValue" SG_ 352 BCS_2_Counter 0;
BA_ "GenSigSendType" SG_ 352 BCS_2_Counter 1;
BA_ "GenSigStartValue" SG_ 352 BCS_2_Counter 0;
BA_ "GenSigTimeoutValue" SG_ 352 BCS_2_Counter 0;
BA_ "Remark" SG_ 352 BCS_2_Counter "";
BA_ "EventCommandSignal" SG_ 352 BCS_VehSpd 0;
BA_ "GatewayedSignals" SG_ 352 BCS_VehSpd 0;
BA_ "GenSigInactiveValue" SG_ 352 BCS_VehSpd 0;
BA_ "GenSigInvalidValue" SG_ 352 BCS_VehSpd 0;
BA_ "GenSigSendType" SG_ 352 BCS_VehSpd 1;
BA_ "GenSigStartValue" SG_ 352 BCS_VehSpd 0;
BA_ "GenSigTimeoutValue" SG_ 352 BCS_VehSpd 0;
BA_ "Remark" SG_ 352 BCS_VehSpd "";
BA_ "EventCommandSignal" SG_ 352 BCS_VehSpdVD 0;
BA_ "GatewayedSignals" SG_ 352 BCS_VehSpdVD 0;
BA_ "GenSigInactiveValue" SG_ 352 BCS_VehSpdVD 0;
BA_ "GenSigInvalidValue" SG_ 352 BCS_VehSpdVD 0;
BA_ "GenSigSendType" SG_ 352 BCS_VehSpdVD 1;
BA_ "GenSigStartValue" SG_ 352 BCS_VehSpdVD 0;
BA_ "GenSigTimeoutValue" SG_ 352 BCS_VehSpdVD 0;
BA_ "Remark" SG_ 352 BCS_VehSpdVD "";
BA_ "EventCommandSignal" SG_ 352 BCS_EBDActiveSt 0;
BA_ "GatewayedSignals" SG_ 352 BCS_EBDActiveSt 0;
BA_ "GenSigInactiveValue" SG_ 352 BCS_EBDActiveSt 0;
BA_ "GenSigInvalidValue" SG_ 352 BCS_EBDActiveSt 0;
BA_ "GenSigSendType" SG_ 352 BCS_EBDActiveSt 1;
BA_ "GenSigStartValue" SG_ 352 BCS_EBDActiveSt 0;
BA_ "GenSigTimeoutValue" SG_ 352 BCS_EBDActiveSt 0;
BA_ "Remark" SG_ 352 BCS_EBDActiveSt "";
BA_ "EventCommandSignal" SG_ 352 BCS_EBDFaultSt 0;
BA_ "GatewayedSignals" SG_ 352 BCS_EBDFaultSt 0;
BA_ "GenSigInactiveValue" SG_ 352 BCS_EBDFaultSt 0;
BA_ "GenSigInvalidValue" SG_ 352 BCS_EBDFaultSt 0;
BA_ "GenSigSendType" SG_ 352 BCS_EBDFaultSt 1;
BA_ "GenSigStartValue" SG_ 352 BCS_EBDFaultSt 1;
BA_ "GenSigTimeoutValue" SG_ 352 BCS_EBDFaultSt 1;
BA_ "Remark" SG_ 352 BCS_EBDFaultSt "";
BA_ "EventCommandSignal" SG_ 352 BCS_ABSActiveSt 0;
BA_ "GatewayedSignals" SG_ 352 BCS_ABSActiveSt 0;
BA_ "GenSigInactiveValue" SG_ 352 BCS_ABSActiveSt 0;
BA_ "GenSigInvalidValue" SG_ 352 BCS_ABSActiveSt 0;
BA_ "GenSigSendType" SG_ 352 BCS_ABSActiveSt 1;
BA_ "GenSigStartValue" SG_ 352 BCS_ABSActiveSt 0;
BA_ "GenSigTimeoutValue" SG_ 352 BCS_ABSActiveSt 0;
BA_ "Remark" SG_ 352 BCS_ABSActiveSt "";
BA_ "EventCommandSignal" SG_ 352 BCS_ABSFaultSt 0;
BA_ "GatewayedSignals" SG_ 352 BCS_ABSFaultSt 0;
BA_ "GenSigInactiveValue" SG_ 352 BCS_ABSFaultSt 0;
BA_ "GenSigInvalidValue" SG_ 352 BCS_ABSFaultSt 0;
BA_ "GenSigSendType" SG_ 352 BCS_ABSFaultSt 1;
BA_ "GenSigStartValue" SG_ 352 BCS_ABSFaultSt 1;
BA_ "GenSigTimeoutValue" SG_ 352 BCS_ABSFaultSt 1;
BA_ "Remark" SG_ 352 BCS_ABSFaultSt "";
BA_ "EventCommandSignal" SG_ 352 BCS_TCSActiveSt 0;
BA_ "GatewayedSignals" SG_ 352 BCS_TCSActiveSt 0;
BA_ "GenSigInactiveValue" SG_ 352 BCS_TCSActiveSt 0;
BA_ "GenSigInvalidValue" SG_ 352 BCS_TCSActiveSt 0;
BA_ "GenSigSendType" SG_ 352 BCS_TCSActiveSt 1;
BA_ "GenSigStartValue" SG_ 352 BCS_TCSActiveSt 0;
BA_ "GenSigTimeoutValue" SG_ 352 BCS_TCSActiveSt 0;
BA_ "Remark" SG_ 352 BCS_TCSActiveSt "";
BA_ "EventCommandSignal" SG_ 352 BCS_TCSFaultSt 0;
BA_ "GatewayedSignals" SG_ 352 BCS_TCSFaultSt 0;
BA_ "GenSigInactiveValue" SG_ 352 BCS_TCSFaultSt 0;
BA_ "GenSigInvalidValue" SG_ 352 BCS_TCSFaultSt 0;
BA_ "GenSigSendType" SG_ 352 BCS_TCSFaultSt 1;
BA_ "GenSigStartValue" SG_ 352 BCS_TCSFaultSt 1;
BA_ "GenSigTimeoutValue" SG_ 352 BCS_TCSFaultSt 1;
BA_ "Remark" SG_ 352 BCS_TCSFaultSt "";
BA_ "EventCommandSignal" SG_ 352 BCS_VDCActiveSt 0;
BA_ "GatewayedSignals" SG_ 352 BCS_VDCActiveSt 0;
BA_ "GenSigInactiveValue" SG_ 352 BCS_VDCActiveSt 0;
BA_ "GenSigInvalidValue" SG_ 352 BCS_VDCActiveSt 0;
BA_ "GenSigSendType" SG_ 352 BCS_VDCActiveSt 1;
BA_ "GenSigStartValue" SG_ 352 BCS_VDCActiveSt 0;
BA_ "GenSigTimeoutValue" SG_ 352 BCS_VDCActiveSt 0;
BA_ "Remark" SG_ 352 BCS_VDCActiveSt "";
BA_ "EventCommandSignal" SG_ 352 BCS_VDCFaultSt 0;
BA_ "GatewayedSignals" SG_ 352 BCS_VDCFaultSt 0;
BA_ "GenSigInactiveValue" SG_ 352 BCS_VDCFaultSt 0;
BA_ "GenSigInvalidValue" SG_ 352 BCS_VDCFaultSt 0;
BA_ "GenSigSendType" SG_ 352 BCS_VDCFaultSt 1;
BA_ "GenSigStartValue" SG_ 352 BCS_VDCFaultSt 1;
BA_ "GenSigTimeoutValue" SG_ 352 BCS_VDCFaultSt 1;
BA_ "Remark" SG_ 352 BCS_VDCFaultSt "";
BA_ "EventCommandSignal" SG_ 352 BCS_PreAndRealVDCActiveSt 0;
BA_ "GatewayedSignals" SG_ 352 BCS_PreAndRealVDCActiveSt 0;
BA_ "GenSigInactiveValue" SG_ 352 BCS_PreAndRealVDCActiveSt 0;
BA_ "GenSigInvalidValue" SG_ 352 BCS_PreAndRealVDCActiveSt 0;
BA_ "GenSigSendType" SG_ 352 BCS_PreAndRealVDCActiveSt 1;
BA_ "GenSigStartValue" SG_ 352 BCS_PreAndRealVDCActiveSt 0;
BA_ "GenSigTimeoutValue" SG_ 352 BCS_PreAndRealVDCActiveSt 0;
BA_ "Remark" SG_ 352 BCS_PreAndRealVDCActiveSt "";
BA_ "EventCommandSignal" SG_ 352 BCS_RegenModulationAvailable 0;
BA_ "GatewayedSignals" SG_ 352 BCS_RegenModulationAvailable 0;
BA_ "GenSigInactiveValue" SG_ 352 BCS_RegenModulationAvailable 0;
BA_ "GenSigInvalidValue" SG_ 352 BCS_RegenModulationAvailable 0;
BA_ "GenSigSendType" SG_ 352 BCS_RegenModulationAvailable 1;
BA_ "GenSigStartValue" SG_ 352 BCS_RegenModulationAvailable 0;
BA_ "GenSigTimeoutValue" SG_ 352 BCS_RegenModulationAvailable 0;
BA_ "Remark" SG_ 352 BCS_RegenModulationAvailable "";
BA_ "EventCommandSignal" SG_ 352 BCS_RegenModuleActive 0;
BA_ "GatewayedSignals" SG_ 352 BCS_RegenModuleActive 0;
BA_ "GenSigInactiveValue" SG_ 352 BCS_RegenModuleActive 0;
BA_ "GenSigInvalidValue" SG_ 352 BCS_RegenModuleActive 0;
BA_ "GenSigSendType" SG_ 352 BCS_RegenModuleActive 1;
BA_ "GenSigStartValue" SG_ 352 BCS_RegenModuleActive 0;
BA_ "GenSigTimeoutValue" SG_ 352 BCS_RegenModuleActive 0;
BA_ "Remark" SG_ 352 BCS_RegenModuleActive "";
BA_ "EventCommandSignal" SG_ 352 BCS_RealTCSActiveSt 0;
BA_ "GatewayedSignals" SG_ 352 BCS_RealTCSActiveSt 0;
BA_ "GenSigInactiveValue" SG_ 352 BCS_RealTCSActiveSt 0;
BA_ "GenSigInvalidValue" SG_ 352 BCS_RealTCSActiveSt 0;
BA_ "GenSigSendType" SG_ 352 BCS_RealTCSActiveSt 1;
BA_ "GenSigStartValue" SG_ 352 BCS_RealTCSActiveSt 0;
BA_ "GenSigTimeoutValue" SG_ 352 BCS_RealTCSActiveSt 0;
BA_ "Remark" SG_ 352 BCS_RealTCSActiveSt "";
BA_ "EventCommandSignal" SG_ 352 BCS_TargetRecpTorqRq 0;
BA_ "GatewayedSignals" SG_ 352 BCS_TargetRecpTorqRq 0;
BA_ "GenSigInactiveValue" SG_ 352 BCS_TargetRecpTorqRq 0;
BA_ "GenSigInvalidValue" SG_ 352 BCS_TargetRecpTorqRq 0;
BA_ "GenSigSendType" SG_ 352 BCS_TargetRecpTorqRq 1;
BA_ "GenSigStartValue" SG_ 352 BCS_TargetRecpTorqRq 6000;
BA_ "GenSigTimeoutValue" SG_ 352 BCS_TargetRecpTorqRq 0;
BA_ "Remark" SG_ 352 BCS_TargetRecpTorqRq "";
BA_ "EventCommandSignal" SG_ 352 BCS_TargetRecpTorqRqSt 0;
BA_ "GatewayedSignals" SG_ 352 BCS_TargetRecpTorqRqSt 0;
BA_ "GenSigInactiveValue" SG_ 352 BCS_TargetRecpTorqRqSt 0;
BA_ "GenSigInvalidValue" SG_ 352 BCS_TargetRecpTorqRqSt 0;
BA_ "GenSigSendType" SG_ 352 BCS_TargetRecpTorqRqSt 1;
BA_ "GenSigStartValue" SG_ 352 BCS_TargetRecpTorqRqSt 0;
BA_ "GenSigTimeoutValue" SG_ 352 BCS_TargetRecpTorqRqSt 0;
BA_ "Remark" SG_ 352 BCS_TargetRecpTorqRqSt "";
BA_ "EventCommandSignal" SG_ 352 BCS_CrbsActive 0;
BA_ "GatewayedSignals" SG_ 352 BCS_CrbsActive 0;
BA_ "GenSigInactiveValue" SG_ 352 BCS_CrbsActive 0;
BA_ "GenSigInvalidValue" SG_ 352 BCS_CrbsActive 0;
BA_ "GenSigSendType" SG_ 352 BCS_CrbsActive 1;
BA_ "GenSigStartValue" SG_ 352 BCS_CrbsActive 0;
BA_ "GenSigTimeoutValue" SG_ 352 BCS_CrbsActive 0;
BA_ "Remark" SG_ 352 BCS_CrbsActive "";
BA_ "EventCommandSignal" SG_ 352 IPB_BrakePedalStsVld 0;
BA_ "GatewayedSignals" SG_ 352 IPB_BrakePedalStsVld 0;
BA_ "GenSigInactiveValue" SG_ 352 IPB_BrakePedalStsVld 0;
BA_ "GenSigInvalidValue" SG_ 352 IPB_BrakePedalStsVld 0;
BA_ "GenSigSendType" SG_ 352 IPB_BrakePedalStsVld 1;
BA_ "GenSigStartValue" SG_ 352 IPB_BrakePedalStsVld 0;
BA_ "GenSigTimeoutValue" SG_ 352 IPB_BrakePedalStsVld 0;
BA_ "Remark" SG_ 352 IPB_BrakePedalStsVld "";
BA_ "EventCommandSignal" SG_ 352 IPB_BrakePedalSt 0;
BA_ "GatewayedSignals" SG_ 352 IPB_BrakePedalSt 0;
BA_ "GenSigInactiveValue" SG_ 352 IPB_BrakePedalSt 0;
BA_ "GenSigInvalidValue" SG_ 352 IPB_BrakePedalSt 0;
BA_ "GenSigSendType" SG_ 352 IPB_BrakePedalSt 1;
BA_ "GenSigStartValue" SG_ 352 IPB_BrakePedalSt 0;
BA_ "GenSigTimeoutValue" SG_ 352 IPB_BrakePedalSt 0;
BA_ "Remark" SG_ 352 IPB_BrakePedalSt "";
BA_ "EventCommandSignal" SG_ 352 BCS_EngTorqDecFastRANm 0;
BA_ "GatewayedSignals" SG_ 352 BCS_EngTorqDecFastRANm 0;
BA_ "GenSigInactiveValue" SG_ 352 BCS_EngTorqDecFastRANm 0;
BA_ "GenSigInvalidValue" SG_ 352 BCS_EngTorqDecFastRANm 0;
BA_ "GenSigSendType" SG_ 352 BCS_EngTorqDecFastRANm 1;
BA_ "GenSigStartValue" SG_ 352 BCS_EngTorqDecFastRANm 60000;
BA_ "GenSigTimeoutValue" SG_ 352 BCS_EngTorqDecFastRANm 0;
BA_ "Remark" SG_ 352 BCS_EngTorqDecFastRANm "";
BA_ "EventCommandSignal" SG_ 352 BCS_EngTorqIncRANm 0;
BA_ "GatewayedSignals" SG_ 352 BCS_EngTorqIncRANm 0;
BA_ "GenSigInactiveValue" SG_ 352 BCS_EngTorqIncRANm 0;
BA_ "GenSigInvalidValue" SG_ 352 BCS_EngTorqIncRANm 0;
BA_ "GenSigSendType" SG_ 352 BCS_EngTorqIncRANm 1;
BA_ "GenSigStartValue" SG_ 352 BCS_EngTorqIncRANm 0;
BA_ "GenSigTimeoutValue" SG_ 352 BCS_EngTorqIncRANm 0;
BA_ "Remark" SG_ 352 BCS_EngTorqIncRANm "";
BA_ "EventCommandSignal" SG_ 352 BCS_ESP2Park_DrvBrkOverrideFlg 0;
BA_ "GatewayedSignals" SG_ 352 BCS_ESP2Park_DrvBrkOverrideFlg 0;
BA_ "GenSigInactiveValue" SG_ 352 BCS_ESP2Park_DrvBrkOverrideFlg 0;
BA_ "GenSigInvalidValue" SG_ 352 BCS_ESP2Park_DrvBrkOverrideFlg 0;
BA_ "GenSigSendType" SG_ 352 BCS_ESP2Park_DrvBrkOverrideFlg 1;
BA_ "GenSigStartValue" SG_ 352 BCS_ESP2Park_DrvBrkOverrideFlg 0;
BA_ "GenSigTimeoutValue" SG_ 352 BCS_ESP2Park_DrvBrkOverrideFlg 0;
BA_ "Remark" SG_ 352 BCS_ESP2Park_DrvBrkOverrideFlg "";
BA_ "EventCommandSignal" SG_ 352 BCS_TargetRecpTorqRqFA 0;
BA_ "GatewayedSignals" SG_ 352 BCS_TargetRecpTorqRqFA 0;
BA_ "GenSigInactiveValue" SG_ 352 BCS_TargetRecpTorqRqFA 0;
BA_ "GenSigInvalidValue" SG_ 352 BCS_TargetRecpTorqRqFA 0;
BA_ "GenSigSendType" SG_ 352 BCS_TargetRecpTorqRqFA 1;
BA_ "GenSigStartValue" SG_ 352 BCS_TargetRecpTorqRqFA 6000;
BA_ "GenSigTimeoutValue" SG_ 352 BCS_TargetRecpTorqRqFA 0;
BA_ "Remark" SG_ 352 BCS_TargetRecpTorqRqFA "";
BA_ "EventCommandSignal" SG_ 352 BCS_TargetRecpTorqRqFASt 0;
BA_ "GatewayedSignals" SG_ 352 BCS_TargetRecpTorqRqFASt 0;
BA_ "GenSigInactiveValue" SG_ 352 BCS_TargetRecpTorqRqFASt 0;
BA_ "GenSigInvalidValue" SG_ 352 BCS_TargetRecpTorqRqFASt 0;
BA_ "GenSigSendType" SG_ 352 BCS_TargetRecpTorqRqFASt 1;
BA_ "GenSigStartValue" SG_ 352 BCS_TargetRecpTorqRqFASt 0;
BA_ "GenSigTimeoutValue" SG_ 352 BCS_TargetRecpTorqRqFASt 0;
BA_ "Remark" SG_ 352 BCS_TargetRecpTorqRqFASt "";
BA_ "EventCommandSignal" SG_ 352 BCS_TargetRecpTorqRqRA 0;
BA_ "GatewayedSignals" SG_ 352 BCS_TargetRecpTorqRqRA 0;
BA_ "GenSigInactiveValue" SG_ 352 BCS_TargetRecpTorqRqRA 0;
BA_ "GenSigInvalidValue" SG_ 352 BCS_TargetRecpTorqRqRA 0;
BA_ "GenSigSendType" SG_ 352 BCS_TargetRecpTorqRqRA 1;
BA_ "GenSigStartValue" SG_ 352 BCS_TargetRecpTorqRqRA 6000;
BA_ "GenSigTimeoutValue" SG_ 352 BCS_TargetRecpTorqRqRA 0;
BA_ "Remark" SG_ 352 BCS_TargetRecpTorqRqRA "";
BA_ "EventCommandSignal" SG_ 352 BCS_TargetRecpTorqRqRASt 0;
BA_ "GatewayedSignals" SG_ 352 BCS_TargetRecpTorqRqRASt 0;
BA_ "GenSigInactiveValue" SG_ 352 BCS_TargetRecpTorqRqRASt 0;
BA_ "GenSigInvalidValue" SG_ 352 BCS_TargetRecpTorqRqRASt 0;
BA_ "GenSigSendType" SG_ 352 BCS_TargetRecpTorqRqRASt 1;
BA_ "GenSigStartValue" SG_ 352 BCS_TargetRecpTorqRqRASt 0;
BA_ "GenSigTimeoutValue" SG_ 352 BCS_TargetRecpTorqRqRASt 0;
BA_ "Remark" SG_ 352 BCS_TargetRecpTorqRqRASt "";
BA_ "EventCommandSignal" SG_ 352 BCS_EngTorqDecActiveStRA 0;
BA_ "GatewayedSignals" SG_ 352 BCS_EngTorqDecActiveStRA 0;
BA_ "GenSigInactiveValue" SG_ 352 BCS_EngTorqDecActiveStRA 0;
BA_ "GenSigInvalidValue" SG_ 352 BCS_EngTorqDecActiveStRA 0;
BA_ "GenSigSendType" SG_ 352 BCS_EngTorqDecActiveStRA 1;
BA_ "GenSigStartValue" SG_ 352 BCS_EngTorqDecActiveStRA 0;
BA_ "GenSigTimeoutValue" SG_ 352 BCS_EngTorqDecActiveStRA 0;
BA_ "Remark" SG_ 352 BCS_EngTorqDecActiveStRA "";
BA_ "EventCommandSignal" SG_ 352 BCS_PrimBrkCDAAvailableSt 0;
BA_ "GatewayedSignals" SG_ 352 BCS_PrimBrkCDAAvailableSt 0;
BA_ "GenSigInactiveValue" SG_ 352 BCS_PrimBrkCDAAvailableSt 0;
BA_ "GenSigInvalidValue" SG_ 352 BCS_PrimBrkCDAAvailableSt 0;
BA_ "GenSigSendType" SG_ 352 BCS_PrimBrkCDAAvailableSt 1;
BA_ "GenSigStartValue" SG_ 352 BCS_PrimBrkCDAAvailableSt 0;
BA_ "GenSigTimeoutValue" SG_ 352 BCS_PrimBrkCDAAvailableSt 0;
BA_ "Remark" SG_ 352 BCS_PrimBrkCDAAvailableSt "";
BA_ "EventCommandSignal" SG_ 352 BCS_PrimBrkCommuniSt 0;
BA_ "GatewayedSignals" SG_ 352 BCS_PrimBrkCommuniSt 0;
BA_ "GenSigInactiveValue" SG_ 352 BCS_PrimBrkCommuniSt 0;
BA_ "GenSigInvalidValue" SG_ 352 BCS_PrimBrkCommuniSt 0;
BA_ "GenSigSendType" SG_ 352 BCS_PrimBrkCommuniSt 1;
BA_ "GenSigStartValue" SG_ 352 BCS_PrimBrkCommuniSt 0;
BA_ "GenSigTimeoutValue" SG_ 352 BCS_PrimBrkCommuniSt 0;
BA_ "Remark" SG_ 352 BCS_PrimBrkCommuniSt "";
BA_ "EventCommandSignal" SG_ 352 BCS_PrimBrkActiveSt 0;
BA_ "GatewayedSignals" SG_ 352 BCS_PrimBrkActiveSt 0;
BA_ "GenSigInactiveValue" SG_ 352 BCS_PrimBrkActiveSt 0;
BA_ "GenSigInvalidValue" SG_ 352 BCS_PrimBrkActiveSt 0;
BA_ "GenSigSendType" SG_ 352 BCS_PrimBrkActiveSt 1;
BA_ "GenSigStartValue" SG_ 352 BCS_PrimBrkActiveSt 0;
BA_ "GenSigTimeoutValue" SG_ 352 BCS_PrimBrkActiveSt 0;
BA_ "Remark" SG_ 352 BCS_PrimBrkActiveSt "";
BA_ "EventCommandSignal" SG_ 352 BCS_2ParkCddApActiveVehHld 0;
BA_ "GatewayedSignals" SG_ 352 BCS_2ParkCddApActiveVehHld 0;
BA_ "GenSigInactiveValue" SG_ 352 BCS_2ParkCddApActiveVehHld 0;
BA_ "GenSigInvalidValue" SG_ 352 BCS_2ParkCddApActiveVehHld 0;
BA_ "GenSigSendType" SG_ 352 BCS_2ParkCddApActiveVehHld 1;
BA_ "GenSigStartValue" SG_ 352 BCS_2ParkCddApActiveVehHld 0;
BA_ "GenSigTimeoutValue" SG_ 352 BCS_2ParkCddApActiveVehHld 0;
BA_ "Remark" SG_ 352 BCS_2ParkCddApActiveVehHld "";
BA_ "EventCommandSignal" SG_ 352 BCS_2ParkAPCStatus 0;
BA_ "GatewayedSignals" SG_ 352 BCS_2ParkAPCStatus 0;
BA_ "GenSigInactiveValue" SG_ 352 BCS_2ParkAPCStatus 0;
BA_ "GenSigInvalidValue" SG_ 352 BCS_2ParkAPCStatus 0;
BA_ "GenSigSendType" SG_ 352 BCS_2ParkAPCStatus 1;
BA_ "GenSigStartValue" SG_ 352 BCS_2ParkAPCStatus 0;
BA_ "GenSigTimeoutValue" SG_ 352 BCS_2ParkAPCStatus 0;
BA_ "Remark" SG_ 352 BCS_2ParkAPCStatus "";
BA_ "EventCommandSignal" SG_ 352 BCS_2ParkAPAavailability 0;
BA_ "GatewayedSignals" SG_ 352 BCS_2ParkAPAavailability 0;
BA_ "GenSigInactiveValue" SG_ 352 BCS_2ParkAPAavailability 0;
BA_ "GenSigInvalidValue" SG_ 352 BCS_2ParkAPAavailability 0;
BA_ "GenSigSendType" SG_ 352 BCS_2ParkAPAavailability 1;
BA_ "GenSigStartValue" SG_ 352 BCS_2ParkAPAavailability 0;
BA_ "GenSigTimeoutValue" SG_ 352 BCS_2ParkAPAavailability 0;
BA_ "Remark" SG_ 352 BCS_2ParkAPAavailability "";
BA_ "EventCommandSignal" SG_ 352 BCS_2ParkRPAAVPavailability 0;
BA_ "GatewayedSignals" SG_ 352 BCS_2ParkRPAAVPavailability 0;
BA_ "GenSigInactiveValue" SG_ 352 BCS_2ParkRPAAVPavailability 0;
BA_ "GenSigInvalidValue" SG_ 352 BCS_2ParkRPAAVPavailability 0;
BA_ "GenSigSendType" SG_ 352 BCS_2ParkRPAAVPavailability 1;
BA_ "GenSigStartValue" SG_ 352 BCS_2ParkRPAAVPavailability 0;
BA_ "GenSigTimeoutValue" SG_ 352 BCS_2ParkRPAAVPavailability 0;
BA_ "Remark" SG_ 352 BCS_2ParkRPAAVPavailability "";
BA_ "EventCommandSignal" SG_ 352 BCS_2ParkAPCFailureSts 0;
BA_ "GatewayedSignals" SG_ 352 BCS_2ParkAPCFailureSts 0;
BA_ "GenSigInactiveValue" SG_ 352 BCS_2ParkAPCFailureSts 0;
BA_ "GenSigInvalidValue" SG_ 352 BCS_2ParkAPCFailureSts 0;
BA_ "GenSigSendType" SG_ 352 BCS_2ParkAPCFailureSts 1;
BA_ "GenSigStartValue" SG_ 352 BCS_2ParkAPCFailureSts 0;
BA_ "GenSigTimeoutValue" SG_ 352 BCS_2ParkAPCFailureSts 0;
BA_ "Remark" SG_ 352 BCS_2ParkAPCFailureSts "";
BA_ "EventCommandSignal" SG_ 352 BCS_APCMain2BackupReq 0;
BA_ "GatewayedSignals" SG_ 352 BCS_APCMain2BackupReq 0;
BA_ "GenSigInactiveValue" SG_ 352 BCS_APCMain2BackupReq 0;
BA_ "GenSigInvalidValue" SG_ 352 BCS_APCMain2BackupReq 0;
BA_ "GenSigSendType" SG_ 352 BCS_APCMain2BackupReq 1;
BA_ "GenSigStartValue" SG_ 352 BCS_APCMain2BackupReq 0;
BA_ "GenSigTimeoutValue" SG_ 352 BCS_APCMain2BackupReq 0;
BA_ "Remark" SG_ 352 BCS_APCMain2BackupReq "";
BA_ "EventCommandSignal" SG_ 352 BCS_PrimBrkCtrlUsedChannel 0;
BA_ "GatewayedSignals" SG_ 352 BCS_PrimBrkCtrlUsedChannel 0;
BA_ "GenSigInactiveValue" SG_ 352 BCS_PrimBrkCtrlUsedChannel 0;
BA_ "GenSigInvalidValue" SG_ 352 BCS_PrimBrkCtrlUsedChannel 0;
BA_ "GenSigSendType" SG_ 352 BCS_PrimBrkCtrlUsedChannel 1;
BA_ "GenSigStartValue" SG_ 352 BCS_PrimBrkCtrlUsedChannel 0;
BA_ "GenSigTimeoutValue" SG_ 352 BCS_PrimBrkCtrlUsedChannel 0;
BA_ "Remark" SG_ 352 BCS_PrimBrkCtrlUsedChannel "";
BA_ "EventCommandSignal" SG_ 352 BCS_PrimBrkCDAActiveSt 0;
BA_ "GatewayedSignals" SG_ 352 BCS_PrimBrkCDAActiveSt 0;
BA_ "GenSigInactiveValue" SG_ 352 BCS_PrimBrkCDAActiveSt 0;
BA_ "GenSigInvalidValue" SG_ 352 BCS_PrimBrkCDAActiveSt 0;
BA_ "GenSigSendType" SG_ 352 BCS_PrimBrkCDAActiveSt 1;
BA_ "GenSigStartValue" SG_ 352 BCS_PrimBrkCDAActiveSt 0;
BA_ "GenSigTimeoutValue" SG_ 352 BCS_PrimBrkCDAActiveSt 0;
BA_ "Remark" SG_ 352 BCS_PrimBrkCDAActiveSt "";
BA_ "EventCommandSignal" SG_ 352 BCS_PrimBrkDecCtrlActiveSt 0;
BA_ "GatewayedSignals" SG_ 352 BCS_PrimBrkDecCtrlActiveSt 0;
BA_ "GenSigInactiveValue" SG_ 352 BCS_PrimBrkDecCtrlActiveSt 0;
BA_ "GenSigInvalidValue" SG_ 352 BCS_PrimBrkDecCtrlActiveSt 0;
BA_ "GenSigSendType" SG_ 352 BCS_PrimBrkDecCtrlActiveSt 1;
BA_ "GenSigStartValue" SG_ 352 BCS_PrimBrkDecCtrlActiveSt 0;
BA_ "GenSigTimeoutValue" SG_ 352 BCS_PrimBrkDecCtrlActiveSt 0;
BA_ "Remark" SG_ 352 BCS_PrimBrkDecCtrlActiveSt "";
BA_ "EventCommandSignal" SG_ 352 BCS_PrimBrkCDDAvailableSt 0;
BA_ "GatewayedSignals" SG_ 352 BCS_PrimBrkCDDAvailableSt 0;
BA_ "GenSigInactiveValue" SG_ 352 BCS_PrimBrkCDDAvailableSt 0;
BA_ "GenSigInvalidValue" SG_ 352 BCS_PrimBrkCDDAvailableSt 0;
BA_ "GenSigSendType" SG_ 352 BCS_PrimBrkCDDAvailableSt 1;
BA_ "GenSigStartValue" SG_ 352 BCS_PrimBrkCDDAvailableSt 0;
BA_ "GenSigTimeoutValue" SG_ 352 BCS_PrimBrkCDDAvailableSt 0;
BA_ "Remark" SG_ 352 BCS_PrimBrkCDDAvailableSt "";
BA_ "EventCommandSignal" SG_ 352 BCS_EngTorqDecActiveStFA 0;
BA_ "GatewayedSignals" SG_ 352 BCS_EngTorqDecActiveStFA 0;
BA_ "GenSigInactiveValue" SG_ 352 BCS_EngTorqDecActiveStFA 0;
BA_ "GenSigInvalidValue" SG_ 352 BCS_EngTorqDecActiveStFA 0;
BA_ "GenSigSendType" SG_ 352 BCS_EngTorqDecActiveStFA 1;
BA_ "GenSigStartValue" SG_ 352 BCS_EngTorqDecActiveStFA 0;
BA_ "GenSigTimeoutValue" SG_ 352 BCS_EngTorqDecActiveStFA 0;
BA_ "Remark" SG_ 352 BCS_EngTorqDecActiveStFA "";
BA_ "EventCommandSignal" SG_ 352 BCS_EngTorqIncActiveStFA 0;
BA_ "GatewayedSignals" SG_ 352 BCS_EngTorqIncActiveStFA 0;
BA_ "GenSigInactiveValue" SG_ 352 BCS_EngTorqIncActiveStFA 0;
BA_ "GenSigInvalidValue" SG_ 352 BCS_EngTorqIncActiveStFA 0;
BA_ "GenSigSendType" SG_ 352 BCS_EngTorqIncActiveStFA 1;
BA_ "GenSigStartValue" SG_ 352 BCS_EngTorqIncActiveStFA 0;
BA_ "GenSigTimeoutValue" SG_ 352 BCS_EngTorqIncActiveStFA 0;
BA_ "Remark" SG_ 352 BCS_EngTorqIncActiveStFA "";
BA_ "EventCommandSignal" SG_ 352 IBCS_ADCNetErrorFb 0;
BA_ "GatewayedSignals" SG_ 352 IBCS_ADCNetErrorFb 0;
BA_ "GenSigInactiveValue" SG_ 352 IBCS_ADCNetErrorFb 0;
BA_ "GenSigInvalidValue" SG_ 352 IBCS_ADCNetErrorFb 0;
BA_ "GenSigSendType" SG_ 352 IBCS_ADCNetErrorFb 1;
BA_ "GenSigStartValue" SG_ 352 IBCS_ADCNetErrorFb 0;
BA_ "GenSigTimeoutValue" SG_ 352 IBCS_ADCNetErrorFb 0;
BA_ "Remark" SG_ 352 IBCS_ADCNetErrorFb "";
BA_ "EventCommandSignal" SG_ 352 IBCS_NetModeResp 0;
BA_ "GatewayedSignals" SG_ 352 IBCS_NetModeResp 0;
BA_ "GenSigInactiveValue" SG_ 352 IBCS_NetModeResp 0;
BA_ "GenSigInvalidValue" SG_ 352 IBCS_NetModeResp 0;
BA_ "GenSigSendType" SG_ 352 IBCS_NetModeResp 1;
BA_ "GenSigStartValue" SG_ 352 IBCS_NetModeResp 0;
BA_ "GenSigTimeoutValue" SG_ 352 IBCS_NetModeResp 0;
BA_ "Remark" SG_ 352 IBCS_NetModeResp "";
BA_ "EventCommandSignal" SG_ 352 BCS_EngTorqDecFastFA 0;
BA_ "GatewayedSignals" SG_ 352 BCS_EngTorqDecFastFA 0;
BA_ "GenSigInactiveValue" SG_ 352 BCS_EngTorqDecFastFA 0;
BA_ "GenSigInvalidValue" SG_ 352 BCS_EngTorqDecFastFA 0;
BA_ "GenSigSendType" SG_ 352 BCS_EngTorqDecFastFA 1;
BA_ "GenSigStartValue" SG_ 352 BCS_EngTorqDecFastFA 60000;
BA_ "GenSigTimeoutValue" SG_ 352 BCS_EngTorqDecFastFA 0;
BA_ "Remark" SG_ 352 BCS_EngTorqDecFastFA "";
BA_ "EventCommandSignal" SG_ 352 BCS_EngTorqIncFA 0;
BA_ "GatewayedSignals" SG_ 352 BCS_EngTorqIncFA 0;
BA_ "GenSigInactiveValue" SG_ 352 BCS_EngTorqIncFA 0;
BA_ "GenSigInvalidValue" SG_ 352 BCS_EngTorqIncFA 0;
BA_ "GenSigSendType" SG_ 352 BCS_EngTorqIncFA 1;
BA_ "GenSigStartValue" SG_ 352 BCS_EngTorqIncFA 0;
BA_ "GenSigTimeoutValue" SG_ 352 BCS_EngTorqIncFA 0;
BA_ "Remark" SG_ 352 BCS_EngTorqIncFA "";
VAL_ 825 WW_FwpFaultSt 0 "Not fault" 1 "Fault"  ;
VAL_ 825 WW_RwpFaultSt 0 "Not fault" 1 "Fault"  ;
VAL_ 825 WW_FwshFaultSt 0 "Not fault" 1 "Fault"  ;
VAL_ 825 WW_RwshFaultSt 0 "Not fault" 1 "Fault"  ;
VAL_ 825 WW_FwpAutoModeSt 0 "False" 1 "True"  ;
VAL_ 825 WW_RainFallLevel 0 "No Rain" 1 "Level 1" 2 "Level 2" 3 "Level 3" 4 "Level 4" 5 "Level 5" 6 "Level 6" 7 "Level 7" 8 "Level 8" 9 "Level 9" 10 "Level 10" 11 "Level 11" 12 "Level 12" 13 "Level 13" 14 "Init value" 15 "Invalid value"  ;
VAL_ 825 RLS_LightOnReq 0 "Light Off" 1 "Light On"  ;
VAL_ 825 RLS_LampOnReqValid 0 "Valid value" 1 "Invalid value"  ;
VAL_ 825 RLS_WiperSpd 0 "Switch Off" 1 "Low speed/speed 1" 2 "speed 2" 3 "speed 3" 4 "speed 4" 5 "speed 5" 6 "speed 6" 7 "speed 7" 8 "speed 8" 9 "speed 9" 10 "speed 10" 11 "speed 11" 12 "speed 12" 13 "speed 13" 14 "High speed/speed 14" 15 "Invalid"  ;
VAL_ 825 RLS_RainfallLevel 0 "No Rain" 1 "Level 1" 2 "Level 2" 3 "Level 3" 4 "Level 4" 5 "Level 5" 6 "Level 6" 7 "Level 7" 8 "Level 8" 9 "Level 9" 10 "Level 10" 11 "Level 11" 12 "Level 12" 13 "Level 13" 14 "Init value" 15 "Invalid value"  ;
VAL_ 825 RLS_RSErr 0 "No Error" 1 "Error"  ;
VAL_ 825 RLS_LSErr 0 "No Error" 1 "Error"  ;
VAL_ 825 PM_AUTHPstState 0 "Disable" 1 "Enable"  ;
VAL_ 825 CCU_FuncReq_SentryMod 0 "OFF" 1 "SentryModeWake"  ;
VAL_ 825 CCU_ModeSuppressSts 0 "OFF" 1 "ON" 2 "UNKNOWN"  ;
VAL_ 825 RLS_HUTErr 0 "HUT sensor normal" 1 "HUT sensor error"  ;
VAL_ 825 SR_SunroofCurrentPst 255 "Undefined Sunroof position"  ;
VAL_ 291 ATWS_ATWSAlarmReq 0 "No Request" 1 "Alarm ON" 2 "Alarm OFF"  ;
VAL_ 291 ATWS_ATWSSt 0 "DisArm" 1 "PreArm" 2 "Partially Armed" 3 "Fully Armed" 4 "PreDisarm" 5 "Alarm"  ;
VAL_ 291 WW_FrontWasherCmd 0 "No Request" 1 "Active" 2 "Not Active"  ;
VAL_ 291 WW_FrtWiperAutoAvl 0 "Not Available" 1 "Available"  ;
VAL_ 291 WW_FrontWiperCmd_Speed 0 "no request" 1 "off" 2 "low speed" 3 "high speed"  ;
VAL_ 291 WW_RearWiperCtrlSt 0 "Off" 1 "Int" 2 "LowSpeed" 3 "HighSpeed" 4 "Auto"  ;
VAL_ 291 WW_FrontWiperCtrlSt 0 "Off" 1 "Int" 2 "LowSpeed" 3 "HighSpeed" 4 "Auto"  ;
VAL_ 291 WW_FrontWiperCtrlSrc 0 "No source" 1 "Switch" 2 "VirtualKey" 3 "VoiceControl" 4 "RLS" 5 "OtherLocalSystem" 6 "WiperSystem" 7 "ServiceConsumer"  ;
VAL_ 291 WW_RearWiperCtrlSrc 0 "No source" 1 "Switch" 2 "VirtualKey" 3 "VoiceControl" 4 "RLS" 5 "OtherLocalSystem" 6 "WiperSystem" 7 "ServiceConsumer"  ;
VAL_ 291 WW_RearCamWasherVKResp 0 "No response" 1 "Success" 2 "Fail"  ;
VAL_ 291 WW_RearCamWasherVRResp 0 "No response" 1 "Success" 2 "Fail"  ;
VAL_ 865 EL_ReverseLightCtrlCmd 0 "OFF" 1 "ON"  ;
VAL_ 865 EL_SideBrkLightCtrlCmd 0 "OFF" 1 "ON"  ;
VAL_ 865 EL_LeftLowBeamCtrlCmd 0 "OFF" 1 "ON"  ;
VAL_ 865 EL_RightLowBeamCtrlCmd 0 "OFF" 1 "ON"  ;
VAL_ 865 EL_PositionLightCtrlSource 0 "Not active" 1 "Group1" 2 "Group2" 3 "Group3" 4 "Reserved" 5 "Reserved" 6 "Reserved" 7 "Reserved"  ;
VAL_ 865 EL_LeftHighBeamCtrlCmd 0 "OFF" 1 "ON"  ;
VAL_ 865 EL_RightHighBeamCtrlCmd 0 "OFF" 1 "ON"  ;
VAL_ 865 EL_LowBeamCtrlSource 0 "Not active" 1 "Group1" 2 "Group2" 3 "Group3" 4 "Reserved" 5 "Reserved" 6 "Reserved" 7 "Reserved"  ;
VAL_ 865 EL_RearFogLightCtrlSource 0 "Not active" 1 "Group1" 2 "Group2" 3 "Group3" 4 "Reserved" 5 "Reserved" 6 "Reserved" 7 "Reserved"  ;
VAL_ 865 EL_HighBeamCtrlSource 0 "Not active" 1 "Group1" 2 "Group2" 3 "Group3" 4 "Reserved" 5 "Reserved" 6 "Reserved" 7 "Reserved"  ;
VAL_ 865 EL_FrontFogLightCtrlSource 0 "Not active" 1 "Group1" 2 "Group2" 3 "Group3" 4 "Reserved" 5 "Reserved" 6 "Reserved" 7 "Reserved"  ;
VAL_ 865 EL_LicencePlateLightCtrlSource 0 "Not active" 1 "Group1" 2 "Group2" 3 "Group3" 4 "Reserved" 5 "Reserved" 6 "Reserved" 7 "Reserved"  ;
VAL_ 865 EL_FlasherCtrlSource 0 "Not active" 1 "Group1_TurnLight" 2 "Group1_HazardLight" 3 "Group1_ReminderLight" 4 "Group2_HazardLight" 5 "Group2_ReminderLight" 6 "Group3" 7 "Reserved" 8 "Reserved" 9 "Reserved" 10 "Reserved" 11 "Reserved" 12 "Reserved" 13 "Reserved" 14 "Reserved" 15 "Reserved"  ;
VAL_ 865 EL_FADASLightCtrlCmd 0 "OFF" 1 "ON"  ;
VAL_ 865 EL_RADASLightCtrlCmd 0 "OFF" 1 "ON"  ;
VAL_ 865 EL_IHBColourSt 0 "No display" 1 "Active colour-blue" 2 "Standby colour-grey" 3 "Failure colour-yellow"  ;
VAL_ 865 EL_AutoHighBeamCtrlSt 0 "Not active" 1 "Active"  ;
VAL_ 865 EL_ADBEnable 0 "Disable" 1 "Enable"  ;
VAL_ 865 EL_ADC_2_VERFailFlag 0 "Not active" 1 "Active"  ;
VAL_ 865 EL_ADC_4_New_VERFailFlag 0 "Not active" 1 "Active"  ;
VAL_ 865 EL_ADC_8_VERFailFlag 0 "Not active" 1 "Active"  ;
VAL_ 865 EL_HeadLightLevelingSWSt 0 "Level 0" 1 "Level 1" 2 "Level 2" 3 "Level 3"  ;
VAL_ 865 EL_LeftTurnLightStForDisp 0 "OFF" 1 "ON"  ;
VAL_ 865 EL_RightTurnLightStForDisp 0 "OFF" 1 "ON"  ;
VAL_ 865 EL_PositionLightStForDisp 0 "OFF" 1 "ON"  ;
VAL_ 865 EL_FrontFogLightStForDisp 0 "OFF" 1 "ON"  ;
VAL_ 865 EL_RearFogLightStForDisp 0 "OFF" 1 "ON"  ;
VAL_ 865 EL_LowBeamStForDisp 0 "OFF" 1 "ON"  ;
VAL_ 865 EL_HighBeamStForDisp 0 "OFF" 1 "ON"  ;
VAL_ 865 EL_HeadLightSWSt 0 "OFF" 1 "Positon light" 2 "LowBeam" 3 "Auto"  ;
VAL_ 293 TPMS_FrontLeftTireBlowout 0 "No Function" 1 "Not Blowout" 2 "Blowout" 3 "Reserved"  ;
VAL_ 293 TPMS_FrontRightTireBlowout 0 "No Function" 1 "Not Blowout" 2 "Blowout" 3 "Reserved"  ;
VAL_ 293 TPMS_RearRightTireBlowout 0 "No Function" 1 "Not Blowout" 2 "Blowout" 3 "Reserved"  ;
VAL_ 293 TPMS_RearLeftTireBlowout 0 "No Function" 1 "Not Blowout" 2 "Blowout" 3 "Reserved"  ;
VAL_ 293 TPMS_FrontLeftTirePressure 0 "Invalid" 255 "Unknown"  ;
VAL_ 293 TPMS_FrontRightTirePressure 0 "Invalid" 255 "Unknown"  ;
VAL_ 293 TPMS_RearRightTirePressure 0 "Invalid" 255 "Unknown"  ;
VAL_ 293 TPMS_RearLeftTirePressure 0 "Invalid" 255 "Unknown"  ;
VAL_ 293 TPMS_TireWarningLamp 0 "NoWarning" 1 "Warning"  ;
VAL_ 293 TPMS_SystemWarningLamp 0 "NoWarning" 1 "Warning"  ;
VAL_ 294 LCK_DriverDoorAjarSt 0 "Closed" 1 "Opened"  ;
VAL_ 294 LCK_PassengerDoorAjarSt 0 "Closed" 1 "Opened"  ;
VAL_ 294 LCK_DriverDoorLockSt 0 "Locked" 1 "Unlocked"  ;
VAL_ 294 LCK_PassengerDoorLockSt 0 "Locked" 1 "Unlocked"  ;
VAL_ 294 LCK_VehicleDoorAjarSt 0 "ALLDoorsClosed" 1 "AllDoorsClosedAndHoodorTrunkOpened" 2 "AnyDoorOpened"  ;
VAL_ 294 LCK_VehicleDoorLockSt 0 "AllDoorLocked" 1 "PartialDoorUnlocked" 2 "AllDoorUnlocked"  ;
VAL_ 294 LCK_VehicleChildSaftyLockSt 0 "AllChildSaftyLocked" 1 "AnyChildSaftyUnlocked"  ;
VAL_ 294 LCK_VehicleChildSaftyLockedIndicate 0 "IndicateLampOff" 1 "IndicateLampOn"  ;
VAL_ 1359 CCU_NMCBV 0 "Node has not woken up the    network(passive wakeup);" 1 "Node has woken up the network(active wakeup)" 0 "NM PDU contains no Partial Network request information" 1 "NM PDU contains Partial Network request information"  ;
VAL_ 1359 CCU_NMWakeupOrigin 0 "Reserved" 1 "CAN channel 0" 2 "CAN channel 1" 3 "CAN channel 2" 4 "CAN channel 3" 5 "CAN channel 4" 6 "CAN channel 5" 7 "CAN channel 6" 8 "CAN channel 7" 9 "CAN channel 8" 10 "CAN channel 9" 11 "CAN channel 10" 12 "CAN channel 11" 13 "CAN channel 12" 14 "CAN channel 13" 15 "CAN channel 14" 16 "CAN channel 15" 17 "Reserved" 18 "Reserved" 19 "Reserved" 20 "AcoreRequest" 21 "Reserved" 22 "Reserved" 23 "Reserved" 24 "Reserved" 25 "Reserved" 26 "Reserved" 27 "Reserved" 28 "Reserved" 29 "Reserved" 30 "Reserved" 31 "Reserved" 32 "Reserved" 33 "Reserved" 34 "Reserved" 35 "Reserved" 36 "Reserved" 37 "Reserved" 38 "Reserved" 39 "Reserved" 40 "Reserved" 41 "Reserved" 42 "Reserved" 43 "Reserved" 44 "Reserved" 45 "Reserved" 46 "Reserved" 47 "Reserved" 48 "Reserved" 49 "Reserved" 50 "UsageModeSt" 51 "NMiDPSNMKeepAwakeFlag" 52 "NMEEMKeepAwakeFlag" 53 "NMEEMKeepAwakeFlag_Aux" 54 "NMVCUGlobalKeepAwakeFlag" 55 "NMVCUChargingKeepAwakeFlag（新能源，VCU_hcu）" 56 "DoIPActiveLineStatus" 57 "NMBMSGlobalKeepAwakeFlag" 58 "NMBMSChargingKeepAwakeFlag" 59 "NMBMSThermalRunawayKeepAwakeFlag（新能源，BMS）" 60 "Reserved" 61 "NMBMSThermalRunawayKeepAwakeFlag （动力，VCU_slccu）" 62 "NMVCUChargingKeepAwakeFlag（动力，VCU_slccu）" 63 "NMVCU2GlobalKeepAwakeFlag" 64 "NMVHMKeepAwakeFlag" 65 "Reserved" 66 "CSM_RC_KeepAwake" 67 "NMHVACKeepAwakeFlag（新能源，TMS）" 68 "Reserved" 69 "Reserved" 70 "BDC_NMBDCKeepAwakeFlag" 71 "NMTMSChargingKeepAwakeFlag" 72 "NMTMSGlobalKeepAwakeFlag" 73 "Reserved" 74 "Reserved" 75 "Reserved" 76 "Reserved" 77 "Reserved" 78 "Reserved" 79 "Reserved" 80 "Reserved" 81 "Reserved" 82 "Reserved" 83 "Reserved" 84 "Reserved" 85 "Reserved" 86 "Reserved" 87 "Reserved" 88 "Reserved" 89 "NMWCCDownloadRequest_RT1" 90 "CAN7_DiagMSG_ID ！" 91 "CAN7_DiagMSG_ID" 92 "Reserved" 93 "Reserved" 94 "Reserved" 95 "Reserved" 96 "Reserved" 97 "Reserved" 98 "Reserved" 99 "Reserved" 100 "NMATWSKeepAwakeFlag" 101 "NMExteriorLightKeepAwakeFlag" 102 "NMLockingKeepAwakeFlag" 103 "NMPWLKeepAwakeFlag" 104 "NMSunRoofKeepAwakeFlag" 105 "NMPLGKeepAwakeFlag" 106 "NMPowerOperatedDoorKeepAwakeFlag" 107 "MR_NMMirrorKeepAwakeFlag" 108 "NMSeatControlKeepAwakeFlag" 109 "NMHVACKeepAwakeFlag" 110 "NMHVACRLSLinAwakeFlag" 111 "NMAQCKeepAwakeFlag" 112 "NMTPMSKeepAwakeFlag" 113 "ILC_NMKeepAwakeFlag" 114 "NMESMKeepAwakeFlag" 115 "NMKAEKeepAwakeFlag" 116 "NMVRMPNCCharingKeepAwakeFlag" 140 "NMWCCDownloadReques_RT2"  ;
VAL_ 1359 CCU_PNCInformation0 0 "No request" 1 "Request" 0 "No request" 1 "Request" 0 "No request" 1 "Request" 0 "No request" 1 "Request" 1 "Request" 0 "No request" 1 "Request" 0 "No request" 1 "Request"  ;
VAL_ 1359 CCU_PNCInformation1 0 "No request" 1 "Request" 0 "No request" 1 "Request"  ;
VAL_ 615 BCS_FLWheelSpdVD 0 "Not valid" 1 "Valid"  ;
VAL_ 615 BCS_FLWheelRotatedDirection 0 "Forward" 1 "Backward"  ;
VAL_ 615 BCS_FLWheelRotatedDirectionVD 0 "Not valid" 1 "Valid"  ;
VAL_ 615 BCS_FRWheelSpdVD 0 "Not valid" 1 "Valid"  ;
VAL_ 615 BCS_FRWheelRotatedDirection 0 "Forward" 1 "Backward"  ;
VAL_ 615 BCS_FRWheelRotatedDirectionVD 0 "Not valid" 1 "Valid"  ;
VAL_ 615 BCS_RLWheelSpdVD 0 "Not valid" 1 "Valid"  ;
VAL_ 615 BCS_RLWheelRotatedDirection 0 "Forward" 1 "Backward"  ;
VAL_ 615 BCS_RLWheelRotatedDirectionVD 0 "Not valid" 1 "Valid"  ;
VAL_ 615 BCS_RRWheelSpdVD 0 "Not valid" 1 "Valid"  ;
VAL_ 615 BCS_RRWheelRotatedDirection 0 "Forward" 1 "Backward"  ;
VAL_ 615 BCS_RRWheelRotatedDirectionVD 0 "Not valid" 1 "Valid"  ;
VAL_ 615 BCS_HHCCtrlSt 0 "Not active" 1 "Active"  ;
VAL_ 615 BCS_HDCCtrlSt 0 "Off" 1 "On active braking" 2 "On not active braking" 3 "Not used"  ;
VAL_ 615 BCS_HDCErrSt 0 "No error" 1 "Error"  ;
VAL_ 615 BCS_FLWheelSpdEdgesSumVD 0 "Not valid" 1 "Valid"  ;
VAL_ 615 BCS_FRWheelSpdEdgesSumVD 0 "Not valid" 1 "Valid"  ;
VAL_ 615 BCS_RLWheelSpdEdgesSumVD 0 "Not valid" 1 "Valid"  ;
VAL_ 615 BCS_RRWheelSpdEdgesSumVD 0 "Not valid" 1 "Valid"  ;
VAL_ 615 BCS_FLWheelRotatedDirectionAPA 0 "Standstill" 1 "Forward" 2 "Backward" 3 "Unknown"  ;
VAL_ 615 BCS_FRWheelRotatedDirectionAPA 0 "Standstill" 1 "Forward" 2 "Backward" 3 "Unknown"  ;
VAL_ 615 BCS_RLWheelRotatedDirectionAPA 0 "Standstill" 1 "Forward" 2 "Backward" 3 "Unknown"  ;
VAL_ 615 BCS_RRWheelRotatedDirectionAPA 0 "Standstill" 1 "Forward" 2 "Backward" 3 "Unknown"  ;
VAL_ 615 BCS_ParkingReqToEPB 0 "No request" 1 "Release brake request" 2 "Lock brake request" 3 "Not used"  ;
VAL_ 615 BCS_VDCOff 0 "On" 1 "Off"  ;
VAL_ 615 BCS_AVHSt 0 "Not active" 1 "Active"  ;
VAL_ 615 BCS_AVHAvailable 0 "Not available" 1 "Available"  ;
VAL_ 615 BCS_TCSOff 0 "On" 1 "Off"  ;
VAL_ 615 BCS_BrakeOverHeat 0 "Not high" 1 "Temp too high"  ;
VAL_ 615 BCS_ABAactive 0 "Not active" 1 "Active"  ;
VAL_ 615 BCS_ABAavailable 0 "Not available" 1 "Available"  ;
VAL_ 615 BCS_ABPActive 0 "Not active" 1 "Active"  ;
VAL_ 615 BCS_ABPAvailable 0 "Not available" 1 "Available"  ;
VAL_ 615 BCS_AEBActive 0 "Not active" 1 "Active"  ;
VAL_ 615 BCS_AEBAvailable 0 "Not available" 1 "Available"  ;
VAL_ 615 BCS_AWBActive 0 "Not active" 1 "Active"  ;
VAL_ 615 BCS_AWBAvailable 0 "Not available" 1 "Available"  ;
VAL_ 615 BCS_VehicleStandStillSt 0 "Not standstill" 1 "standstill" 2 "Invalid (short unavailability, max 3s)" 3 "Not used"  ;
VAL_ 615 BCS_AEBBAActive 0 "Not active" 1 "Active"  ;
VAL_ 615 IPB_InputRodStrokeSt 0 "Valid/Init" 1 "Invalid/Default"  ;
VAL_ 615 BCS_RAEBActive 0 "Not active" 1 "Active"  ;
VAL_ 615 BCS_RAEBAvailable 0 "Not avaialbe" 1 "Available"  ;
VAL_ 615 IPB_PlungerPressureSt 0 "Valid/Init" 1 "Invalid/Default"  ;
VAL_ 615 BCS_2ParkDrvBrkOverrideFlg 0 "False" 1 "True"  ;
VAL_ 615 BCS_BrkTqCtrlAvlDrivingRdn 0 "BrakeBackupStrategyAvailability_None" 1 "BrakeBackupStrategyAvailability_Full" 2 "BrakeBackupStrategyAvailability_Fault" 3 "BrakeBackupStrategyAvailability_TestPending" 4 "BrakeBackupStrategyAvailability_NotInitialized" 5 "Reserved" 6 "Reserved" 7 "Reserved"  ;
VAL_ 615 BCS_BrkTqCtrlActvRdn 0 "BrakeMain_None" 1 "BrakeMain_APAactive" 2 "BrakeMain_ACCactive" 3 "Reserved"  ;
VAL_ 615 BCS_L3CommunicationVld 0 "Invalid" 1 "Valid"  ;
VAL_ 615 BCS_LFIActiveSt 0 "Not Active" 1 "Active"  ;
VAL_ 352 BCS_VehSpdVD 0 "Not Valid" 1 "Valid"  ;
VAL_ 352 BCS_EBDActiveSt 0 "Not active" 1 "Active"  ;
VAL_ 352 BCS_EBDFaultSt 0 "Not fault" 1 "Fault"  ;
VAL_ 352 BCS_ABSActiveSt 0 "Not active" 1 "Active"  ;
VAL_ 352 BCS_ABSFaultSt 0 "Not fault" 1 "Fault"  ;
VAL_ 352 BCS_TCSActiveSt 0 "Not active" 1 "Active"  ;
VAL_ 352 BCS_TCSFaultSt 0 "Not fault" 1 "Fault"  ;
VAL_ 352 BCS_VDCActiveSt 0 "Not active" 1 "Active"  ;
VAL_ 352 BCS_VDCFaultSt 0 "Not fault" 1 "Fault"  ;
VAL_ 352 BCS_PreAndRealVDCActiveSt 0 "Not active" 1 "Active"  ;
VAL_ 352 BCS_RegenModulationAvailable 0 "Not available" 1 "Available"  ;
VAL_ 352 BCS_RegenModuleActive 0 "Not Active" 1 "Active"  ;
VAL_ 352 BCS_RealTCSActiveSt 0 "Not active" 1 "Active"  ;
VAL_ 352 BCS_TargetRecpTorqRqSt 0 "NotIntialized" 1 "Normal" 2 "Faulty" 3 "Reserved"  ;
VAL_ 352 BCS_CrbsActive 0 "Not Active" 1 "Active"  ;
VAL_ 352 IPB_BrakePedalStsVld 0 "Invalid" 1 "Valid"  ;
VAL_ 352 IPB_BrakePedalSt 0 "Not_Pressed/Init/Default" 1 "Pressed" 2 "Reserved" 3 "Error"  ;
VAL_ 352 BCS_ESP2Park_DrvBrkOverrideFlg 0 "False" 1 "True"  ;
VAL_ 352 BCS_TargetRecpTorqRqFASt 0 "NotIntialized" 1 "Normal" 2 "Faulty" 3 "Reserved"  ;
VAL_ 352 BCS_TargetRecpTorqRqRASt 0 "NotIntialized" 1 "Normal" 2 "Faulty" 3 "Reserved"  ;
VAL_ 352 BCS_EngTorqDecActiveStRA 0 "Not active" 1 "Active"  ;
VAL_ 352 BCS_PrimBrkCDAAvailableSt 0 "CDA NotAvailable" 1 "CDA NotAvailable By Situation" 2 "CDA Available With Fault" 3 "CDA Available With Situation" 4 "CDA Available" 5 "Not used" 6 "Not used" 7 "Not used"  ;
VAL_ 352 BCS_PrimBrkCommuniSt 0 "Valid" 1 "Invalid"  ;
VAL_ 352 BCS_PrimBrkActiveSt 0 "L2 or L2++ NotActive" 1 "L2 Acitve" 2 "L2++ Active" 3 "Not used"  ;
VAL_ 352 BCS_2ParkCddApActiveVehHld 0 "False" 1 "True"  ;
VAL_ 352 BCS_2ParkAPCStatus 0 "Standby" 1 "Active_APA" 2 "Active_RPA" 3 "Active_AVP"  ;
VAL_ 352 BCS_2ParkAPAavailability 0 "NotAvailable" 1 "Available"  ;
VAL_ 352 BCS_2ParkRPAAVPavailability 0 "NotAvailable" 1 "Available" 2 "TestPending"  ;
VAL_ 352 BCS_2ParkAPCFailureSts 0 "no error" 1 "APC1(APA) driver not present" 2 "too high speed" 3 "unexpect EPB Apply" 4 "reserved" 5 "reserved" 6 "Error" 7 "APC24(RPA AVP) trigger without secure"  ;
VAL_ 352 BCS_APCMain2BackupReq 0 "NoReq" 1 "StopRequest"  ;
VAL_ 352 BCS_PrimBrkCtrlUsedChannel 0 "No Channel used" 1 "Main ADC com1 Used" 2 "Main ADC com2 Used" 3 "Back up IFC com1 Used"  ;
VAL_ 352 BCS_PrimBrkCDAActiveSt 0 "L2++ NotActive" 1 "L2++ Active"  ;
VAL_ 352 BCS_PrimBrkDecCtrlActiveSt 0 "NotActive" 1 "Active"  ;
VAL_ 352 BCS_PrimBrkCDDAvailableSt 0 "CDD NotAvailable" 1 "CDD NotAvailable By Situation" 2 "CDD Available" 3 "Reserve"  ;
VAL_ 352 BCS_EngTorqDecActiveStFA 0 "Not active" 1 "Active"  ;
VAL_ 352 BCS_EngTorqIncActiveStFA 0 "Not active" 1 "Active"  ;
VAL_ 352 IBCS_ADCNetErrorFb 0 "No Error" 1 "Main Net E2E Error" 2 "Sub Net E2E Error" 3 "Both Net E2E Error" 4 "Reserved" 5 "Reserved" 6 "Reserved" 7 "Reserved"  ;
VAL_ 352 IBCS_NetModeResp 0 "None" 1 "Main/sub Net active" 2 "Main/sub Net active with error" 3 "Reserved"  ;
